VERSION "HNNBNNNYNNNNNNNNNNNNNNNNNNNNNNNNNNNNNNNNNN/4/%%%/4/'%**4NNN///"

NS_ :

BS_:

BU_: BAP_Tester BedienDisp_vo BedienSG_hi CGS DDA Gateway Gateway_PAG GurtMikrofon OTA_FC ZR_High ZR_LIMU ZR_MIB_TOP_ab_Gen3 ZR_Standard

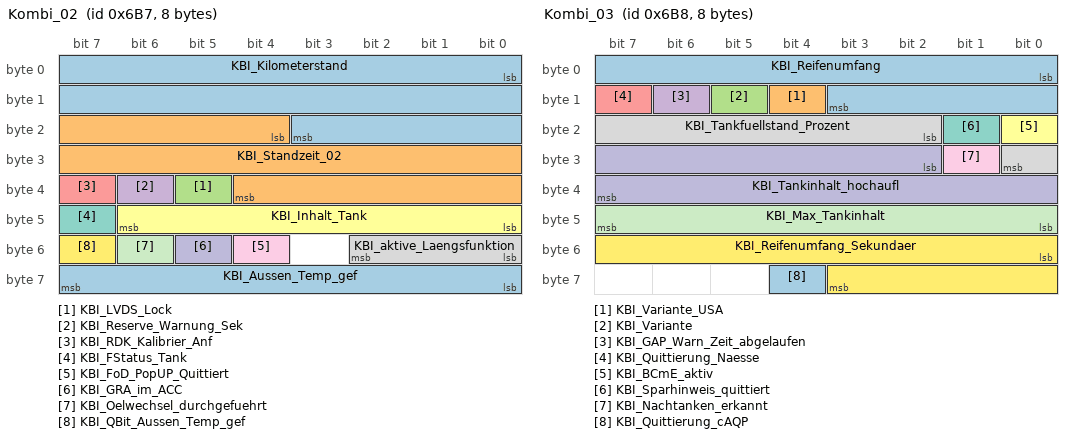
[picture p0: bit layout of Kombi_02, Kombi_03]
BO_ 1719 Kombi_02: 8 Gateway
 SG_ KBI_Kilometerstand : 0|20@1+ (1,0) [0|1048573] "Unit_KiloMeter"  Vector__XXX
 SG_ KBI_Standzeit_02 : 20|17@1+ (1,0) [0|131068] "Unit_Secon"  BedienDisp_vo,BedienSG_hi,ZR_High,ZR_Standard
 SG_ KBI_LVDS_Lock : 37|1@1+ (1.0,0.0) [0.0|1] ""  ZR_High
 SG_ KBI_Reserve_Warnung_Sek : 38|1@1+ (1.0,0.0) [0.0|1] ""  ZR_High,ZR_LIMU,ZR_MIB_TOP_ab_Gen3,ZR_Standard
 SG_ KBI_RDK_Kalibrier_Anf : 39|1@1+ (1.0,0.0) [0.0|1] ""  Vector__XXX
 SG_ KBI_Inhalt_Tank : 40|7@1+ (1,0) [0|125] "Unit_Liter"  Vector__XXX
 SG_ KBI_FStatus_Tank : 47|1@1+ (1.0,0.0) [0.0|1] ""  ZR_High,ZR_LIMU,ZR_MIB_TOP_ab_Gen3,ZR_Standard
 SG_ KBI_aktive_Laengsfunktion : 48|3@1+ (1.0,0.0) [0.0|7] ""  ZR_High
 SG_ KBI_FoD_PopUP_Quittiert : 52|1@1+ (1.0,0.0) [0.0|1] ""  Vector__XXX
 SG_ KBI_GRA_im_ACC : 53|1@1+ (1.0,0.0) [0.0|1] ""  Vector__XXX
 SG_ KBI_Oelwechsel_durchgefuehrt : 54|1@1+ (1.0,0.0) [0.0|1] ""  OTA_FC,ZR_High
 SG_ KBI_QBit_Aussen_Temp_gef : 55|1@1+ (1.0,0.0) [0.0|1] ""  BedienDisp_vo,BedienSG_hi,ZR_High
 SG_ KBI_Aussen_Temp_gef : 56|8@1+ (0.5,-50) [-50.0|75.0] "Unit_DegreCelsi"  BedienDisp_vo,BedienSG_hi,OTA_FC,ZR_Standard

BO_ 1720 Kombi_03: 8 Gateway
 SG_ KBI_Reifenumfang : 0|12@1+ (1,0) [0|4095] "Unit_MilliMeter"  ZR_High,ZR_Standard
 SG_ KBI_Variante_USA : 12|1@1+ (1.0,0.0) [0.0|1] ""  BedienSG_hi,ZR_High
 SG_ KBI_Variante : 13|1@1+ (1.0,0.0) [0.0|1] ""  BedienSG_hi
 SG_ KBI_GAP_Warn_Zeit_abgelaufen : 14|1@1+ (1.0,0.0) [0.0|1] ""  Vector__XXX
 SG_ KBI_Quittierung_Naesse : 15|1@1+ (1.0,0.0) [0.0|1] ""  Vector__XXX
 SG_ KBI_BCmE_aktiv : 16|1@1+ (1.0,0.0) [0.0|1] ""  Vector__XXX
 SG_ KBI_Sparhinweis_quittiert : 17|1@1+ (1.0,0.0) [0.0|1] ""  Vector__XXX
 SG_ KBI_Tankfuellstand_Prozent : 18|7@1+ (1,0) [0|100] "Unit_PerCent"  BedienSG_hi,ZR_High
 SG_ KBI_Nachtanken_erkannt : 25|1@1+ (1.0,0.0) [0.0|1] ""  ZR_High,ZR_MIB_TOP_ab_Gen3
 SG_ KBI_Tankinhalt_hochaufl : 26|14@1+ (0.01,0) [0.00|163.81] "Unit_Liter"  Vector__XXX
 SG_ KBI_Max_Tankinhalt : 40|8@1+ (0.5,0) [0.0|126.5] ""  ZR_High
 SG_ KBI_Reifenumfang_Sekundaer : 48|12@1+ (1,0) [0|4095] "Unit_MilliMeter"  Vector__XXX
 SG_ KBI_Quittierung_cAQP : 60|1@1+ (1.0,0.0) [0.0|1] ""  Vector__XXX

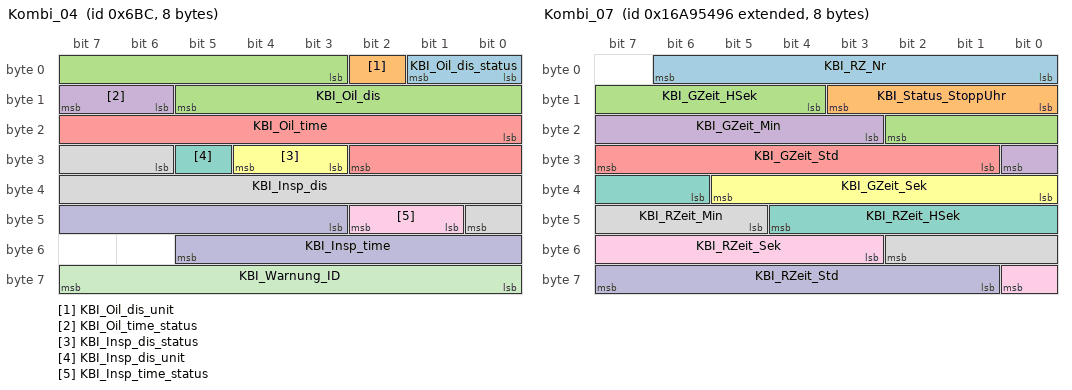
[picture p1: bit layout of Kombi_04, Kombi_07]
BO_ 1724 Kombi_04: 8 Gateway
 SG_ KBI_Oil_dis_status : 0|2@1+ (1.0,0.0) [0.0|3] ""  ZR_High
 SG_ KBI_Oil_dis_unit : 2|1@1+ (1.0,0.0) [0.0|1] ""  ZR_High
 SG_ KBI_Oil_dis : 3|11@1+ (100,0) [0|204700] ""  ZR_High
 SG_ KBI_Oil_time_status : 14|2@1+ (1.0,0.0) [0.0|3] ""  ZR_High
 SG_ KBI_Oil_time : 16|11@1+ (1,0) [0|2047] ""  ZR_High
 SG_ KBI_Insp_dis_status : 27|2@1+ (1.0,0.0) [0.0|3] ""  ZR_High
 SG_ KBI_Insp_dis_unit : 29|1@1+ (1.0,0.0) [0.0|1] ""  ZR_High
 SG_ KBI_Insp_dis : 30|11@1+ (100,0) [0|204700] ""  ZR_High
 SG_ KBI_Insp_time_status : 41|2@1+ (1.0,0.0) [0.0|3] ""  ZR_High
 SG_ KBI_Insp_time : 43|11@1+ (1,0) [0|2047] ""  ZR_High
 SG_ KBI_Warnung_ID : 56|8@1+ (1,0) [0|255] ""  ZR_High

BO_ 2527679638 Kombi_07: 8 Gateway
 SG_ KBI_RZ_Nr : 0|7@1+ (1,0) [0|99] ""  ZR_High,ZR_LIMU,ZR_MIB_TOP_ab_Gen3
 SG_ KBI_Status_StoppUhr : 8|4@1+ (1.0,0.0) [0.0|15] ""  BedienDisp_vo,ZR_High,ZR_LIMU,ZR_MIB_TOP_ab_Gen3
 SG_ KBI_GZeit_HSek : 12|7@1+ (1,0) [0|99] ""  BedienDisp_vo,ZR_High,ZR_LIMU,ZR_MIB_TOP_ab_Gen3
 SG_ KBI_GZeit_Min : 19|6@1+ (1,0) [0|59] "Unit_Minut"  BedienDisp_vo,ZR_High,ZR_LIMU,ZR_MIB_TOP_ab_Gen3
 SG_ KBI_GZeit_Std : 25|7@1+ (1,0) [0|99] "Unit_Hours"  BedienDisp_vo,ZR_High,ZR_LIMU,ZR_MIB_TOP_ab_Gen3
 SG_ KBI_GZeit_Sek : 32|6@1+ (1,0) [0|59] "Unit_Secon"  BedienDisp_vo,ZR_High,ZR_LIMU,ZR_MIB_TOP_ab_Gen3
 SG_ KBI_RZeit_HSek : 38|7@1+ (1,0) [0|99] ""  ZR_High,ZR_LIMU,ZR_MIB_TOP_ab_Gen3
 SG_ KBI_RZeit_Min : 45|6@1+ (1,0) [0|59] "Unit_Minut"  ZR_High,ZR_LIMU,ZR_MIB_TOP_ab_Gen3
 SG_ KBI_RZeit_Sek : 51|6@1+ (1,0) [0|59] "Unit_Secon"  ZR_High,ZR_LIMU,ZR_MIB_TOP_ab_Gen3
 SG_ KBI_RZeit_Std : 57|7@1+ (1,0) [0|99] "Unit_Hours"  ZR_High,ZR_LIMU,ZR_MIB_TOP_ab_Gen3

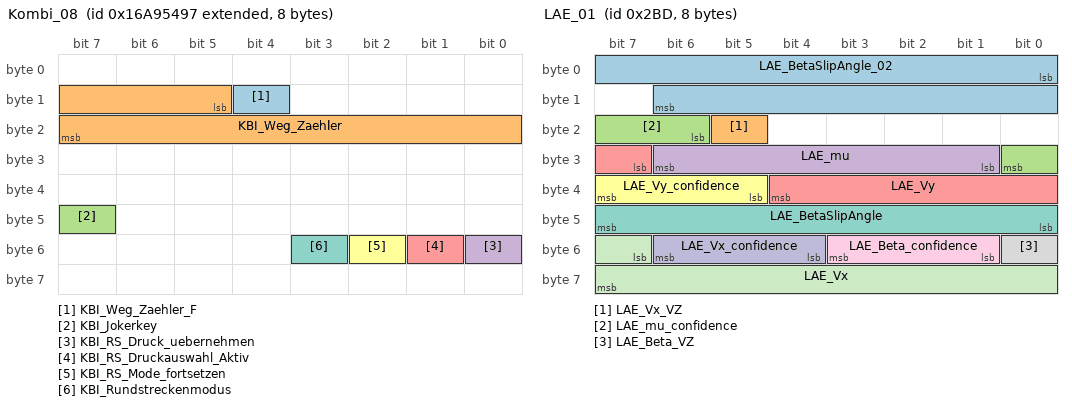
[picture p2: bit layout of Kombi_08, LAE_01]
BO_ 2527679639 Kombi_08: 8 Gateway
 SG_ KBI_Weg_Zaehler_F : 12|1@1+ (1.0,0.0) [0.0|1] ""  ZR_High,ZR_LIMU,ZR_MIB_TOP_ab_Gen3
 SG_ KBI_Weg_Zaehler : 13|11@1+ (1,0) [0|2047] "Unit_Meter"  ZR_High,ZR_LIMU,ZR_MIB_TOP_ab_Gen3
 SG_ KBI_Jokerkey : 47|1@1+ (1.0,0.0) [0.0|1] ""  ZR_LIMU,ZR_MIB_TOP_ab_Gen3
 SG_ KBI_RS_Druck_uebernehmen : 48|1@1+ (1.0,0.0) [0.0|1] ""  Vector__XXX
 SG_ KBI_RS_Druckauswahl_Aktiv : 49|1@1+ (1.0,0.0) [0.0|1] ""  Vector__XXX
 SG_ KBI_RS_Mode_fortsetzen : 50|1@1+ (1.0,0.0) [0.0|1] ""  Vector__XXX
 SG_ KBI_Rundstreckenmodus : 51|1@1+ (1.0,0.0) [0.0|1] ""  Vector__XXX

BO_ 2527679656 Kombi_23: 8 Gateway
 SG_ KBI_StartupAnimation : 61|3@1+ (1.0,0.0) [0.0|7] ""  ZR_High

BO_ 2549875055 KS_AMP_Req: 8 Gateway
 SG_ KS_AMP_Req_Data : 0|64@1+ (1.0,0.0) [0.0|18446744073709551615] ""  ZR_High,ZR_MIB_TOP_ab_Gen3,ZR_Standard

BO_ 2550006127 KS_AMP_Resp: 8 ZR_High
 SG_ KS_AMP_Resp_Data : 0|64@1+ (1.0,0.0) [0.0|18446744073709551615] ""  Gateway,Gateway_PAG

BO_ 2549875059 KS_Info_El_Req: 8 Gateway
 SG_ KS_Info_El_Req_Data : 0|64@1+ (1.0,0.0) [0.0|18446744073709551615] ""  ZR_High,ZR_MIB_TOP_ab_Gen3,ZR_Standard

BO_ 2550006131 KS_Info_El_Resp: 8 ZR_High
 SG_ KS_Info_El_Resp_Data : 0|64@1+ (1.0,0.0) [0.0|18446744073709551615] ""  Gateway,Gateway_PAG

BO_ 2549875056 KS_Laufwerke_Req: 8 Gateway
 SG_ KS_Laufwerke_Req_Data : 0|64@1+ (1.0,0.0) [0.0|18446744073709551615] ""  ZR_High,ZR_MIB_TOP_ab_Gen3,ZR_Standard

BO_ 2550006128 KS_Laufwerke_Resp: 8 ZR_High
 SG_ KS_Laufwerke_Resp_Data : 0|64@1+ (1.0,0.0) [0.0|18446744073709551615] ""  Gateway,Gateway_PAG

BO_ 2549875053 KS_TV_Tuner_Req: 8 Gateway
 SG_ KS_TV_Tuner_Req_Data : 0|64@1+ (1.0,0.0) [0.0|18446744073709551615] ""  ZR_High,ZR_MIB_TOP_ab_Gen3,ZR_Standard

BO_ 2550006125 KS_TV_Tuner_Resp: 8 ZR_High
 SG_ KS_TV_Tuner_Resp_Data : 0|64@1+ (1.0,0.0) [0.0|18446744073709551615] ""  Gateway,Gateway_PAG

BO_ 701 LAE_01: 8 Gateway
 SG_ LAE_BetaSlipAngle_02 : 0|15@1+ (0.01,0) [0.00|327.65] "Unit_DegreOfArc"  ZR_LIMU
 SG_ LAE_Vx_VZ : 21|1@1+ (1.0,0.0) [0.0|1] ""  ZR_LIMU
 SG_ LAE_mu_confidence : 22|3@1+ (1.0,0.0) [0.0|7] ""  ZR_LIMU
 SG_ LAE_mu : 25|6@1+ (0.05,0) [0.00|3.05] "Unit_None"  ZR_LIMU
 SG_ LAE_Vy : 31|6@1+ (0.491803,0) [0.000000|29.999983] "Unit_MeterPerSecon"  ZR_LIMU
 SG_ LAE_Vy_confidence : 37|3@1+ (1.0,0.0) [0.0|7] ""  ZR_LIMU
 SG_ LAE_BetaSlipAngle : 40|8@1+ (0.711462451,0) [0E-9|180.000000103] "Unit_DegreOfArc"  ZR_LIMU
 SG_ LAE_Beta_VZ : 48|1@1+ (1.0,0.0) [0.0|1] ""  ZR_LIMU
 SG_ LAE_Beta_confidence : 49|3@1+ (1.0,0.0) [0.0|7] ""  ZR_LIMU
 SG_ LAE_Vx_confidence : 52|3@1+ (1.0,0.0) [0.0|7] ""  ZR_LIMU
 SG_ LAE_Vx : 55|9@1+ (0.25540275,0) [0E-8|129.99999975] "Unit_MeterPerSecon"  ZR_LIMU

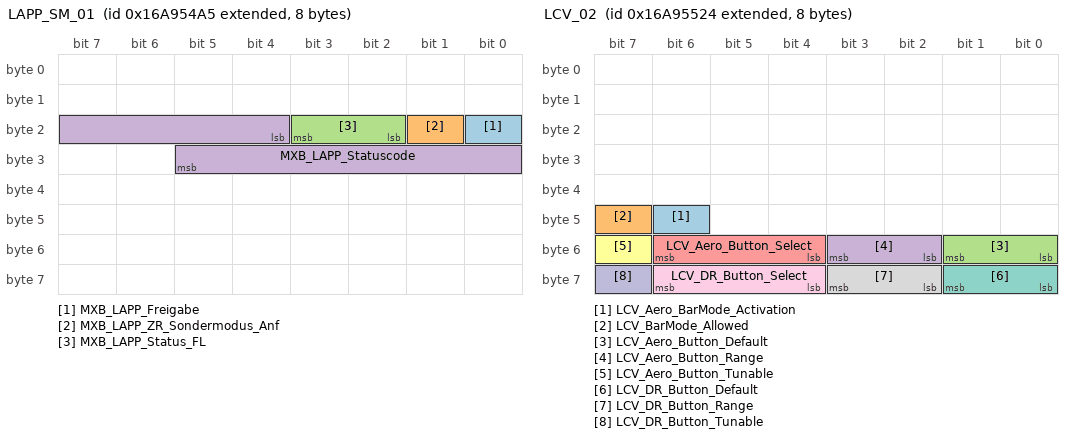
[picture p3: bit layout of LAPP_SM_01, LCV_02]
BO_ 2527679653 LAPP_SM_01: 8 Gateway
 SG_ MXB_LAPP_Freigabe : 16|1@1+ (1.0,0.0) [0.0|1] ""  DDA
 SG_ MXB_LAPP_ZR_Sondermodus_Anf : 17|1@1+ (1.0,0.0) [0.0|1] ""  DDA,ZR_High,ZR_Standard
 SG_ MXB_LAPP_Status_FL : 18|2@1+ (1.0,0.0) [0.0|3] ""  DDA
 SG_ MXB_LAPP_Statuscode : 20|10@1+ (1,0) [0|1023] "Unit_None"  DDA

BO_ 2463978818 LCV_01: 8 Gateway
 SG_ LCV_01_CRC : 0|8@1+ (1,0) [0|255] ""  Vector__XXX
 SG_ LCV_01_BZ : 8|4@1+ (1,0) [0|15] ""  Vector__XXX
 SG_ LCV_ESP_Zuschaltung : 12|1@1+ (1.0,0.0) [0.0|1] ""  Vector__XXX
 SG_ LCV_BrakeGongTemp : 13|1@1+ (1.0,0.0) [0.0|1] ""  Vector__XXX
 SG_ BTM_BrakeSystem_Status : 14|4@1+ (1.0,0.0) [0.0|15] ""  ZR_LIMU
 SG_ BTM_BrakeSystem_Text : 18|4@1+ (1.0,0.0) [0.0|15] ""  ZR_LIMU
 SG_ BTM_BrakeSystem_Warnlampe : 22|1@1+ (1.0,0.0) [0.0|1] ""  ZR_LIMU
 SG_ LCV_Aero_EngineBay_Cooling : 23|1@1+ (1.0,0.0) [0.0|1] ""  Vector__XXX
 SG_ LCV_Aero_Front_System_Status : 24|3@1+ (1.0,0.0) [0.0|7] ""  Vector__XXX
 SG_ LCV_Aero_Rear_System_Status : 27|3@1+ (1.0,0.0) [0.0|7] ""  Vector__XXX
 SG_ LCV_DR_Systemstatus : 30|3@1+ (1.0,0.0) [0.0|7] ""  Vector__XXX
 SG_ LCV_DR_Text : 33|3@1+ (1.0,0.0) [0.0|7] ""  Vector__XXX
 SG_ LCV_DR_Warnlampe : 36|2@1+ (1.0,0.0) [0.0|3] ""  Vector__XXX
 SG_ LCV_Lift_Status : 38|4@1+ (1.0,0.0) [0.0|15] ""  ZR_LIMU
 SG_ LCV_Lift_Text : 42|3@1+ (1.0,0.0) [0.0|7] ""  Vector__XXX
 SG_ LCV_Lift_Warnlampe_Status : 45|2@1+ (1.0,0.0) [0.0|3] ""  Vector__XXX
 SG_ LCV_Aero_Perf_Limit_Speed : 47|8@1+ (1,100) [100|353] "Unit_KiloMeterPerHour"  Vector__XXX
 SG_ LCV_Aero_Perf_Limit : 55|1@1+ (1.0,0.0) [0.0|1] ""  Vector__XXX
 SG_ LCV_HD_offen : 56|1@1+ (1.0,0.0) [0.0|1] ""  ZR_LIMU

BO_ 2527679780 LCV_02: 8 Gateway
 SG_ LCV_Aero_BarMode_Activation : 46|1@1+ (1.0,0.0) [0.0|1] ""  ZR_LIMU
 SG_ LCV_BarMode_Allowed : 47|1@1+ (1.0,0.0) [0.0|1] ""  Vector__XXX
 SG_ LCV_Aero_Button_Default : 48|2@1+ (1.0,0.0) [0.0|3] ""  ZR_LIMU
 SG_ LCV_Aero_Button_Range : 50|2@1+ (1.0,0.0) [0.0|3] ""  ZR_LIMU
 SG_ LCV_Aero_Button_Select : 52|3@1+ (1.0,0.0) [0.0|7] ""  ZR_LIMU
 SG_ LCV_Aero_Button_Tunable : 55|1@1+ (1.0,0.0) [0.0|1] ""  ZR_LIMU
 SG_ LCV_DR_Button_Default : 56|2@1+ (1.0,0.0) [0.0|3] ""  ZR_LIMU
 SG_ LCV_DR_Button_Range : 58|2@1+ (1.0,0.0) [0.0|3] ""  ZR_LIMU
 SG_ LCV_DR_Button_Select : 60|3@1+ (1.0,0.0) [0.0|7] ""  ZR_LIMU
 SG_ LCV_DR_Button_Tunable : 63|1@1+ (1.0,0.0) [0.0|1] ""  ZR_LIMU

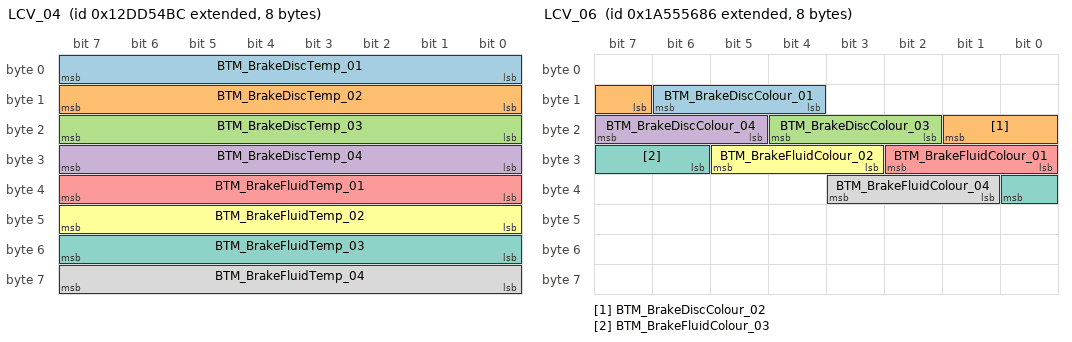
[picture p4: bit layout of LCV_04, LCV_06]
BO_ 2463978684 LCV_04: 8 Gateway
 SG_ BTM_BrakeDiscTemp_01 : 0|8@1+ (10,-30) [-30|2500] "Unit_DegreCelsi"  ZR_LIMU
 SG_ BTM_BrakeDiscTemp_02 : 8|8@1+ (10,-30) [-30|2500] "Unit_DegreCelsi"  ZR_LIMU
 SG_ BTM_BrakeDiscTemp_03 : 16|8@1+ (10,-30) [-30|2500] "Unit_DegreCelsi"  ZR_LIMU
 SG_ BTM_BrakeDiscTemp_04 : 24|8@1+ (10,-30) [-30|2500] "Unit_DegreCelsi"  ZR_LIMU
 SG_ BTM_BrakeFluidTemp_01 : 32|8@1+ (2,-30) [-30|476] "Unit_DegreCelsi"  ZR_LIMU
 SG_ BTM_BrakeFluidTemp_02 : 40|8@1+ (2,-30) [-30|476] "Unit_DegreCelsi"  ZR_LIMU
 SG_ BTM_BrakeFluidTemp_03 : 48|8@1+ (2,-30) [-30|476] "Unit_DegreCelsi"  ZR_LIMU
 SG_ BTM_BrakeFluidTemp_04 : 56|8@1+ (2,-30) [-30|476] "Unit_DegreCelsi"  ZR_LIMU

BO_ 548 LCV_05: 8 Gateway
 SG_ LCV_Aero_Front_Ratio : 12|7@1+ (1,0) [0|125] "Unit_None"  ZR_LIMU
 SG_ LCV_Aero_Long_Ratio : 19|7@1+ (1,0) [0|125] "Unit_None"  ZR_LIMU

BO_ 2589283974 LCV_06: 8 Gateway
 SG_ BTM_BrakeDiscColour_01 : 12|3@1+ (1.0,0.0) [0.0|7] ""  ZR_LIMU
 SG_ BTM_BrakeDiscColour_02 : 15|3@1+ (1.0,0.0) [0.0|7] ""  ZR_LIMU
 SG_ BTM_BrakeDiscColour_03 : 18|3@1+ (1.0,0.0) [0.0|7] ""  ZR_LIMU
 SG_ BTM_BrakeDiscColour_04 : 21|3@1+ (1.0,0.0) [0.0|7] ""  ZR_LIMU
 SG_ BTM_BrakeFluidColour_01 : 24|3@1+ (1.0,0.0) [0.0|7] ""  ZR_LIMU
 SG_ BTM_BrakeFluidColour_02 : 27|3@1+ (1.0,0.0) [0.0|7] ""  ZR_LIMU
 SG_ BTM_BrakeFluidColour_03 : 30|3@1+ (1.0,0.0) [0.0|7] ""  ZR_LIMU
 SG_ BTM_BrakeFluidColour_04 : 33|3@1+ (1.0,0.0) [0.0|7] ""  ZR_LIMU

BO_ 981 Licht_Anf_01: 8 Gateway
 SG_ Licht_Anf_01_CRC : 0|8@1+ (1,0) [0|255] ""  Vector__XXX
 SG_ Licht_Anf_01_BZ : 8|4@1+ (1,0) [0|15] ""  Vector__XXX
 SG_ BCM1_Kurvenlicht_links_Anf : 12|1@1+ (1.0,0.0) [0.0|1] ""  ZR_High
 SG_ BCM1_Kurvenlicht_rechts_Anf : 13|1@1+ (1.0,0.0) [0.0|1] ""  ZR_High
 SG_ BCM1_Standlicht_Anf : 14|1@1+ (1.0,0.0) [0.0|1] ""  ZR_High
 SG_ BCM1_Abblendlicht_Anf : 15|1@1+ (1.0,0.0) [0.0|1] ""  OTA_FC,ZR_High
 SG_ BCM1_Fernlicht_Anf : 16|1@1+ (1.0,0.0) [0.0|1] ""  ZR_High
 SG_ BCM1_Nebellicht_Anf : 17|1@1+ (1.0,0.0) [0.0|1] ""  ZR_High
 SG_ BCM1_Parklicht_li_Anf : 18|1@1+ (1.0,0.0) [0.0|1] ""  ZR_High
 SG_ BCM1_Parklicht_re_Anf : 19|1@1+ (1.0,0.0) [0.0|1] ""  ZR_High
 SG_ BCM1_Nebelschluss_Ahg_Anf : 20|1@1+ (1.0,0.0) [0.0|1] ""  ZR_High
 SG_ BCM1_Nebelschluss_Fzg_Anf : 21|1@1+ (1.0,0.0) [0.0|1] ""  ZR_High
 SG_ BCM1_Schlusslicht_Anf : 22|1@1+ (1.0,0.0) [0.0|1] ""  ZR_High
 SG_ BCM_Rueckfahrlicht_Anf : 23|1@1+ (1.0,0.0) [0.0|1] ""  ZR_High,ZR_MIB_TOP_ab_Gen3,ZR_Standard
 SG_ BCM1_Signaturlicht_Anf : 24|1@1+ (1.0,0.0) [0.0|1] ""  Vector__XXX
 SG_ BCM1_Umfeldleuchten_Anf : 25|1@1+ (1.0,0.0) [0.0|1] ""  ZR_High
 SG_ BCM1_Tagfahrlicht_Anf : 26|1@1+ (1.0,0.0) [0.0|1] ""  ZR_High
 SG_ BCM1_Regenlicht_Anf : 27|1@1+ (1.0,0.0) [0.0|1] ""  ZR_High
 SG_ BCM1_Autobahnlicht_Anf : 28|1@1+ (1.0,0.0) [0.0|1] ""  ZR_High
 SG_ BCM1_Touristen_Licht_Anf : 29|1@1+ (1.0,0.0) [0.0|1] ""  ZR_High
 SG_ BCM1_CH_aktiv : 30|1@1+ (1.0,0.0) [0.0|1] ""  ZR_High
 SG_ BCM1_LH_aktiv : 31|1@1+ (1.0,0.0) [0.0|1] ""  ZR_High
 SG_ BCM1_Gleitende_Leuchtw_Anf : 32|1@1+ (1.0,0.0) [0.0|1] ""  ZR_High
 SG_ BCM1_GLW_Fernlicht_Anf : 33|1@1+ (1.0,0.0) [0.0|1] ""  ZR_High
 SG_ BCM1_Adaptive_Lichtvert_Anf : 34|1@1+ (1.0,0.0) [0.0|1] ""  ZR_High
 SG_ BCM1_FoD_Sperrung_WiBli : 35|2@1+ (1.0,0.0) [0.0|3] ""  Vector__XXX
 SG_ BCM1_FOD_Sperrung_Animationen_HL : 37|2@1+ (1.0,0.0) [0.0|3] ""  Vector__XXX
 SG_ BCM1_Animationssperrung : 39|1@1+ (1.0,0.0) [0.0|1] ""  Vector__XXX
 SG_ BCM1_CH_LH_aktiv : 40|1@1+ (1.0,0.0) [0.0|1] ""  ZR_High
 SG_ BCM1_Allwetterlicht_Anf : 41|1@1+ (1.0,0.0) [0.0|1] ""  ZR_High
 SG_ BCM1_Schlusslicht_Signatur : 60|4@1+ (1.0,0.0) [0.0|15] ""  Vector__XXX

BO_ 982 Licht_hinten_01: 8 Gateway
 SG_ BCM2_Bremsl_durch_ECD : 5|1@1+ (1.0,0.0) [0.0|1] ""  OTA_FC,ZR_High
 SG_ LH_Aussenlicht_def : 7|1@1+ (1.0,0.0) [0.0|1] ""  ZR_High
 SG_ LH_Standlicht_H_aktiv : 8|1@1+ (1.0,0.0) [0.0|1] ""  OTA_FC,ZR_High
 SG_ LH_Parklicht_HL_aktiv : 9|1@1+ (1.0,0.0) [0.0|1] ""  OTA_FC,ZR_High
 SG_ LH_Parklicht_HR_aktiv : 10|1@1+ (1.0,0.0) [0.0|1] ""  OTA_FC,ZR_High
 SG_ LH_Bremslicht_H_aktiv : 11|1@1+ (1.0,0.0) [0.0|1] ""  OTA_FC,ZR_High
 SG_ LH_Nebelschluss_aktiv : 12|1@1+ (1.0,0.0) [0.0|1] ""  OTA_FC,ZR_High
 SG_ LH_Rueckfahrlicht_aktiv : 13|1@1+ (1.0,0.0) [0.0|1] ""  OTA_FC,ZR_High
 SG_ LH_Blinker_HL_akt : 14|1@1+ (1.0,0.0) [0.0|1] ""  OTA_FC,ZR_High
 SG_ LH_Blinker_HR_akt : 15|1@1+ (1.0,0.0) [0.0|1] ""  OTA_FC,ZR_High
 SG_ LH_Blinker_li_def : 16|1@1+ (1.0,0.0) [0.0|1] ""  ZR_High
 SG_ LH_Bremsl_li_def : 17|1@1+ (1.0,0.0) [0.0|1] ""  ZR_High
 SG_ LH_Schlusslicht_li_def : 18|1@1+ (1.0,0.0) [0.0|1] ""  ZR_High
 SG_ LH_Rueckf_li_def : 19|1@1+ (1.0,0.0) [0.0|1] ""  ZR_High
 SG_ LH_Nebel_li_def : 20|1@1+ (1.0,0.0) [0.0|1] ""  ZR_High
 SG_ LH_Schluss_Brems_Nebel_li_def : 21|1@1+ (1.0,0.0) [0.0|1] ""  ZR_High
 SG_ LH_Schluss_Brems_Nebel_re_def : 22|1@1+ (1.0,0.0) [0.0|1] ""  ZR_High
 SG_ LH_Zusatzschlussl_def : 23|1@1+ (1.0,0.0) [0.0|1] ""  Vector__XXX
 SG_ LH_Schluss_Brems_li_def : 24|1@1+ (1.0,0.0) [0.0|1] ""  ZR_High
 SG_ LH_Schluss_Nebel_li_def : 25|1@1+ (1.0,0.0) [0.0|1] ""  ZR_High
 SG_ LH_SL_BRL_BLK_li_def : 26|1@1+ (1.0,0.0) [0.0|1] ""  ZR_High
 SG_ LH_Brems_Blk_li_def : 27|1@1+ (1.0,0.0) [0.0|1] ""  Vector__XXX
 SG_ LH_Diag_Status_re_def : 28|1@1+ (1.0,0.0) [0.0|1] ""  ZR_High
 SG_ LH_Diag_Status_li_def : 29|1@1+ (1.0,0.0) [0.0|1] ""  ZR_High
 SG_ LH_Diag_LED_li_def : 30|1@1+ (1.0,0.0) [0.0|1] ""  ZR_High
 SG_ LH_Diag_LED_re_def : 31|1@1+ (1.0,0.0) [0.0|1] ""  ZR_High
 SG_ LH_Blinker_re_def : 32|1@1+ (1.0,0.0) [0.0|1] ""  ZR_High
 SG_ LH_Bremsl_re_def : 33|1@1+ (1.0,0.0) [0.0|1] ""  ZR_High
 SG_ LH_Schlusslicht_re_def : 34|1@1+ (1.0,0.0) [0.0|1] ""  ZR_High
 SG_ LH_Rueckf_re_def : 35|1@1+ (1.0,0.0) [0.0|1] ""  ZR_High
 SG_ LH_Nebel_re_def : 36|1@1+ (1.0,0.0) [0.0|1] ""  ZR_High
 SG_ LH_Schluss_Brems_mi_def : 37|1@1+ (1.0,0.0) [0.0|1] ""  Vector__XXX
 SG_ LH_Schluss_Brems_re_def : 40|1@1+ (1.0,0.0) [0.0|1] ""  ZR_High
 SG_ LH_Schluss_Nebel_re_def : 41|1@1+ (1.0,0.0) [0.0|1] ""  ZR_High
 SG_ LH_SL_BRL_BLK_re_def : 42|1@1+ (1.0,0.0) [0.0|1] ""  ZR_High
 SG_ LH_Brems_Blk_re_def : 43|1@1+ (1.0,0.0) [0.0|1] ""  ZR_High
 SG_ LH_Kennzl_def : 48|1@1+ (1.0,0.0) [0.0|1] ""  ZR_High
 SG_ LH_3_Bremsl_def : 49|1@1+ (1.0,0.0) [0.0|1] ""  ZR_High
 SG_ LH_Nebel_mi_def : 50|1@1+ (1.0,0.0) [0.0|1] ""  ZR_High
 SG_ LH_Rueckf_mi_def : 51|1@1+ (1.0,0.0) [0.0|1] ""  ZR_High
 SG_ LH_Schlusslicht_mi_def : 52|1@1+ (1.0,0.0) [0.0|1] ""  Vector__XXX
 SG_ LH_Bremsl_mi_def : 53|1@1+ (1.0,0.0) [0.0|1] ""  Vector__XXX
 SG_ LH_Bremsl_li_ges_def : 54|1@1+ (1.0,0.0) [0.0|1] ""  ZR_High
 SG_ LH_Bremsl_re_ges_def : 55|1@1+ (1.0,0.0) [0.0|1] ""  ZR_High

BO_ 1624 Licht_vorne_01: 8 Gateway
 SG_ Licht_Vorne_01_CRC : 0|8@1+ (1,0) [0|255] ""  Vector__XXX
 SG_ Licht_Vorne_01_BZ : 8|4@1+ (1,0) [0|15] ""  Vector__XXX
 SG_ LV_Standlicht_Anzeige : 12|1@1+ (1.0,0.0) [0.0|1] ""  OTA_FC,ZR_High
 SG_ LV_Abblendlicht_Anzeige : 13|1@1+ (1.0,0.0) [0.0|1] ""  OTA_FC,ZR_High
 SG_ LV_Fernlicht_Anzeige : 14|1@1+ (1.0,0.0) [0.0|1] ""  OTA_FC,ZR_High
 SG_ LV_Nebellicht_Anzeige : 15|1@1+ (1.0,0.0) [0.0|1] ""  OTA_FC,ZR_High
 SG_ LV_Nebelschlusslicht_Anzeige : 16|1@1+ (1.0,0.0) [0.0|1] ""  OTA_FC,ZR_High
 SG_ LV_Tagfahrlicht_Anzeige : 17|1@1+ (1.0,0.0) [0.0|1] ""  BedienSG_hi,OTA_FC,ZR_High
 SG_ LV_AFL_aktiv_Anzeige : 18|1@1+ (1.0,0.0) [0.0|1] ""  BedienSG_hi,OTA_FC,ZR_High
 SG_ LV_AFL_defekt : 19|1@1+ (1.0,0.0) [0.0|1] ""  ZR_High
 SG_ LV_Blinker_li_def : 20|1@1+ (1.0,0.0) [0.0|1] ""  ZR_High
 SG_ LV_Standlicht_li_def : 21|1@1+ (1.0,0.0) [0.0|1] ""  ZR_High
 SG_ LV_Abblendlicht_li_def : 22|1@1+ (1.0,0.0) [0.0|1] ""  ZR_High
 SG_ LV_Fernlicht_li_def : 23|1@1+ (1.0,0.0) [0.0|1] ""  ZR_High
 SG_ LV_Nebellicht_li_def : 24|1@1+ (1.0,0.0) [0.0|1] ""  ZR_High
 SG_ LV_Blk_li_Seite_def : 25|1@1+ (1.0,0.0) [0.0|1] ""  ZR_High
 SG_ LV_Tagfahrlicht_li_def : 26|1@1+ (1.0,0.0) [0.0|1] ""  ZR_High
 SG_ LV_FLA_aktiv_Anzeige : 27|1@1+ (1.0,0.0) [0.0|1] ""  OTA_FC,ZR_High
 SG_ LV_FLA_defekt : 28|1@1+ (1.0,0.0) [0.0|1] ""  ZR_High
 SG_ LV_FLA_Sensor_blockiert : 29|1@1+ (1.0,0.0) [0.0|1] ""  OTA_FC,ZR_High
 SG_ LV_Blinker_re_def : 30|1@1+ (1.0,0.0) [0.0|1] ""  ZR_High
 SG_ LV_Standlicht_re_def : 31|1@1+ (1.0,0.0) [0.0|1] ""  ZR_High
 SG_ LV_Abblendlicht_re_def : 32|1@1+ (1.0,0.0) [0.0|1] ""  ZR_High
 SG_ LV_Fernlicht_re_def : 33|1@1+ (1.0,0.0) [0.0|1] ""  ZR_High
 SG_ LV_Nebellicht_re_def : 34|1@1+ (1.0,0.0) [0.0|1] ""  ZR_High
 SG_ LV_Blk_re_Seite_def : 35|1@1+ (1.0,0.0) [0.0|1] ""  ZR_High
 SG_ LV_Tagfahrlicht_re_def : 36|1@1+ (1.0,0.0) [0.0|1] ""  ZR_High
 SG_ LV_Aussenlicht_def : 37|1@1+ (1.0,0.0) [0.0|1] ""  ZR_High
 SG_ LV_Abblendlicht_TFL_li_def : 38|1@1+ (1.0,0.0) [0.0|1] ""  ZR_High
 SG_ LV_Nebellicht_TFL_li_def : 39|1@1+ (1.0,0.0) [0.0|1] ""  ZR_High
 SG_ LV_Standlicht_TFL_li_def : 40|1@1+ (1.0,0.0) [0.0|1] ""  ZR_High
 SG_ LV_Abblend_Fernlicht_li_def : 41|1@1+ (1.0,0.0) [0.0|1] ""  ZR_High
 SG_ LV_Abblendlicht_TFL_re_def : 42|1@1+ (1.0,0.0) [0.0|1] ""  ZR_High
 SG_ LV_Nebellicht_TFL_re_def : 43|1@1+ (1.0,0.0) [0.0|1] ""  ZR_High
 SG_ LV_Standlicht_TFL_re_def : 44|1@1+ (1.0,0.0) [0.0|1] ""  ZR_High
 SG_ LV_Abblend_Fernlicht_re_def : 45|1@1+ (1.0,0.0) [0.0|1] ""  ZR_High
 SG_ LV_Abbiegelicht_li_def : 46|1@1+ (1.0,0.0) [0.0|1] ""  Vector__XXX
 SG_ LV_Abbiegelicht_re_def : 47|1@1+ (1.0,0.0) [0.0|1] ""  Vector__XXX
 SG_ BCM1_Linksverkehr : 48|1@1+ (1.0,0.0) [0.0|1] ""  OTA_FC,ZR_High
 SG_ BCM1_Licht_Dunkelheit_aktiv : 49|1@1+ (1.0,0.0) [0.0|1] ""  OTA_FC,ZR_High
 SG_ LV_LED_Scheinwerfer_li_def : 50|1@1+ (1.0,0.0) [0.0|1] ""  Vector__XXX
 SG_ LV_LED_Scheinwerfer_re_def : 51|1@1+ (1.0,0.0) [0.0|1] ""  Vector__XXX
 SG_ LV_Blinker_VL_aktiv : 52|1@1+ (1.0,0.0) [0.0|1] ""  OTA_FC,ZR_High
 SG_ LV_Blinker_VR_aktiv : 53|1@1+ (1.0,0.0) [0.0|1] ""  OTA_FC,ZR_High
 SG_ LV_MXB_Status_Anzeige : 54|2@1+ (1.0,0.0) [0.0|3] ""  Vector__XXX

BO_ 1321 Lift_01: 8 Gateway
 SG_ Lift_Charisma_FahrPr : 15|3@1+ (1.0,0.0) [0.0|7] ""  Vector__XXX
 SG_ Lift_Charisma_Status : 18|2@1+ (1.0,0.0) [0.0|3] ""  Vector__XXX
 SG_ Lift_Charisma_Umschaltung : 20|2@1+ (1.0,0.0) [0.0|3] ""  Vector__XXX
 SG_ Lift_Anforderung_EFP : 22|2@1+ (1.0,0.0) [0.0|3] ""  Vector__XXX
 SG_ Lift_ESP_Zuschaltung : 24|1@1+ (1.0,0.0) [0.0|1] ""  Vector__XXX
 SG_ Lift_Meldung_12 : 40|1@1+ (1.0,0.0) [0.0|1] ""  Vector__XXX
 SG_ Lift_Meldung_13 : 41|1@1+ (1.0,0.0) [0.0|1] ""  Vector__XXX
 SG_ Lift_Meldung_14 : 42|1@1+ (1.0,0.0) [0.0|1] ""  Vector__XXX
 SG_ Lift_LED : 43|2@1+ (1.0,0.0) [0.0|3] ""  BedienDisp_vo
 SG_ Lift_Position : 45|3@1+ (1.0,0.0) [0.0|7] ""  OTA_FC
 SG_ Lift_Meldung_01 : 48|1@1+ (1.0,0.0) [0.0|1] ""  Vector__XXX
 SG_ Lift_Meldung_02 : 49|1@1+ (1.0,0.0) [0.0|1] ""  Vector__XXX
 SG_ Lift_Meldung_03 : 50|1@1+ (1.0,0.0) [0.0|1] ""  Vector__XXX
 SG_ Lift_Meldung_04 : 51|1@1+ (1.0,0.0) [0.0|1] ""  Vector__XXX
 SG_ Lift_Meldung_05 : 52|1@1+ (1.0,0.0) [0.0|1] ""  Vector__XXX
 SG_ Lift_Meldung_06 : 53|1@1+ (1.0,0.0) [0.0|1] ""  Vector__XXX
 SG_ Lift_Meldung_07 : 54|1@1+ (1.0,0.0) [0.0|1] ""  Vector__XXX
 SG_ Lift_Meldung_08 : 55|1@1+ (1.0,0.0) [0.0|1] ""  Vector__XXX
 SG_ Lift_Meldung_09 : 56|1@1+ (1.0,0.0) [0.0|1] ""  Vector__XXX
 SG_ Lift_Meldung_10 : 57|1@1+ (1.0,0.0) [0.0|1] ""  Vector__XXX
 SG_ Lift_Meldung_11 : 58|1@1+ (1.0,0.0) [0.0|1] ""  Vector__XXX
 SG_ Lift_SpannungsAnf : 59|2@1+ (1.0,0.0) [0.0|3] ""  Vector__XXX
 SG_ Lift_StartStopp_Info : 61|2@1+ (1.0,0.0) [0.0|3] ""  Vector__XXX

BO_ 822 LR_HZG_01: 2 Gateway
 SG_ LR_HZG_Temp_Sensor : 0|8@1+ (1,-50) [-50|104] "Unit_DegreCelsi"  ZR_High
 SG_ LR_HZG_Taster_on_off : 8|1@1+ (1.0,0.0) [0.0|1] ""  ZR_High

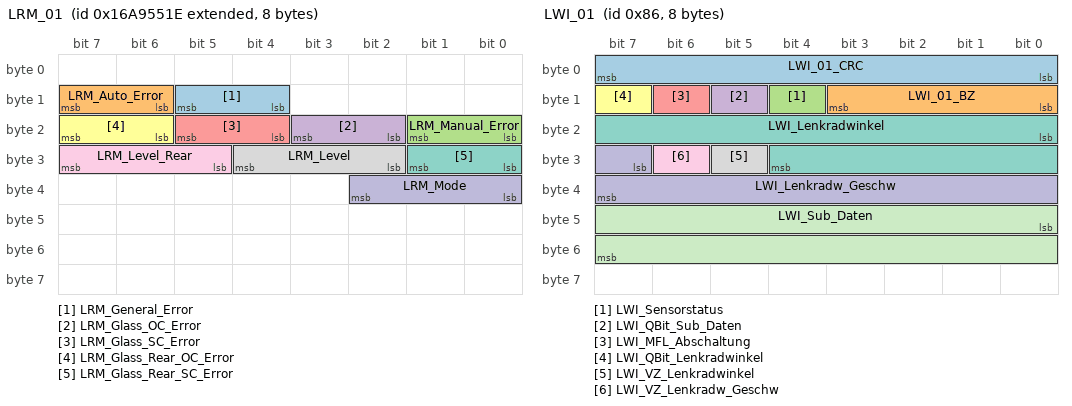
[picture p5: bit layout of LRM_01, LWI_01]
BO_ 2527679774 LRM_01: 8 Gateway
 SG_ LRM_General_Error : 12|2@1+ (1.0,0.0) [0.0|3] ""  ZR_LIMU
 SG_ LRM_Auto_Error : 14|2@1+ (1.0,0.0) [0.0|3] ""  ZR_LIMU
 SG_ LRM_Manual_Error : 16|2@1+ (1.0,0.0) [0.0|3] ""  ZR_LIMU
 SG_ LRM_Glass_OC_Error : 18|2@1+ (1.0,0.0) [0.0|3] ""  ZR_LIMU
 SG_ LRM_Glass_SC_Error : 20|2@1+ (1.0,0.0) [0.0|3] ""  ZR_LIMU
 SG_ LRM_Glass_Rear_OC_Error : 22|2@1+ (1.0,0.0) [0.0|3] ""  ZR_LIMU
 SG_ LRM_Glass_Rear_SC_Error : 24|2@1+ (1.0,0.0) [0.0|3] ""  ZR_LIMU
 SG_ LRM_Level : 26|3@1+ (1.0,0.0) [0.0|7] ""  ZR_LIMU
 SG_ LRM_Level_Rear : 29|3@1+ (1.0,0.0) [0.0|7] ""  ZR_LIMU
 SG_ LRM_Mode : 32|3@1+ (1.0,0.0) [0.0|7] ""  ZR_LIMU

BO_ 134 LWI_01: 8 Gateway
 SG_ LWI_01_CRC : 0|8@1+ (1,0) [0|255] ""  Vector__XXX
 SG_ LWI_01_BZ : 8|4@1+ (1,0) [0|15] ""  Vector__XXX
 SG_ LWI_Sensorstatus : 12|1@1+ (1.0,0.0) [0.0|1] ""  ZR_High,ZR_LIMU,ZR_MIB_TOP_ab_Gen3,ZR_Standard
 SG_ LWI_QBit_Sub_Daten : 13|1@1+ (1.0,0.0) [0.0|1] ""  ZR_High
 SG_ LWI_MFL_Abschaltung : 14|1@1+ (1.0,0.0) [0.0|1] ""  ZR_High
 SG_ LWI_QBit_Lenkradwinkel : 15|1@1+ (1.0,0.0) [0.0|1] ""  ZR_High,ZR_LIMU,ZR_MIB_TOP_ab_Gen3,ZR_Standard
 SG_ LWI_Lenkradwinkel : 16|13@1+ (0.1,0) [0.0|800.0] "Unit_DegreOfArc"  OTA_FC,ZR_High,ZR_LIMU,ZR_MIB_TOP_ab_Gen3,ZR_Standard
 SG_ LWI_VZ_Lenkradwinkel : 29|1@1+ (1.0,0.0) [0.0|1] ""  OTA_FC,ZR_High,ZR_LIMU,ZR_MIB_TOP_ab_Gen3,ZR_Standard
 SG_ LWI_VZ_Lenkradw_Geschw : 30|1@1+ (1.0,0.0) [0.0|1] ""  ZR_High
 SG_ LWI_Lenkradw_Geschw : 31|9@1+ (5,0) [0|2500] "Unit_DegreOfArcPerSecon"  OTA_FC,ZR_High
 SG_ LWI_Sub_Daten : 40|16@1+ (1,0) [0|65535] ""  Vector__XXX

BO_ 917 LWR_AFS_01: 8 Gateway
 SG_ AFS_Abbiegelicht_li_Anf : 0|1@1+ (1.0,0.0) [0.0|1] ""  ZR_High
 SG_ AFS_Abbiegelicht_re_Anf : 1|1@1+ (1.0,0.0) [0.0|1] ""  ZR_High
 SG_ AFS_Abbiegelicht_Dimm_Anf : 2|1@1+ (1.0,0.0) [0.0|1] ""  ZR_High
 SG_ AFS_Verfuegbarkeit_GLW : 3|1@1+ (1.0,0.0) [0.0|1] ""  ZR_High
 SG_ AFS_Status_adaptive_LV : 4|1@1+ (1.0,0.0) [0.0|1] ""  ZR_High
 SG_ AFS_Fernlicht_li_defekt : 5|1@1+ (1.0,0.0) [0.0|1] ""  ZR_High
 SG_ AFS_Fernlicht_re_defekt : 6|1@1+ (1.0,0.0) [0.0|1] ""  ZR_High
 SG_ AFS_Fernlicht_Status : 7|1@1+ (1.0,0.0) [0.0|1] ""  ZR_High
 SG_ LWR_AFS_01_BZ : 8|4@1+ (1,0) [0|15] ""  Vector__XXX
 SG_ AFS_Lampe : 12|1@1+ (1.0,0.0) [0.0|1] ""  ZR_High
 SG_ LWR_Lampe : 13|1@1+ (1.0,0.0) [0.0|1] ""  ZR_High
 SG_ AFS_Fehlertext : 14|1@1+ (1.0,0.0) [0.0|1] ""  ZR_High
 SG_ AFS_LED_Blinkmode : 15|1@1+ (1.0,0.0) [0.0|1] ""  Vector__XXX
 SG_ LWR_Touristenmodus_aktiv : 16|1@1+ (1.0,0.0) [0.0|1] ""  ZR_High
 SG_ AFS_Charisma_FahrPr : 17|4@1+ (1.0,0.0) [0.0|15] ""  Vector__XXX
 SG_ AFS_Charisma_Status : 21|2@1+ (1.0,0.0) [0.0|3] ""  Vector__XXX
 SG_ LWR_Sicherheitsposition_re : 23|1@1+ (1.0,0.0) [0.0|1] ""  ZR_High
 SG_ AFS_Allwetterlicht : 24|1@1+ (1.0,0.0) [0.0|1] ""  ZR_High
 SG_ LWR_Touristenmodus_verbaut : 25|1@1+ (1.0,0.0) [0.0|1] ""  ZR_High
 SG_ AFS_adaptive_LV_verbaut : 26|1@1+ (1.0,0.0) [0.0|1] ""  ZR_High
 SG_ LWR_Reisemodus_Texte : 27|2@1+ (1.0,0.0) [0.0|3] ""  ZR_High
 SG_ GLW_Sensor_blockiert : 29|1@1+ (1.0,0.0) [0.0|1] ""  ZR_High
 SG_ AFS_Charisma_Umschaltung : 30|2@1+ (1.0,0.0) [0.0|3] ""  Vector__XXX
 SG_ LWR_Pos_Schrittmotor : 32|8@1+ (0.4,0) [0.0|100.0] "Unit_PerCent"  Vector__XXX
 SG_ LWR_Hoehenwert_VL : 40|8@1+ (1,-127) [-127|126] ""  ZR_High
 SG_ LWR_Hoehenwert_HL : 48|8@1+ (1,-127) [-127|126] ""  ZR_High
 SG_ AFS_Ersatzlicht_Links : 56|1@1+ (1.0,0.0) [0.0|1] ""  ZR_High
 SG_ AFS_Ersatzlicht_Rechts : 57|1@1+ (1.0,0.0) [0.0|1] ""  ZR_High
 SG_ LWR_AFS_Grundeinstellung : 58|1@1+ (1.0,0.0) [0.0|1] ""  ZR_High
 SG_ LWR_AFS_Parametrisierung : 59|1@1+ (1.0,0.0) [0.0|1] ""  ZR_High
 SG_ LWR_Initialisierungslauf : 60|1@1+ (1.0,0.0) [0.0|1] ""  ZR_High
 SG_ LWR_Sicherheitsposition_li : 61|1@1+ (1.0,0.0) [0.0|1] ""  ZR_High
 SG_ LWR_Modus : 62|1@1+ (1.0,0.0) [0.0|1] ""  ZR_High

BO_ 1153 MainUnit_01: 8 ZR_High
 SG_ ZR_LoGeWa_Event_Kombiwarnung : 0|4@1+ (1.0,0.0) [0.0|15] ""  Gateway,Gateway_PAG
 SG_ Nav_FoD_Status : 4|3@1+ (1.0,0.0) [0.0|7] ""  Gateway,Gateway_PAG
 SG_ MIB_Tongenerator_PH_verfuegbar : 9|3@1+ (1.0,0.0) [0.0|7] ""  Gateway,Gateway_PAG
 SG_ MMI_Counter_Bedienevent : 12|4@1+ (1.0,0.0) [0.0|15] ""  Gateway,Gateway_PAG
 SG_ DSSS_Warning : 16|5@1+ (1.0,0.0) [0.0|31] ""  Gateway,Gateway_PAG
 SG_ ZR_Kindersicherung_RSE : 21|1@1+ (1.0,0.0) [0.0|1] ""  Gateway,Gateway_PAG
 SG_ ZR_RSE_aktivieren : 22|1@1+ (1.0,0.0) [0.0|1] ""  Gateway,Gateway_PAG
 SG_ MMI_SDS_aktiv : 23|1@1+ (1.0,0.0) [0.0|1] ""  Gateway,Gateway_PAG
 SG_ MU_SecondDisplay : 24|3@1+ (1.0,0.0) [0.0|7] ""  Gateway,Gateway_PAG
 SG_ MMI_Telefon_aktiv : 27|1@1+ (1.0,0.0) [0.0|1] ""  Gateway,Gateway_PAG
 SG_ MMI_Gurt_Mic_ref : 28|1@1+ (1.0,0.0) [0.0|1] ""  Gateway,Gateway_PAG,GurtMikrofon
 SG_ ZR_Sta_Inszenierung : 29|2@1+ (1.0,0.0) [0.0|3] ""  Gateway,Gateway_PAG
 SG_ MMI_Gauges_active : 31|1@1+ (1.0,0.0) [0.0|1] ""  BedienDisp_vo,Gateway,Gateway_PAG
 SG_ MU_Update_Time : 32|8@1+ (0.1,0) [0.0|25.5] "Unit_Hours"  Gateway,Gateway_PAG
 SG_ ZR_MXB_Manoever_Ansage : 42|2@1+ (1.0,0.0) [0.0|3] ""  Gateway,Gateway_PAG
 SG_ ZR_LAPP_Sondermodus_Status : 44|2@1+ (1.0,0.0) [0.0|3] ""  DDA,Gateway,Gateway_PAG
 SG_ MMI_StartStopp_Info : 46|2@1+ (1.0,0.0) [0.0|3] ""  Gateway,Gateway_PAG
 SG_ ZR_Parken_Sondermodus : 48|4@1+ (1.0,0.0) [0.0|15] ""  DDA,Gateway,Gateway_PAG
 SG_ ZR_Rundenbewertung : 52|4@1+ (1.0,0.0) [0.0|15] ""  Gateway,Gateway_PAG
 SG_ ZR_Rundenfortschritt : 56|8@1+ (0.5,0) [0.0|100.0] "Unit_PerCent"  Gateway,Gateway_PAG

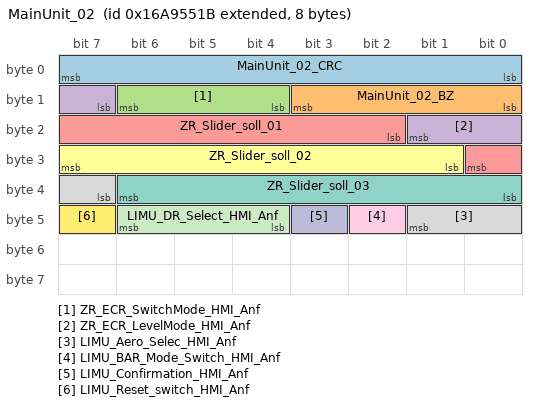
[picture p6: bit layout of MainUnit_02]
BO_ 2527679771 MainUnit_02: 8 ZR_LIMU
 SG_ MainUnit_02_CRC : 0|8@1+ (1,0) [0|255] ""  Gateway,Gateway_PAG
 SG_ MainUnit_02_BZ : 8|4@1+ (1,0) [0|15] ""  Gateway,Gateway_PAG
 SG_ ZR_ECR_SwitchMode_HMI_Anf : 12|3@1+ (1.0,0.0) [0.0|7] ""  Gateway,Gateway_PAG
 SG_ ZR_ECR_LevelMode_HMI_Anf : 15|3@1+ (1.0,0.0) [0.0|7] ""  Gateway,Gateway_PAG
 SG_ ZR_Slider_soll_01 : 18|7@1+ (0.01,0) [0.00|1.26] "Unit_None"  Gateway,Gateway_PAG
 SG_ ZR_Slider_soll_02 : 25|7@1+ (0.01,0) [0.00|1.26] "Unit_None"  Gateway,Gateway_PAG
 SG_ ZR_Slider_soll_03 : 32|7@1+ (0.01,0) [0.00|1.26] "Unit_None"  Gateway,Gateway_PAG
 SG_ LIMU_Aero_Selec_HMI_Anf : 39|3@1+ (1.0,0.0) [0.0|7] ""  Gateway,Gateway_PAG
 SG_ LIMU_BAR_Mode_Switch_HMI_Anf : 42|1@1+ (1.0,0.0) [0.0|1] ""  Gateway,Gateway_PAG
 SG_ LIMU_Confirmation_HMI_Anf : 43|1@1+ (1.0,0.0) [0.0|1] ""  Gateway,Gateway_PAG
 SG_ LIMU_DR_Select_HMI_Anf : 44|3@1+ (1.0,0.0) [0.0|7] ""  Gateway,Gateway_PAG
 SG_ LIMU_Reset_switch_HMI_Anf : 47|1@1+ (1.0,0.0) [0.0|1] ""  Gateway,Gateway_PAG

BO_ 1639 Mem_BFS_01: 8 Gateway
 SG_ BFS_Fond_Bed_Ack : 12|1@1+ (1.0,0.0) [0.0|1] ""  ZR_High
 SG_ BFS_Lehne_nicht_verriegelt : 13|1@1+ (1.0,0.0) [0.0|1] ""  Vector__XXX
 SG_ BFS_Klapptisch_offen : 14|1@1+ (1.0,0.0) [0.0|1] ""  ZR_High
 SG_ BFS_Gurtbringer_Sperre : 15|1@1+ (1.0,0.0) [0.0|1] ""  ZR_High
 SG_ BFS_Sitzsym_Fahrt_aktiv : 16|1@1+ (1.0,0.0) [0.0|1] ""  ZR_High
 SG_ BFS_Sitzfahrt_aktiv : 17|1@1+ (1.0,0.0) [0.0|1] ""  ZR_High
 SG_ BFS_SLV_aktiv : 18|1@1+ (1.0,0.0) [0.0|1] ""  ZR_High
 SG_ BFS_SHV_aktiv : 19|1@1+ (1.0,0.0) [0.0|1] ""  ZR_High
 SG_ BFS_LNV_aktiv : 20|1@1+ (1.0,0.0) [0.0|1] ""  ZR_High
 SG_ BFS_SNV_aktiv : 21|1@1+ (1.0,0.0) [0.0|1] ""  ZR_High
 SG_ BFS_KSV_aktiv : 22|1@1+ (1.0,0.0) [0.0|1] ""  ZR_High
 SG_ BFS_LKV_aktiv : 23|1@1+ (1.0,0.0) [0.0|1] ""  ZR_High
 SG_ BFS_STV_aktiv : 24|1@1+ (1.0,0.0) [0.0|1] ""  ZR_High
 SG_ BFS_LHV_aktiv : 25|1@1+ (1.0,0.0) [0.0|1] ""  ZR_High
 SG_ BFS_LWV_aktiv : 26|1@1+ (1.0,0.0) [0.0|1] ""  ZR_High
 SG_ BFS_GHV_aktiv : 27|1@1+ (1.0,0.0) [0.0|1] ""  ZR_High
 SG_ BFS_KSS_Fahrt_aktiv : 28|1@1+ (1.0,0.0) [0.0|1] ""  ZR_High
 SG_ BFS_MMB_lokal_Stop : 29|1@1+ (1.0,0.0) [0.0|1] ""  ZR_High
 SG_ BFS_Ruhestellung_Status : 30|1@1+ (1.0,0.0) [0.0|1] ""  ZR_High
 SG_ BFS_Seat_Locked : 31|1@1+ (1.0,0.0) [0.0|1] ""  ZR_High
 SG_ BFS_MMB_storage : 32|4@1+ (1.0,0.0) [0.0|15] ""  ZR_High
 SG_ BFS_MMB_tipp : 36|1@1+ (1.0,0.0) [0.0|1] ""  ZR_High
 SG_ BFS_MMB_tast : 37|1@1+ (1.0,0.0) [0.0|1] ""  ZR_High
 SG_ BFS_MMB_store_LED_on : 38|1@1+ (1.0,0.0) [0.0|1] ""  ZR_High
 SG_ BFS_MMB_storage_beep : 39|1@1+ (1.0,0.0) [0.0|1] ""  ZR_High
 SG_ BFS_MMB_store : 40|1@1+ (1.0,0.0) [0.0|1] ""  ZR_High
 SG_ BFS_MMB_glob_stop : 41|1@1+ (1.0,0.0) [0.0|1] ""  ZR_High
 SG_ BFS_FSV_ausgeklappt : 42|1@1+ (1.0,0.0) [0.0|1] ""  ZR_High
 SG_ BFS_NFA_einfahren : 43|1@1+ (1.0,0.0) [0.0|1] ""  Vector__XXX
 SG_ BFS_Kollisionsbereich_Windschott : 44|1@1+ (1.0,0.0) [0.0|1] ""  Vector__XXX
 SG_ BFS_Kollisionsgefahr_Windschott : 45|1@1+ (1.0,0.0) [0.0|1] ""  Vector__XXX

BO_TX_BU_ 1719 :Gateway,Gateway_PAG;
BO_TX_BU_ 1720 :Gateway,Gateway_PAG;
BO_TX_BU_ 1724 :Gateway,Gateway_PAG;
BO_TX_BU_ 2527679638 :Gateway,Gateway_PAG;
BO_TX_BU_ 2527679639 :Gateway,Gateway_PAG;
BO_TX_BU_ 2527679656 :Gateway,Gateway_PAG;
BO_TX_BU_ 2549875055 :Gateway,Gateway_PAG;
BO_TX_BU_ 2550006127 :ZR_High,ZR_MIB_TOP_ab_Gen3,ZR_Standard;
BO_TX_BU_ 2549875059 :Gateway,Gateway_PAG;
BO_TX_BU_ 2550006131 :ZR_High,ZR_MIB_TOP_ab_Gen3,ZR_Standard;
BO_TX_BU_ 2549875056 :Gateway,Gateway_PAG;
BO_TX_BU_ 2550006128 :ZR_High,ZR_MIB_TOP_ab_Gen3,ZR_Standard;
BO_TX_BU_ 2549875053 :Gateway,Gateway_PAG;
BO_TX_BU_ 2550006125 :ZR_High,ZR_MIB_TOP_ab_Gen3,ZR_Standard;
BO_TX_BU_ 2527679653 :Gateway,Gateway_PAG;
BO_TX_BU_ 2589283974 :Gateway,Gateway_PAG;
BO_TX_BU_ 981 :Gateway,Gateway_PAG;
BO_TX_BU_ 982 :Gateway,Gateway_PAG;
BO_TX_BU_ 1624 :Gateway,Gateway_PAG;
BO_TX_BU_ 1321 :Gateway,Gateway_PAG;
BO_TX_BU_ 822 :Gateway,Gateway_PAG;
BO_TX_BU_ 134 :Gateway,Gateway_PAG;
BO_TX_BU_ 917 :Gateway,Gateway_PAG;
BO_TX_BU_ 1153 :ZR_High,ZR_LIMU,ZR_MIB_TOP_ab_Gen3,ZR_Standard;
BO_TX_BU_ 1639 :Gateway,Gateway_PAG;
CM_ BO_ 982 "MQB";
CM_ BO_ 134 "ab MQB mit CRC in Byte 1";
CM_ BO_ 917 "MLB";
CM_ BO_ 1639 "MLBevo";

CM_ SG_ 1719 KBI_aktive_Laengsfunktion "Auswahl, der vom Fahrer gewünschten Laengsregelfunktion";
CM_ SG_ 1719 KBI_FoD_PopUP_Quittiert "Angezeigte FoD-Warnung im Kombi wurde vom Fahrer quittiert; 
Signal wird für die Dauer von 2 Sekunden gesendet";
CM_ SG_ 1719 KBI_FStatus_Tank "Signal wird gesetzt:

a) Während der Fehlerentprellzeit (20 s Entprellung)

b) Bei erkanntem Fehler wird der Tankinhalt während der laufenden KL15-Phase über den 
    Verbrauch zurückgerechnet. In dieser Zeit ist das Bit ebenfalls gesetzt. Nach einem";
CM_ SG_ 1719 KBI_GRA_im_ACC "Gibt den vom Fahrer ausgewählten Modus (ACC oder GRA_im_ACC) an.";
CM_ SG_ 1719 KBI_Inhalt_Tank "Restmenge 2 bzw. 2,5l nicht auflösbar

";
CM_ SG_ 1719 KBI_Kilometerstand "Fehler wird ausgegeben, falls Kilometerstand nicht restaurierbar
";
CM_ SG_ 1719 KBI_LVDS_Lock "Dient zur Synchronisation der Anzeige zwischen Kombi und ZR";
CM_ SG_ 1719 KBI_Oelwechsel_durchgefuehrt "Nach einen Ölwechsel (Service) ist die Ethanol Warmfahrwarnung zu unterdrücken.";
CM_ SG_ 1719 KBI_QBit_Aussen_Temp_gef "0x0 = gültiger Wert
0x1 = Ersatz-, Init- oder Fehlerwert";
CM_ SG_ 1719 KBI_RDK_Kalibrier_Anf "Bei gesetztem Bit soll die RDK die aktuellen Istdrücke zu Solldrücken übernehmen (nur bei Nichtverbau einer Headunit erforderlich).";
CM_ SG_ 1719 KBI_Reserve_Warnung_Sek "Signalisiert die Reservewarnung für die Energiespeicher CNG, LPG, HV-Batterie.
Fahrer wird gewarnt, dass er den Reservebereich erreicht hat. Fzg.spezifische Warnschwelle.";
CM_ SG_ 1719 KBI_Standzeit_02 "Zähler welcher die Standzeit des Motors wiedergibt.
Das Signal beschreibt den Anteil der Motor-Standzeit zwischen Zündung aus und nächstem Motorstart.";

CM_ SG_ 1720 KBI_BCmE_aktiv "Anzeige BCmE aktiv (BCmE-Screen oder Einsparhinweis in der Anzeige)";
CM_ SG_ 1720 KBI_GAP_Warn_Zeit_abgelaufen "Die Zeit, z.B. 1460 Tage, bis zur finalen Warnstufe der Gasanlagenprüfung wurde berechnet. Berechnung erfolgt auf Basis der aktuellen Uhrzeit mit einem Tageszähler. Keine Berechnung des Zählers bei Kl.30 AUS.";
CM_ SG_ 1720 KBI_Max_Tankinhalt "Mitteilung des maximalen Tankinhalts an das Reichweitenmodul";
CM_ SG_ 1720 KBI_Nachtanken_erkannt "Statusinformation Nachtankmodus";
CM_ SG_ 1720 KBI_Quittierung_cAQP "Quittierungsbestätigung vom Fahrer für Funktion cAQP";
CM_ SG_ 1720 KBI_Quittierung_Naesse "Quittierungsbestätigung vom Fahrer";
CM_ SG_ 1720 KBI_Reifenumfang "Mittlerer Radumfang aus der K-Zahl gerechnet in Millimeter.  Byte 2 Bit 5,4 reserviert, Byte 2 Bit 3..0 und Byte 1 Bit 7..0; Wertebereich 0..4096 mm
";
CM_ SG_ 1720 KBI_Reifenumfang_Sekundaer "Fahrzeuge mit unterschiedlichen Reifenumfängen Vorderachse / Hinterachse:

Primärachse: KBI_Reifenumfang
Sekundärachse: KBI_Reifenumfang_Sekundaer
";
CM_ SG_ 1720 KBI_Sparhinweis_quittiert "angezeigter Sparhinweis ist quittiert. Signal wird nach zwei Sendebotschaften wieder auf '0' gesetzt.";
CM_ SG_ 1720 KBI_Tankfuellstand_Prozent "Tankfüllstand in %";
CM_ SG_ 1720 KBI_Tankinhalt_hochaufl "angezeigter Tankinhalt hochauflösend zur Restreichweitenberechnung";
CM_ SG_ 1720 KBI_Variante "Zeigt an ob es sich um ein konventionelles Zeiger-Kombiinstrument handelt oder um eine Volldisplay-Kombiinstrument";
CM_ SG_ 1720 KBI_Variante_USA "In diesem Signal wird die HW-Variante des Kombis ausgegeben, ACC plausibilisiert auf dieses Signal hin seine US-Codierung";

CM_ SG_ 1724 KBI_Insp_dis "Distanz bis zur Inspektion:

Einheitenloser Wert. Einheit im Signal 'KBI_Inspection_distance_unit'";
CM_ SG_ 1724 KBI_Insp_dis_status "Einheit Distanz bis zur Inspektion:";
CM_ SG_ 1724 KBI_Insp_dis_unit "Einheit Distanz bis zur Inspektion:";
CM_ SG_ 1724 KBI_Insp_time "Zeit bis zur Inspektion:

Angabe in Tagen";
CM_ SG_ 1724 KBI_Insp_time_status "Inspektionsstatus Zeit:";
CM_ SG_ 1724 KBI_Oil_dis "Distanz bis zum Ölwechsel:

Einheitenloser Wert. Einheit im Signal 'KBI_Oil_distance_unit'";
CM_ SG_ 1724 KBI_Oil_dis_status "Ölwechselstatus Distanz:";
CM_ SG_ 1724 KBI_Oil_dis_unit "Einheit Distanz bis zum Ölwechsel:";
CM_ SG_ 1724 KBI_Oil_time "Zeit bis zum Ölwechsel:

Angabe in Tagen";
CM_ SG_ 1724 KBI_Oil_time_status "Ölwechselstatus Zeit:";
CM_ SG_ 1724 KBI_Warnung_ID "ID, die einer Warnung im Kombi entspricht und entsprechend der Anzeige im Kombi gesetzt wird.";

CM_ SG_ 2527679638 KBI_GZeit_HSek "Stoppuhr-Gesamtzeit laufend - 1/100 Sekunden


PAG-Plattform:
Sendeart: Cyclic
Zykluszeit: 20ms

MLBevo_Konzern:
Sendeart: OnChange
Zykluszeit: 1000ms
Inhibitzeit: 100ms";
CM_ SG_ 2527679638 KBI_GZeit_Min "Stoppuhr-Gesamtzeit laufend Minuten

PAG-Plattform:
Sendeart: Cyclic
Zykluszeit: 20ms

MLBevo_Konzern:
Sendeart: OnChange
Zykluszeit: 1000ms
Inhibitzeit: 100ms";
CM_ SG_ 2527679638 KBI_GZeit_Sek "Stoppuhr-Gesamtzeit laufend - Sekunden

PAG-Plattform:
Sendeart: Cyclic
Zykluszeit: 20ms

MLBevo_Konzern:
Sendeart: OnChange
Zykluszeit: 1000ms
Inhibitzeit: 100ms";
CM_ SG_ 2527679638 KBI_GZeit_Std "Stoppuhr-Gesamtzeit laufend - Stunden

PAG-Plattform:
Sendeart: Cyclic
Zykluszeit: 20ms

MLBevo_Konzern:
Sendeart: OnChange
Zykluszeit: 1000ms
Inhibitzeit: 100ms
";
CM_ SG_ 2527679638 KBI_RZ_Nr "Nr. der aktuellen Runde

PAG-Plattform:
Sendeart: Cyclic
Zykluszeit: 250ms

MLBevo_Konzern:
Sendeart: OnChange
Zykluszeit: 1000ms
Inhibitzeit: 100ms";
CM_ SG_ 2527679638 KBI_RZeit_HSek "Stoppuhr -Rundenzeit - 1/100 Sekunden

PAG-Plattform:
Sendeart: Cyclic
Zykluszeit: 250ms

MLBevo_Konzern:
Sendeart: OnChange
Zykluszeit: 1000ms
Inhibitzeit: 100ms
";
CM_ SG_ 2527679638 KBI_RZeit_Min "Stoppuhr - Rundenzeit - Minuten

PAG-Plattform:
Sendeart: Cyclic
Zykluszeit: 250ms

MLBevo_Konzern:
Sendeart: OnChange
Zykluszeit: 1000ms
Inhibitzeit: 100ms
";
CM_ SG_ 2527679638 KBI_RZeit_Sek "Stoppuhr - Rundenzeit - Sekunden

PAG-Plattform:
Sendeart: Cyclic
Zykluszeit: 250ms

MLBevo_Konzern:
Sendeart: OnChange
Zykluszeit: 1000ms
Inhibitzeit: 100ms";
CM_ SG_ 2527679638 KBI_RZeit_Std "Stoppuhr - Rundenzeit - Stunden

PAG-Plattform:
Sendeart: Cyclic
Zykluszeit: 250ms

MLBevo_Konzern:
Sendeart: OnChange
Zykluszeit: 1000ms
Inhibitzeit: 100ms
";
CM_ SG_ 2527679638 KBI_Status_StoppUhr "Status Stoppuhr";

CM_ SG_ 2527679639 KBI_Jokerkey "Betaetigung KBI Jokertaste";
CM_ SG_ 2527679639 KBI_RS_Druck_uebernehmen "Druck für Rundstreckenmodus übernehmen";
CM_ SG_ 2527679639 KBI_RS_Druckauswahl_Aktiv "Menue Druckauswahl aktiv";
CM_ SG_ 2527679639 KBI_RS_Mode_fortsetzen "Kombi fordert Fortsetzung des Rundstreckenmodus";
CM_ SG_ 2527679639 KBI_Rundstreckenmodus "Rundstreckenmodus Anforderung";
CM_ SG_ 2527679639 KBI_Weg_Zaehler "Inkrementaler Zähler des Kombis

PAG-Plattform:
Sendeart: Cyclic
Zykluszeit: 100ms

MLBevo_Konzern:
Sendeart: OnChange
Zykluszeit: 1000ms
Inhibitzeit: 100ms
";
CM_ SG_ 2527679639 KBI_Weg_Zaehler_F "Fehlerbit für den Inkrementalzähler Weg

PAG-Plattform:
Sendeart: Cyclic
Zykluszeit: 100ms

MLBevo_Konzern:
Sendeart: OnChange
Zykluszeit: 1000ms
Inhibitzeit: 100ms";

CM_ SG_ 2527679656 KBI_StartupAnimation "Synchronisierung der StartupAnimation zwischen Kombi und MMI.";

CM_ SG_ 2549875055 KS_AMP_Req_Data "Komponentenschutz (Funktion 01h). Request mit NA des Slaves.";

CM_ SG_ 2550006127 KS_AMP_Resp_Data "Komponentenschutz (Funktion 01h). Response mit eigener NA.";

CM_ SG_ 2549875059 KS_Info_El_Req_Data "Komponentenschutz (Funktion 01h). Request mit NA des Slaves.";

CM_ SG_ 2550006131 KS_Info_El_Resp_Data "Komponentenschutz (Funktion 01h). Response mit eigener NA.";

CM_ SG_ 2549875056 KS_Laufwerke_Req_Data "Komponentenschutz (Funktion 01h). Request mit NA des Slaves.";

CM_ SG_ 2550006128 KS_Laufwerke_Resp_Data "Komponentenschutz (Funktion 01h). Response mit eigener NA.";

CM_ SG_ 2549875053 KS_TV_Tuner_Req_Data "Komponentenschutz (Funktion 01h). Request mit NA des Slaves.";

CM_ SG_ 2550006125 KS_TV_Tuner_Resp_Data "Komponentenschutz (Funktion 01h). Response mit eigener NA.";

CM_ SG_ 701 LAE_Beta_confidence "Confidence factor for Beta";
CM_ SG_ 701 LAE_Beta_VZ "Sign of Beta angle";
CM_ SG_ 701 LAE_BetaSlipAngle "Estimated vehicle side slip angle
by LAE controller";
CM_ SG_ 701 LAE_BetaSlipAngle_02 "Estimated side slip angle by LAE controller";
CM_ SG_ 701 LAE_mu "Estimated grip coefficient
unsigned value";
CM_ SG_ 701 LAE_mu_confidence "Confidence factor for estimated grip
unsigned Value";
CM_ SG_ 701 LAE_Vx "Estimated longitudinal vehicle speed (m/s)";
CM_ SG_ 701 LAE_Vx_confidence "Confidence factor for longitudinal vehicle speed";
CM_ SG_ 701 LAE_Vx_VZ "Sign of longitudinal vehicle speed";
CM_ SG_ 701 LAE_Vy "Estimated lateral vehicle speed (m/s)";
CM_ SG_ 701 LAE_Vy_confidence "Confidence factor for lateral vehicle speed";

CM_ SG_ 2527679653 MXB_LAPP_Freigabe "Freigabe des Advertising durch die DDA";
CM_ SG_ 2527679653 MXB_LAPP_Status_FL "Gibt den Aktivierungsstatus des Fernlichts (FL) durch die Licht-App an.";
CM_ SG_ 2527679653 MXB_LAPP_Statuscode "Gibt den Bereitschaftsstatus der Licht-App an.

Der Wert des Signals ergibt sich aus den Stati der fahrzeugspezifischen Vorbedingungen und dient der Licht-App als Grundlage für Anweisungen an den Kunden.";
CM_ SG_ 2527679653 MXB_LAPP_ZR_Sondermodus_Anf "Anforderung des ZR Sondermodus (BT-Abschaltung)";

CM_ SG_ 2463978818 BTM_BrakeSystem_Status "Brake_system_status for Brake temperature estimation function:
includes status of brake disc and fluid overheating and aged fluid status";
CM_ SG_ 2463978818 BTM_BrakeSystem_Text "Brake temperature management text message to be visualized on kombi";
CM_ SG_ 2463978818 BTM_BrakeSystem_Warnlampe "Activation of warning lamp for brake temperature management";
CM_ SG_ 2463978818 LCV_01_BZ "4bit Botschaftszähler, wird mit jeder Sendebotschaft inkrementiert";
CM_ SG_ 2463978818 LCV_01_CRC "Für MLB:
Berechnung siehe Lastenheft 'Kommunikationsabsicherung für FlexRay und CAN'
Ab MQB und MLBevo:
Berechnung siehe Lastenheft 'End-to-End Kommunikationsabsicherung'

Endwerte siehe Begleitdokument 'S-PDU Kennungsfolgen'";
CM_ SG_ 2463978818 LCV_Aero_EngineBay_Cooling "Status of Engine Bay Cooling strategy";
CM_ SG_ 2463978818 LCV_Aero_Front_System_Status "Status of the front active aerodinamic system";
CM_ SG_ 2463978818 LCV_Aero_Perf_Limit "Status of Performance Limiter strategy";
CM_ SG_ 2463978818 LCV_Aero_Perf_Limit_Speed "Speed value for Performance Limiter strategy";
CM_ SG_ 2463978818 LCV_Aero_Rear_System_Status "Status of the rear active aerodinamic system";
CM_ SG_ 2463978818 LCV_BrakeGongTemp "Brake temperature management gong activation";
CM_ SG_ 2463978818 LCV_DR_Systemstatus "Status of Damper Control system";
CM_ SG_ 2463978818 LCV_DR_Text "Pop-Up Text on Kombi for Damper Control";
CM_ SG_ 2463978818 LCV_DR_Warnlampe "Operative and warning lamps on the Kombi for Damper Control";
CM_ SG_ 2463978818 LCV_ESP_Zuschaltung "Zwangsweise Aktivierung ESP-Funktionalität durch die Dämpferregelung, Anforderung erfolgt auch bei Passivtastung.";
CM_ SG_ 2463978818 LCV_HD_offen "Status Heckdeckel";
CM_ SG_ 2463978818 LCV_Lift_Status "Status of Lifting System";
CM_ SG_ 2463978818 LCV_Lift_Text "Pop-Up Text on Kombi for Lifting System";
CM_ SG_ 2463978818 LCV_Lift_Warnlampe_Status "Operative and warning lamps on the Kombi for Lifting System";

CM_ SG_ 2527679780 LCV_Aero_BarMode_Activation "Status of the Aero Bar Mode";
CM_ SG_ 2527679780 LCV_Aero_Button_Default "Default value for aero tuning switch";
CM_ SG_ 2527679780 LCV_Aero_Button_Range "Number of available choices of the Aero switch that shall be active";
CM_ SG_ 2527679780 LCV_Aero_Button_Select "Feedback from LCV to LIMU for button selection of Aero";
CM_ SG_ 2527679780 LCV_Aero_Button_Tunable "Aero Tuning switch active or not";
CM_ SG_ 2527679780 LCV_BarMode_Allowed "Bar Mode button availability";
CM_ SG_ 2527679780 LCV_DR_Button_Default "Default value for damper tuning switch";
CM_ SG_ 2527679780 LCV_DR_Button_Range "Number of available choices of the DC switch that shall be active";
CM_ SG_ 2527679780 LCV_DR_Button_Select "Feedback from LCV to LIMU for button selection of Damper Control";
CM_ SG_ 2527679780 LCV_DR_Button_Tunable "DC Tuning switch active or not";

CM_ SG_ 2463978684 BTM_BrakeDiscTemp_01 "Brake disc temperature 01 estimation.";
CM_ SG_ 2463978684 BTM_BrakeDiscTemp_02 "Brake disc temperature 02 estimation.";
CM_ SG_ 2463978684 BTM_BrakeDiscTemp_03 "Brake disc temperature 03 estimation.";
CM_ SG_ 2463978684 BTM_BrakeDiscTemp_04 "Brake disc temperature 04 estimation.";
CM_ SG_ 2463978684 BTM_BrakeFluidTemp_01 "Brake fluid temperature 01 estimation.";
CM_ SG_ 2463978684 BTM_BrakeFluidTemp_02 "Brake fluid temperature 02 estimation.";
CM_ SG_ 2463978684 BTM_BrakeFluidTemp_03 "Brake fluid temperature 03 estimation.";
CM_ SG_ 2463978684 BTM_BrakeFluidTemp_04 "Brake fluid temperature 04 estimation.";

CM_ SG_ 548 LCV_Aero_Front_Ratio "Front ratio of the aerodynamic load distribution ( value indicates the percentage of front left/right)";
CM_ SG_ 548 LCV_Aero_Long_Ratio "Longitudinal ratio of the aerodynamic load distribution ( value indicates the percentage of rear )";

CM_ SG_ 2589283974 BTM_BrakeDiscColour_01 "Brake disc visualization colour";
CM_ SG_ 2589283974 BTM_BrakeDiscColour_02 "Brake disc visualization colour";
CM_ SG_ 2589283974 BTM_BrakeDiscColour_03 "Brake disc visualization colour";
CM_ SG_ 2589283974 BTM_BrakeDiscColour_04 "Brake disc visualization colour";
CM_ SG_ 2589283974 BTM_BrakeFluidColour_01 "Brake fluid visualization colour";
CM_ SG_ 2589283974 BTM_BrakeFluidColour_02 "Brake fluid visualization colour";
CM_ SG_ 2589283974 BTM_BrakeFluidColour_03 "Brake fluid visualization colour";
CM_ SG_ 2589283974 BTM_BrakeFluidColour_04 "Brake fluid visualization colour";

CM_ SG_ 981 BCM1_Abblendlicht_Anf "Anforderung Abblendlicht
";
CM_ SG_ 981 BCM1_Adaptive_Lichtvert_Anf "Funktion 'Adaptive Lichtverteilung' im AFS-SG  Ein- und Ausschalten";
CM_ SG_ 981 BCM1_Allwetterlicht_Anf "Anforderung eines Allwetterlichts (über AFS-SG realisiert): Licht für schlechte Sichtverhältnisse";
CM_ SG_ 981 BCM1_Animationssperrung "Sperrung der Scheinwerfer- und Heckleuchten-Animationen. Grund für Sperrung sind allgemeine Rahmenbedingungen, wie beispielseweise eine LDS-Stellung ungleich 'Auto'";
CM_ SG_ 981 BCM1_Autobahnlicht_Anf "Anforderung Autobahnlicht
";
CM_ SG_ 981 BCM1_CH_aktiv "Coming Home (zusätzlich zum Signal 'BCM1_CH_LH_aktiv' in der Botschaft BCM1_01)";
CM_ SG_ 981 BCM1_CH_LH_aktiv "Status Comming / Leaving Home
";
CM_ SG_ 981 BCM1_Fernlicht_Anf "Anforderung Fernlicht
";
CM_ SG_ 981 BCM1_FOD_Sperrung_Animationen_HL "Sperrung Heckleuchten-Animationen durch FoD.";
CM_ SG_ 981 BCM1_FoD_Sperrung_WiBli "Sperrung Wischeffekt des dynamischen Blinkers (Front & Heck) durch FoD";
CM_ SG_ 981 BCM1_Gleitende_Leuchtw_Anf "Funktion 'Gleitende Leuchtweite' im AFS-SG  freischalten";
CM_ SG_ 981 BCM1_GLW_Fernlicht_Anf "Harte Fernlichtanforderung von BCM1 an die Funktion 'gleitende Leuchtweite' im AFS-SG";
CM_ SG_ 981 BCM1_Kurvenlicht_links_Anf "Ansteuerung linkes Kurvenlicht/Abbiegelicht duch BCM1";
CM_ SG_ 981 BCM1_Kurvenlicht_rechts_Anf "Ansteuerung rechtes Kurvenlicht/Abbiegelicht duch BCM1";
CM_ SG_ 981 BCM1_LH_aktiv "Leaving Home (zusätzlich zum Signal 'BCM1_CH_LH_aktiv' in der Botschaft BCM1_01)";
CM_ SG_ 981 BCM1_Nebellicht_Anf "Anforderung Nebellicht
";
CM_ SG_ 981 BCM1_Nebelschluss_Ahg_Anf "Anforderung: Nebelschlusslicht Anhänger (Sollzustand)
";
CM_ SG_ 981 BCM1_Nebelschluss_Fzg_Anf "Anforderung: Nebelschlusslicht Fahrzeug (Sollzustand)
";
CM_ SG_ 981 BCM1_Parklicht_li_Anf "Anforderung: Parklicht links (Sollzustand)
";
CM_ SG_ 981 BCM1_Parklicht_re_Anf "Anforderung: Parklicht rechts (Sollzustand)
";
CM_ SG_ 981 BCM1_Regenlicht_Anf "Anforderung: Regenlicht (Sollzustand)
";
CM_ SG_ 981 BCM1_Schlusslicht_Anf "Anforderung: Schlusslicht Fahrzeug (Sollzustand)
";
CM_ SG_ 981 BCM1_Schlusslicht_Signatur "Anforderung der Umschaltung der Schlusslicht-Signatur";
CM_ SG_ 981 BCM1_Signaturlicht_Anf "Signal zur Anforderung des Signaturlichts";
CM_ SG_ 981 BCM1_Standlicht_Anf "Anforderung: Schlusslicht (Sollzustand)";
CM_ SG_ 981 BCM1_Tagfahrlicht_Anf "Anforderung: Tagfahrlicht (Sollzustand)";
CM_ SG_ 981 BCM1_Touristen_Licht_Anf "Anforderung: Touristenlicht (Sollzustand)";
CM_ SG_ 981 BCM1_Umfeldleuchten_Anf "Anforderung für Umfeldleuchten";
CM_ SG_ 981 BCM_Rueckfahrlicht_Anf "Anforderung Rückfahrlicht (Sollzustand). 
Das Signal wird entprellt (typisch 400ms) und bei KL15EIN gesendet. Das Signal ist unabhängig von der Position des Heckdeckels (kein Überhitzungsschutz).";
CM_ SG_ 981 Licht_Anf_01_BZ "4bit Botschaftszaehler, wird mit jeder Sendebotschaft inkrementiert";
CM_ SG_ 981 Licht_Anf_01_CRC "Für MLB:
'Berechnung siehe Lastenheft 'Kommunikationsabsicherung für FlexRay und CAN''

Ab MQB und MLBevo:
'Berechnung siehe Lastenheft 'End-to-End Kommunikationsabsicherung''

Endwerte siehe Begleitdokument 'S-PDU Kennungsfolgen'";

CM_ SG_ 982 BCM2_Bremsl_durch_ECD "Bremslicht (ECD-Bremsung)
";
CM_ SG_ 982 LH_3_Bremsl_def "Fehlerstatus 3. Bremsleuchte
";
CM_ SG_ 982 LH_Aussenlicht_def "Aussenlicht kann nicht mehr korrekt angesteuert werden (EEPROM Codierung kann nicht mehr ausgelesen werden)
";
CM_ SG_ 982 LH_Blinker_HL_akt "Blinker hinten links
";
CM_ SG_ 982 LH_Blinker_HR_akt "Blinker hinten rechts
";
CM_ SG_ 982 LH_Blinker_li_def "Fehlerstatus Blinker hinten links
";
CM_ SG_ 982 LH_Blinker_re_def "Fehlerstatus Blinker hinten rechts
";
CM_ SG_ 982 LH_Brems_Blk_li_def "Konfiguration BRL + BLK links 
";
CM_ SG_ 982 LH_Brems_Blk_re_def "Konfiguration BRL + BLK rechts
";
CM_ SG_ 982 LH_Bremsl_li_def "Fehlerstatus Bremslicht hinten links (Detektion Einzelausfall)
";
CM_ SG_ 982 LH_Bremsl_li_ges_def "Fehlerstatus Bremslicht hinten links (Detektion Totalausfall)
";
CM_ SG_ 982 LH_Bremsl_mi_def "Fehlerstatus Bremslicht mitte oder Gepäckraumklappe  (Detektion Einzelausfall)";
CM_ SG_ 982 LH_Bremsl_re_def "Fehlerstatus Bremslicht hinten rechts  (Detektion Einzelausfall)
";
CM_ SG_ 982 LH_Bremsl_re_ges_def "Fehlerstatus Bremslicht hinten rechts (Detektion Totalausfall)";
CM_ SG_ 982 LH_Bremslicht_H_aktiv "Bremslicht hinten
";
CM_ SG_ 982 LH_Diag_LED_li_def "Heckleuchte links defekt";
CM_ SG_ 982 LH_Diag_LED_re_def "Heckleuchte rechts defekt";
CM_ SG_ 982 LH_Diag_Status_li_def "Außenlicht Diagnose 
Systemstörung links";
CM_ SG_ 982 LH_Diag_Status_re_def "Außenlicht Diagnose Systemstörung rechts ";
CM_ SG_ 982 LH_Kennzl_def "Fehlerstatus Kennzeichenbeleuchtung hinten
";
CM_ SG_ 982 LH_Nebel_li_def "Fehlererkennung Nebelschlusslicht hinten links
";
CM_ SG_ 982 LH_Nebel_mi_def "Fehlererkennung Nebelschlusslicht hinten Mitte


";
CM_ SG_ 982 LH_Nebel_re_def "Fehlererkennung Nebelschlusslicht hinten rechts
";
CM_ SG_ 982 LH_Nebelschluss_aktiv "Nebelschlusslicht
";
CM_ SG_ 982 LH_Parklicht_HL_aktiv "Parklicht hinten links 
";
CM_ SG_ 982 LH_Parklicht_HR_aktiv "Parklicht hinten rechts 
";
CM_ SG_ 982 LH_Rueckf_li_def "Fehlererkennung Rückfahrlicht hinten links
";
CM_ SG_ 982 LH_Rueckf_mi_def "Fehlererkennung Rückfahrlicht Mitte
";
CM_ SG_ 982 LH_Rueckf_re_def "Fehlererkennung Rückfahrlicht hinten rechts
";
CM_ SG_ 982 LH_Rueckfahrlicht_aktiv "Rueckfahrlicht
";
CM_ SG_ 982 LH_Schluss_Brems_li_def "Konfiguration SL+ BRL + PL links und SL+ BRL  links
";
CM_ SG_ 982 LH_Schluss_Brems_mi_def "Fehlerstatus Schluss + Bremslicht mitte defekt (Detektion Einzelausfall)";
CM_ SG_ 982 LH_Schluss_Brems_Nebel_li_def "Signal wird gesetzt, wenn eine Unterbrechung oder  ein Kurzschluss am Lampenausgang für Schluss_Brems_Nebelschlusslicht erkannt wird.";
CM_ SG_ 982 LH_Schluss_Brems_Nebel_re_def "Signal wird gesetzt, wenn eine Unterbrechung oder  ein Kurzschluss am Lampenausgang für Schluss_Brems_Nebelschlusslicht erkannt wird.";
CM_ SG_ 982 LH_Schluss_Brems_re_def "Konfiguration SL+ BRL + PL rechts und SL+ BRL  rechts
";
CM_ SG_ 982 LH_Schluss_Nebel_li_def "Konfiguration SL + NSL links oder SL + NSL + PL links
";
CM_ SG_ 982 LH_Schluss_Nebel_re_def "Konfiguration SL + NSL rechts oder SL + NSL + PL rechts
";
CM_ SG_ 982 LH_Schlusslicht_li_def "Fehlererkennung Schlusslicht hinten links
";
CM_ SG_ 982 LH_Schlusslicht_mi_def "Fehlererkennung Schlusslicht hinten Mitte";
CM_ SG_ 982 LH_Schlusslicht_re_def "Fehlererkennung Schlusslicht hinten rechts
";
CM_ SG_ 982 LH_SL_BRL_BLK_li_def "Konfiguration SL + BRL + BLK links oder SL + BRL + BLK + PL links
";
CM_ SG_ 982 LH_SL_BRL_BLK_re_def "Konfiguration SL + BRL + BLK rechts oder SL + BRL + BLK + PL rechts
";
CM_ SG_ 982 LH_Standlicht_H_aktiv "Standlicht hinten
";
CM_ SG_ 982 LH_Zusatzschlussl_def "mindestens ein Zusatzschlusslicht in der Heckbeleuchtung defekt.";

CM_ SG_ 1624 BCM1_Licht_Dunkelheit_aktiv "Licht aktiv aufgrund von Dunkelheit (nicht bei Autobahn-, Tagfahr- oder Regenlicht)";
CM_ SG_ 1624 BCM1_Linksverkehr "Information über Aufbauzustand des Fzg:
0 = Scheinwerfer für Rechtsverkehr
1 = Scheinwerfer für Linksverkehr";
CM_ SG_ 1624 Licht_Vorne_01_CRC "Für MLB:
'Berechnung siehe Lastenheft 'Kommunikationsabsicherung für FlexRay und CAN''

Ab MQB und MLBevo:
'Berechnung siehe Lastenheft 'End-to-End Kommunikationsabsicherung''

Endwerte siehe Begleitdokument 'S-PDU Kennungsfolgen'";
CM_ SG_ 1624 LV_Abbiegelicht_li_def "Fehlerstatus Abbiegelicht vorne links
";
CM_ SG_ 1624 LV_Abbiegelicht_re_def "Fehlerstatus Abbiegelicht vorne rechts
";
CM_ SG_ 1624 LV_Abblend_Fernlicht_li_def "Fehlerstatus Abblendlicht und Fernlicht links ";
CM_ SG_ 1624 LV_Abblend_Fernlicht_re_def "Fehlerstatus Abblendlicht und Fernlicht rechts";
CM_ SG_ 1624 LV_Abblendlicht_Anzeige "Abblendlicht aktiv";
CM_ SG_ 1624 LV_Abblendlicht_li_def "Fehlerstatus Abblendlicht vorne links 
";
CM_ SG_ 1624 LV_Abblendlicht_re_def "Fehlerstatus Abblendlicht vorne rechts
";
CM_ SG_ 1624 LV_Abblendlicht_TFL_li_def "Fehlerstatus Abblendlicht und Tagfahrlicht links
";
CM_ SG_ 1624 LV_Abblendlicht_TFL_re_def "Fehlerstatus Abblendlicht und Tagfahrlicht rechts ";
CM_ SG_ 1624 LV_AFL_aktiv_Anzeige "Anzeige AFL-Funktion";
CM_ SG_ 1624 LV_AFL_defekt "Fehlerstatus AFL
";
CM_ SG_ 1624 LV_Aussenlicht_def "Aussenlicht kann nicht mehr korrekt angesteuert werden (EEPROM Codierung kann nicht mehr ausgelesen werden)
";
CM_ SG_ 1624 LV_Blinker_li_def "Fehlerstatus Blinker vorne links
";
CM_ SG_ 1624 LV_Blinker_re_def "Fehlerstatus Blinker vorne rechts
";
CM_ SG_ 1624 LV_Blinker_VL_aktiv "Blinker vorne links
";
CM_ SG_ 1624 LV_Blinker_VR_aktiv "Blinker vorne links
";
CM_ SG_ 1624 LV_Blk_li_Seite_def "Fehlerstatus Seitenblinker links
";
CM_ SG_ 1624 LV_Blk_re_Seite_def "Fehlerstatus Blinker Seite rechts
";
CM_ SG_ 1624 LV_Fernlicht_Anzeige "Fernlicht_aktiv";
CM_ SG_ 1624 LV_Fernlicht_li_def "Fehlerstatus Fernlicht vorne links
";
CM_ SG_ 1624 LV_Fernlicht_re_def "Fehlerstatus Fernlicht vorne rechts
";
CM_ SG_ 1624 LV_FLA_aktiv_Anzeige "Ansteuerung FLA-Lampe im Kombi (BCM1 Bedienmaster)";
CM_ SG_ 1624 LV_FLA_defekt "Fehlerstatus FLA (Anzeige des entsprechenden Fehlertext im Kombi)";
CM_ SG_ 1624 LV_FLA_Sensor_blockiert "Status FLA-Sensor (Anzeige des entsprechenden Fehlertext im Kombi)";
CM_ SG_ 1624 LV_LED_Scheinwerfer_li_def "Fehlerstatus LED-Scheinwerfer links
";
CM_ SG_ 1624 LV_LED_Scheinwerfer_re_def "Fehlerstatus LED-Scheinwerfer rechts";
CM_ SG_ 1624 LV_MXB_Status_Anzeige "Aktueller Status des Fernlichts / MxB zur Signalisierung im Kombi.";
CM_ SG_ 1624 LV_Nebellicht_Anzeige "Nebellicht_aktiv
";
CM_ SG_ 1624 LV_Nebellicht_li_def "Fehlerstatus Nebelscheinwerfer vorne links
";
CM_ SG_ 1624 LV_Nebellicht_re_def "Fehlerstatus Nebelscheinwerfer vorne rechts
";
CM_ SG_ 1624 LV_Nebellicht_TFL_li_def "Fehlerstatus Nebellicht und Tagfahrlicht links ";
CM_ SG_ 1624 LV_Nebellicht_TFL_re_def "Fehlerstatus Nebellicht und Tagfahrlicht rechts";
CM_ SG_ 1624 LV_Nebelschlusslicht_Anzeige "Nebelschlusslicht_aktiv
";
CM_ SG_ 1624 LV_Standlicht_Anzeige "Anzeige Standlicht
";
CM_ SG_ 1624 LV_Standlicht_li_def "Fehlerstatus Standlicht vorne links
";
CM_ SG_ 1624 LV_Standlicht_re_def "Fehlerstatus Standlicht vorne rechts
";
CM_ SG_ 1624 LV_Standlicht_TFL_li_def "Fehlerstatus Standlicht und Tagfahrlicht links ";
CM_ SG_ 1624 LV_Standlicht_TFL_re_def "Fehlerstatus Standlicht und Tagfahrlicht rechts ";
CM_ SG_ 1624 LV_Tagfahrlicht_Anzeige "Anzeige Tagfahrlicht
";
CM_ SG_ 1624 LV_Tagfahrlicht_li_def "Fehlerstatus Tagfahrlicht links
";
CM_ SG_ 1624 LV_Tagfahrlicht_re_def "Fehlerstatus Tagfahrlicht rechts";

CM_ SG_ 1321 Lift_Anforderung_EFP "Lift Funktionsanforderungen";
CM_ SG_ 1321 Lift_Charisma_FahrPr "


";
CM_ SG_ 1321 Lift_Charisma_Status "Systemstatus des Charismateilnehmers

";
CM_ SG_ 1321 Lift_Charisma_Umschaltung "Erkennung Umschaltaufforderung des Charisma-Teilnehmers";
CM_ SG_ 1321 Lift_ESP_Zuschaltung "Zwangsweise Aktivierung der ESP-Funktionalität wird angefordert.";
CM_ SG_ 1321 Lift_LED "Status der Liftanzeige";
CM_ SG_ 1321 Lift_Meldung_01 "Meldung 1 für das Kombi ";
CM_ SG_ 1321 Lift_Meldung_02 "Meldung 2 für das Kombi ";
CM_ SG_ 1321 Lift_Meldung_03 "Meldung 3 für das Kombi ";
CM_ SG_ 1321 Lift_Meldung_04 "Meldung 4 für das Kombi ";
CM_ SG_ 1321 Lift_Meldung_05 "Meldung 5 für das Kombi ";
CM_ SG_ 1321 Lift_Meldung_06 "Meldung 6 für das Kombi ";
CM_ SG_ 1321 Lift_Meldung_07 "Meldung 7 für das Kombi ";
CM_ SG_ 1321 Lift_Meldung_08 "Meldung 8 für das Kombi ";
CM_ SG_ 1321 Lift_Meldung_09 "Meldung 9 für das Kombi ";
CM_ SG_ 1321 Lift_Meldung_10 "Meldung 10 für das Kombi";
CM_ SG_ 1321 Lift_Meldung_11 "Meldung 11 für das Kombi";
CM_ SG_ 1321 Lift_Meldung_12 "Meldung 12 für das Kombi";
CM_ SG_ 1321 Lift_Meldung_13 "Meldung 13 für das Kombi";
CM_ SG_ 1321 Lift_Meldung_14 "Meldung 14 für das Kombi";
CM_ SG_ 1321 Lift_Position "Aktuelle Position der Liftfunktion";
CM_ SG_ 1321 Lift_SpannungsAnf "Anforderung des Lift zur Spannungsanhebung des Bordnetzes.";
CM_ SG_ 1321 Lift_StartStopp_Info "Stopp-Freigabe und Start-Anforderung an den Start-Stopp-Koordinator";

CM_ SG_ 822 LR_HZG_Taster_on_off "Anforderung des Schalters am MFL: Lenkradheizung aus/ein
(Regelung der LR_HZG ist im SMLS)";
CM_ SG_ 822 LR_HZG_Temp_Sensor "Temperaturwert Lenkradheizung";

CM_ SG_ 2527679774 LRM_Auto_Error "Auto mode not available";
CM_ SG_ 2527679774 LRM_General_Error "ECU Internal fault";
CM_ SG_ 2527679774 LRM_Glass_OC_Error "Glass open circuit";
CM_ SG_ 2527679774 LRM_Glass_Rear_OC_Error "Rear glass open circuit";
CM_ SG_ 2527679774 LRM_Glass_Rear_SC_Error "Rear glass short circuit";
CM_ SG_ 2527679774 LRM_Glass_SC_Error "Glass short circuit";
CM_ SG_ 2527679774 LRM_Level "Electro-chromic glass level status";
CM_ SG_ 2527679774 LRM_Level_Rear "Rear electro-chromic glass level status";
CM_ SG_ 2527679774 LRM_Manual_Error "Manual mode not available";
CM_ SG_ 2527679774 LRM_Mode "Electro-chromic glass mode status";

CM_ SG_ 134 LWI_01_BZ "Botschaft asynchron geroutet. Zählerwert kann springen.";
CM_ SG_ 134 LWI_01_CRC "Für MLB:
'Berechnung siehe Lastenheft 'Kommunikationsabsicherung für FlexRay und CAN''

Ab MQB und MLBevo:
'Berechnung siehe Lastenheft 'End-to-End Kommunikationsabsicherung'

Endwerte siehe Begleitdokument 'S-PDU Kennungsfolgen'";
CM_ SG_ 134 LWI_Lenkradw_Geschw "Wertebereich = +/- 2500 Grad/s
Auflösung = 5 Grad/s

Hinweis: Zusätzlich gestellte Winkel bei Dynamiklenkung beachten !";
CM_ SG_ 134 LWI_Lenkradwinkel "Wertebereich = +/- 800 Grad
Auflösung = 0,1 Grad
ACHTUNG: spezifizierte Interne Auflösung des Sensors beträgt aber nur Schrittweite 0,5 Grad!

Hinweis:
MLB: Zusätzlich gestellte Winkel bei Dynamiklenkung beachten !
MQB: Nicht konstante Lenkübersetzu";
CM_ SG_ 134 LWI_MFL_Abschaltung "Signal zur Anforderung der MFL Abschaltung bei Erkennung einer dynamischen Lenkbewegung.";
CM_ SG_ 134 LWI_QBit_Lenkradwinkel "Das QBit wird auch bei nicht abgeglichenem Lenkradwinkelsensor gesetzt";
CM_ SG_ 134 LWI_QBit_Sub_Daten "Es gilt die Signalspezifikation laut LAH";
CM_ SG_ 134 LWI_Sub_Daten "Verschlüsseltes Datenpaket vom Sub-Rechner des LWS, Verwendung nur durch SCU und ESP_ADS
Verwendung gemäß 'Sicherheitsanforderungen an Empfängersteuergeräte'

Im MLB gilt die Signalspezifikation: LAH 8K0953B
Im MLBevo gilt die Signalspezifikation LAH.";
CM_ SG_ 134 LWI_VZ_Lenkradw_Geschw "Vorzeichen Lenkradwinkelgeschwindigkeit gemäss DIN70000; 
Nullstellung = +0";
CM_ SG_ 134 LWI_VZ_Lenkradwinkel "Vorzeichen Lenkradwinkel gemäss DIN70000; 
Nullstellung = +0";

CM_ SG_ 917 AFS_Abbiegelicht_Dimm_Anf "Beschreibt ob das Abbiegelicht gedimmt oder hart einschalten werden soll. Dimmkurve ist Empfänger hinterlegt.";
CM_ SG_ 917 AFS_Abbiegelicht_li_Anf "Anforderung das Abbiegelicht links einzuschalten";
CM_ SG_ 917 AFS_Abbiegelicht_re_Anf "Anforderung das Abbiegelicht rechts einzuschalten";
CM_ SG_ 917 AFS_adaptive_LV_verbaut "Verfügbarkeit der adaptiven Lichtverteilung im AFS-SG.
(Das BCM steuert mit diesem Signal die Einblendung des entsprechenden Menüs)";
CM_ SG_ 917 AFS_Allwetterlicht "Status ¿Allwetterlicht¿ - Licht für schlechte Sichtverhältnisse
(bei Defekt -> nicht aktiv)";
CM_ SG_ 917 AFS_Charisma_FahrPr "MLBevo: Aktuelles Fahrprogramm des Charisma-Teilnehmers (siehe Systemlastenheft Drive Select)
MQB: Istwert der Kennlinie (siehe Systemlastenheft MQB FPA)";
CM_ SG_ 917 AFS_Charisma_Status "Charisma Systemstatus des Charisma-Teilnehmers

Wert 0x3 ist nur für Fahrzeuge ab MQB relevant";
CM_ SG_ 917 AFS_Charisma_Umschaltung "Erkennung  Umschaltaufforderung des Charisma-Teilnehmers";
CM_ SG_ 917 AFS_Ersatzlicht_Links "Bei aktivierter Ersatzlichtfunktion wird das Abblendlicht ausgeschaltet und eine Ersatzlichtquelle eingeschaltet (z.Zt. B7)";
CM_ SG_ 917 AFS_Ersatzlicht_Rechts "Bei aktivierter Ersatzlichtfunktion wird das Abblendlicht ausgeschaltet und eine Ersatzlichtquelle eingeschaltet (z.Zt. B7)";
CM_ SG_ 917 AFS_Fehlertext "Fehlertext wird im Kombi angezeigt (z.Zt nur bei VW)";
CM_ SG_ 917 AFS_Fernlicht_li_defekt "Beschreibt ob das Fernlicht des linken Scheinwerfers defekt ist";
CM_ SG_ 917 AFS_Fernlicht_re_defekt "Beschreibt ob das Fernlicht des rechten Scheinwerfers defekt ist";
CM_ SG_ 917 AFS_Fernlicht_Status "Beschreibt ob das Fernlicht aktiv oder inaktiv ist";
CM_ SG_ 917 AFS_Lampe "Status der Fehlerlampe: aktuell anliegender Fehlerzustand des dynamischen oder statischen Kurvenlichtes";
CM_ SG_ 917 AFS_LED_Blinkmode "Lampe soll im Warnfall mit 1Hz blinken, wenn das Bit gesetzt ist (z.Zt nur bei VW)";
CM_ SG_ 917 AFS_Status_adaptive_LV "Gibt den Status der adaptiven Lichtverteilung an";
CM_ SG_ 917 AFS_Verfuegbarkeit_GLW "Beschreibt die Verfügbarkeit der Gleitenden Leuchtweite / Fernlichtassistenz - Verfügbarkeit bedeutet, dass die Funktion Gleitende Leuchtweite möglich ist";
CM_ SG_ 917 GLW_Sensor_blockiert "Das Signal zeigt an, dass die Kamera zur Zeit keine Sicht hat. 
Verhalten wie Fernlichassisten. 
Weiterleitung des Signals vom BCM an das KOMBI";
CM_ SG_ 917 LWR_AFS_Grundeinstellung "Grundeinstellung des Abblendlichtes am Lichteinstellkasten im Service oder Bandende mit Tester erfolgt! (auch für das dynamische Kurvernlicht)";
CM_ SG_ 917 LWR_AFS_Parametrisierung "Parametrisierung wählt die Fahrzeugvariante und die AFS-Variante aus";
CM_ SG_ 917 LWR_Hoehenwert_HL "Aktueller Höhensensorwert Hinten Links
MSS LB überträgt den Aktueller Höhensensorwert Vorne Rechts.

0x7F = 0 mm";
CM_ SG_ 917 LWR_Hoehenwert_VL "Aktueller Höhensensorwert Vorne Links

0x7F = 0 mm";
CM_ SG_ 917 LWR_Initialisierungslauf "Initialisierungslauf der Schrittmotoren, erfolgt defaultmäßig beim Motorstart";
CM_ SG_ 917 LWR_Lampe "Status der Fehlerlampe: aktuell anliegender Fehlerzustand";
CM_ SG_ 917 LWR_Modus "Schnelle oder langsame Regelart der LWR";
CM_ SG_ 917 LWR_Pos_Schrittmotor "Position des Aktuators in Prozent des maximalen Stellweges; vor dem Initialisierungslauf (Motorstart) wird der Initwert ausgegeben: 
0% : tiefste Stellung (auf Block) des Schrittmotors;
100% : maximaler Verstellweg des Schrittmotors (nicht die Grenze de";
CM_ SG_ 917 LWR_Reisemodus_Texte "Anzeige der eingestellten Verkehrsart bei aktivem Touristenlicht";
CM_ SG_ 917 LWR_Sicherheitsposition_li "Rechter Scheinwerfer in Sicherheitsposition.";
CM_ SG_ 917 LWR_Sicherheitsposition_re "Rechter Scheinwerfer in Sicherheitsposition.";
CM_ SG_ 917 LWR_Touristenmodus_aktiv "Über MMI sendet BCM1 eine Anforderung Touristenmodus an die LWR. Diese sendet als Rückmeldung an BCM1, dass der Touristenmodus aktiv geschaltet wurde";
CM_ SG_ 917 LWR_Touristenmodus_verbaut "Verfügbarkeit der Touristenfunktion im AFS/LWR-SG.
(Das BCM steuert mit diesem Signal die Einblendung des entsprechenden Menüs)";

CM_ SG_ 1153 DSSS_Warning "DSSS - Driving Safety Support System Meldungen";
CM_ SG_ 1153 MIB_Tongenerator_PH_verfuegbar "Verfügbarkeit des Tongenerators im MIB für die Nutzung durch die Parkhilfe";
CM_ SG_ 1153 MMI_Counter_Bedienevent "Signal wird inkrementiert, wenn Bedienevent stattgefunden hat.";
CM_ SG_ 1153 MMI_Gauges_active "Signal sent from Main Unit to Kombi instrument to give the display status of the additional gauges in the rotating display";
CM_ SG_ 1153 MMI_Gurt_Mic_ref "Referenzsignal für das Gurtmikrofon Steuergerät zur Signalisierung ob der Downlink aktiv oder inaktiv ist";
CM_ SG_ 1153 MMI_SDS_aktiv "Signal wird gesetzt, solange die Sprachbedienung aktiv ist.";
CM_ SG_ 1153 MMI_StartStopp_Info "Stopp-Freigabe und Start-Anforderung an den Start-Stopp-Koordinator
Signal gilt nur für MHEV12V im MLBevo, Stoppverbot darf nur bei Ausstattungsvariante mit 3D-Sound verwendet werden.";
CM_ SG_ 1153 MU_SecondDisplay "Dient zur Überwachung der zweiten LVDS Leitung.";
CM_ SG_ 1153 MU_Update_Time "Ermöglicht auslesen der Historiendaten, wann ein Update lief";
CM_ SG_ 1153 Nav_FoD_Status "FoD Status der Navigation";
CM_ SG_ 1153 ZR_Kindersicherung_RSE "Sperren der Rearseat Unit (Komplette Weckfähigkeit)";
CM_ SG_ 1153 ZR_LAPP_Sondermodus_Status "Statusrückmeldung zum ZR Sondermodus (BT Abschaltung)";
CM_ SG_ 1153 ZR_LoGeWa_Event_Kombiwarnung "Event für Kombiwarnung";
CM_ SG_ 1153 ZR_MXB_Manoever_Ansage "Übertragung der aktuellen Manöver-Ansage für MatrixBeam. Dient zur Veränderung des Lichtbilds abhängig von Navigationsmanövern.";
CM_ SG_ 1153 ZR_Parken_Sondermodus "Rückkanal zum pilotierten Parken zur Signalisierung Status Sondermodus";
CM_ SG_ 1153 ZR_RSE_aktivieren "Weckfähigkeit der RSE";
CM_ SG_ 1153 ZR_Rundenbewertung "Bewertung einer aktuellen Runde (langsamer, gleich schnell, schneller)";
CM_ SG_ 1153 ZR_Rundenfortschritt "Verhältnis von gefahrener Strecke in einer aktuellen Runde zur Länge einer Referenzrunde in Prozent";
CM_ SG_ 1153 ZR_Sta_Inszenierung "MIB sendet Status über Inszenierungssound (welcome sound) an BCM1
Zweck: Synchronisierung mit weiteren Teilnehmern der Startupinszenierung";

CM_ SG_ 2527679771 LIMU_Aero_Selec_HMI_Anf "Virtual buttons for different tuning of the Aerodynamics modes.";
CM_ SG_ 2527679771 LIMU_BAR_Mode_Switch_HMI_Anf "Manual opening of rear spoiler";
CM_ SG_ 2527679771 LIMU_Confirmation_HMI_Anf "Confirmation virtual button for Slider setting confirm";
CM_ SG_ 2527679771 LIMU_DR_Select_HMI_Anf "Virtual button for Dynamic regulation of Dampfer system";
CM_ SG_ 2527679771 LIMU_Reset_switch_HMI_Anf "Reset virtual button for Slider setting reset";
CM_ SG_ 2527679771 MainUnit_02_BZ "4bit Botschaftszähler, wird mit jeder Sendebotschaft inkrementiert";
CM_ SG_ 2527679771 MainUnit_02_CRC "Für MLB:
Berechnung siehe Lastenheft 'Kommunikationsabsicherung für FlexRay und CAN'
Ab MQB und MLBevo:
Berechnung siehe Lastenheft 'End-to-End Kommunikationsabsicherung'

Endwerte siehe Begleitdokument 'S-PDU Kennungsfolgen'";
CM_ SG_ 2527679771 ZR_ECR_LevelMode_HMI_Anf "Electro-chromic glass level request";
CM_ SG_ 2527679771 ZR_ECR_SwitchMode_HMI_Anf "Electro-chromic glass mode request";
CM_ SG_ 2527679771 ZR_Slider_soll_01 "Information about the slider request";
CM_ SG_ 2527679771 ZR_Slider_soll_02 "Information about the slider request";
CM_ SG_ 2527679771 ZR_Slider_soll_03 "Information about the slider request";

CM_ SG_ 1639 BFS_Fond_Bed_Ack "Bestätigung Beifahrersitzverstellung vom Fond";
CM_ SG_ 1639 BFS_FSV_ausgeklappt "Zustandssignalisierung der el. mech. Fußstütze (eingeklappt oder ausgeklappt)";
CM_ SG_ 1639 BFS_GHV_aktiv "Verstellung Gurthoehe
";
CM_ SG_ 1639 BFS_Gurtbringer_Sperre "Freigabesignal für den Gurtzubringer";
CM_ SG_ 1639 BFS_Klapptisch_offen "Signalisiert eine Verstelleinschränkung des Beifahrersitz  (für BAP Visualisierung)";
CM_ SG_ 1639 BFS_Kollisionsbereich_Windschott "Beifahrersitz steht innerhalb oder außerhalb Windschottbereich. Sitzposition in Kennfeld bedeutet: Windschott kann ohne Kollision ausfahren.";
CM_ SG_ 1639 BFS_Kollisionsgefahr_Windschott "Warnmeldung in Kombi anzeigen, dass manuelle oder automatische Sitzfahrt nicht (mehr) möglich ist, da Kollisionsgefahr zwischen Sitz und Windschott besteht.";
CM_ SG_ 1639 BFS_KSS_Fahrt_aktiv "Komfortseitensichtfahrt (BFS)";
CM_ SG_ 1639 BFS_KSV_aktiv "Kopfstuetzenverstellung BFS
";
CM_ SG_ 1639 BFS_Lehne_nicht_verriegelt "Fahrer Sitz Lehne Verstellung Verriegelt Status

Verwendung nur im  Bentley";
CM_ SG_ 1639 BFS_LHV_aktiv "Verstellung Lordose Höhe
";
CM_ SG_ 1639 BFS_LKV_aktiv "Verstellung Lehnenkopf
";
CM_ SG_ 1639 BFS_LNV_aktiv "Verstellung Lehnenneigung
";
CM_ SG_ 1639 BFS_LWV_aktiv "Lordose W Verstellung
";
CM_ SG_ 1639 BFS_MMB_glob_stop "Abbruch Memoryverstellung";
CM_ SG_ 1639 BFS_MMB_lokal_Stop "mit dem lokal Stop moechte man, dass ein Sitz mit Pneumatik - Lordose sich im Memoryfall wie ein Sitz mit elektromechanischer Lordose verhaelt. Nur lokler Abbruch im TIP-Betrieb.";
CM_ SG_ 1639 BFS_MMB_storage "Speichern auf Memoryposition";
CM_ SG_ 1639 BFS_MMB_storage_beep "Quittierungston Sitzmemory BFS (Anforderung Kombi)

";
CM_ SG_ 1639 BFS_MMB_store "Speichern der Sitzposition
";
CM_ SG_ 1639 BFS_MMB_store_LED_on "LED für Speichern
";
CM_ SG_ 1639 BFS_MMB_tast "Memoryverstellung im Tastbetrieb";
CM_ SG_ 1639 BFS_MMB_tipp "Memoryverstellung im Tippbetrieb";
CM_ SG_ 1639 BFS_NFA_einfahren "Neigungsverstellbare Fussauflage im Fond muss eingefahren werden";
CM_ SG_ 1639 BFS_Ruhestellung_Status "dient der Signalisierung für eine Verstelleinschränkung, da der Sitz sich in Ruhestellung befindet.";
CM_ SG_ 1639 BFS_Seat_Locked "Anzeige des gesperrten Beifahrersitzes aufgrund ungültiger Sitzposition.";
CM_ SG_ 1639 BFS_SHV_aktiv "Sitzhöhenverstellung
";
CM_ SG_ 1639 BFS_Sitzfahrt_aktiv "Aktive Sitzfahrt";
CM_ SG_ 1639 BFS_Sitzsym_Fahrt_aktiv "Sitzsymetriefahrt
";
CM_ SG_ 1639 BFS_SLV_aktiv "Sitzlängsverstellung
";
CM_ SG_ 1639 BFS_SNV_aktiv "Verstellung Sitzneigung
";
CM_ SG_ 1639 BFS_STV_aktiv "Sitztiefeverstellung
";
BA_DEF_REL_ BU_SG_REL_  "GenSigTimeoutTime" INT 0 65535;
BA_DEF_ BO_  "DiagRequest" ENUM "No", "Yes";
BA_DEF_ BO_  "DiagResponse" ENUM "No", "Yes";
BA_DEF_ BO_  "DiagState" ENUM "No", "Yes";
BA_DEF_ BO_  "GenMsgChkConstant" HEX 0 4095;
BA_DEF_ BO_  "GenMsgCycleTime" INT 0 65535;
BA_DEF_ BO_  "GenMsgCycleTimeFast" INT 0 65535;
BA_DEF_ BO_  "GenMsgDelayTime" INT 0 100000;
BA_DEF_ BO_  "GenMsgILSupport" ENUM "No", "Yes";
BA_DEF_ BO_  "GenMsgNrOfRepetition" INT 0 100;
BA_DEF_ BO_  "GenMsgPDUConstants" STRING;
BA_DEF_ BO_  "GenMsgSendType" ENUM "Cyclic", "not_used", "not_used", "not_used", "not_used", "not_used", "not_used", "IfActive", "NoMsgSendType";
BA_DEF_ BO_  "GenMsgStartDelayTime" INT 0 100000;
BA_DEF_ BO_  "NmMessage" ENUM "No", "Yes";
BA_DEF_ BO_  "NmhMessage" ENUM "No", "Yes";
BA_DEF_ BO_  "MsgType" ENUM "Application", "NM ", "NMH", "TP2.0", "ISO-TP ", "BAP", "EID", "KS", "XCP_PRE_CONFIGURED", "XCP_RUNTIME_CONFIGURED";
BA_DEF_ BO_  "VAGTP20_API" HEX 0 255;
BA_DEF_ BO_  "VAGTP20_DynConnection" ENUM "No", "Yes";
BA_DEF_ BO_  "VAGTP20_DynSetup" ENUM "No", "Yes";
BA_DEF_ BO_  "VAGTP20_StatConnection" ENUM "No", "Yes";
BA_DEF_ SG_  "GenSigActiveRepetitions" INT -2147483648 2147483647;
BA_DEF_ SG_  "GenSigInactiveValue" INT -2147483648 2147483647;
BA_DEF_ SG_  "GenSigSendType" ENUM "Cyclic", "OnWrite", "OnWriteWithRepetition", "OnChange", "OnChangeWithRepetition", "IfActive", "IfActiveWithRepetition", "NoSigSendType", "OnChangeAndIfActive", "OnChangeAndIfActiveWithRepetition";
BA_DEF_ SG_  "GenSigStartValue" INT -2147483648 2147483647;
BA_DEF_ SG_  "NWM-WakeupAllowed" ENUM "No", "Yes";
BA_DEF_ SG_  "GenSigFuncType" ENUM "NoFunction", "MsgCounter", "CRC-8", "XOR", "XOR-2", "DatedBit", "SW-Kl15", "CHK", "Constant", "Protocol", "CRC-8-SAE_J1850", "CRC-32", "DataLength", "DataID", "MsgCounter16", "SOK-Signatur", "Cluster";
BA_DEF_ SG_  "GenSigSwitchedByIgnition" ENUM "No", "Yes";
BA_DEF_ SG_  "Fehlerwert" HEX 0 2147483647;
BA_DEF_ SG_  "GenSigMissingSourceValue" HEX 0 2147483647;
BA_DEF_DEF_REL_  "GenSigTimeoutTime" 0;
BA_DEF_DEF_  "DiagRequest" "No";
BA_DEF_DEF_  "DiagResponse" "No";
BA_DEF_DEF_  "DiagState" "No";
BA_DEF_DEF_  "GenMsgChkConstant" 0;
BA_DEF_DEF_  "GenMsgCycleTime" 0;
BA_DEF_DEF_  "GenMsgCycleTimeFast" 0;
BA_DEF_DEF_  "GenMsgDelayTime" 0;
BA_DEF_DEF_  "GenMsgILSupport" "No";
BA_DEF_DEF_  "GenMsgNrOfRepetition" 0;
BA_DEF_DEF_  "GenMsgPDUConstants" "";
BA_DEF_DEF_  "GenMsgSendType" "NoMsgSendType";
BA_DEF_DEF_  "GenMsgStartDelayTime" 0;
BA_DEF_DEF_  "NmMessage" "No";
BA_DEF_DEF_  "NmhMessage" "No";
BA_DEF_DEF_  "MsgType" "Application";
BA_DEF_DEF_  "VAGTP20_API" 0;
BA_DEF_DEF_  "VAGTP20_DynConnection" "No";
BA_DEF_DEF_  "VAGTP20_DynSetup" "No";
BA_DEF_DEF_  "VAGTP20_StatConnection" "No";
BA_DEF_DEF_  "GenSigActiveRepetitions" 0;
BA_DEF_DEF_  "GenSigInactiveValue" 0;
BA_DEF_DEF_  "GenSigSendType" "NoSigSendType";
BA_DEF_DEF_  "GenSigStartValue" 0;
BA_DEF_DEF_  "NWM-WakeupAllowed" "No";
BA_DEF_DEF_  "GenSigFuncType" "NoFunction";
BA_DEF_DEF_  "GenSigSwitchedByIgnition" "Yes";
BA_DEF_DEF_  "Fehlerwert" 0;
BA_DEF_DEF_  "GenSigMissingSourceValue" 0;
BA_ "GenMsgCycleTime" BO_ 1719 1000;
BA_ "GenMsgDelayTime" BO_ 1719 100;
BA_ "GenMsgILSupport" BO_ 1719 1;
BA_ "GenMsgSendType" BO_ 1719 0;
BA_ "GenMsgCycleTime" BO_ 1720 500;
BA_ "GenMsgILSupport" BO_ 1720 1;
BA_ "GenMsgSendType" BO_ 1720 0;
BA_ "GenMsgCycleTime" BO_ 1724 1000;
BA_ "GenMsgILSupport" BO_ 1724 1;
BA_ "GenMsgSendType" BO_ 1724 0;
BA_ "GenMsgCycleTime" BO_ 2527679638 1000;
BA_ "GenMsgDelayTime" BO_ 2527679638 100;
BA_ "GenMsgILSupport" BO_ 2527679638 1;
BA_ "GenMsgSendType" BO_ 2527679638 0;
BA_ "GenMsgCycleTime" BO_ 2527679639 1000;
BA_ "GenMsgCycleTimeFast" BO_ 2527679639 100;
BA_ "GenMsgDelayTime" BO_ 2527679639 100;
BA_ "GenMsgILSupport" BO_ 2527679639 1;
BA_ "GenMsgSendType" BO_ 2527679639 0;
BA_ "GenMsgCycleTime" BO_ 2527679656 1000;
BA_ "GenMsgDelayTime" BO_ 2527679656 50;
BA_ "GenMsgILSupport" BO_ 2527679656 1;
BA_ "GenMsgSendType" BO_ 2527679656 0;
BA_ "GenMsgStartDelayTime" BO_ 2527679656 450;
BA_ "MsgType" BO_ 2549875055 4;
BA_ "MsgType" BO_ 2550006127 4;
BA_ "MsgType" BO_ 2549875059 4;
BA_ "MsgType" BO_ 2550006131 4;
BA_ "MsgType" BO_ 2549875056 4;
BA_ "MsgType" BO_ 2550006128 4;
BA_ "MsgType" BO_ 2549875053 4;
BA_ "MsgType" BO_ 2550006125 4;
BA_ "GenMsgCycleTime" BO_ 701 40;
BA_ "GenMsgILSupport" BO_ 701 1;
BA_ "GenMsgSendType" BO_ 701 0;
BA_ "GenMsgCycleTime" BO_ 2527679653 960;
BA_ "GenMsgDelayTime" BO_ 2527679653 80;
BA_ "GenMsgILSupport" BO_ 2527679653 1;
BA_ "GenMsgSendType" BO_ 2527679653 0;
BA_ "GenMsgCycleTime" BO_ 2463978818 320;
BA_ "GenMsgDelayTime" BO_ 2463978818 20;
BA_ "GenMsgILSupport" BO_ 2463978818 1;
BA_ "GenMsgPDUConstants" BO_ 2463978818 "0x96,0xb2,0xc5,0x01,0x2d,0x0c,0xe0,0xf8,0x50,0x8a,0x08,0xd7,0x62,0xf2,0xf5,0x33";
BA_ "GenMsgSendType" BO_ 2463978818 0;
BA_ "GenMsgCycleTime" BO_ 2527679780 1000;
BA_ "GenMsgDelayTime" BO_ 2527679780 50;
BA_ "GenMsgILSupport" BO_ 2527679780 1;
BA_ "GenMsgSendType" BO_ 2527679780 0;
BA_ "GenMsgCycleTime" BO_ 2463978684 100;
BA_ "GenMsgILSupport" BO_ 2463978684 1;
BA_ "GenMsgSendType" BO_ 2463978684 0;
BA_ "GenMsgCycleTime" BO_ 548 20;
BA_ "GenMsgILSupport" BO_ 548 1;
BA_ "GenMsgSendType" BO_ 548 0;
BA_ "GenMsgCycleTime" BO_ 2589283974 1000;
BA_ "GenMsgILSupport" BO_ 2589283974 1;
BA_ "GenMsgSendType" BO_ 2589283974 0;
BA_ "GenMsgCycleTime" BO_ 981 100;
BA_ "GenMsgDelayTime" BO_ 981 50;
BA_ "GenMsgILSupport" BO_ 981 1;
BA_ "GenMsgPDUConstants" BO_ 981 "0xc5,0x39,0xc7,0xf9,0x92,0xd8,0x24,0xce,0xf1,0xb5,0x7a,0xc4,0xbc,0x60,0xe3,0xd1";
BA_ "GenMsgSendType" BO_ 981 0;
BA_ "GenMsgCycleTime" BO_ 982 100;
BA_ "GenMsgILSupport" BO_ 982 1;
BA_ "GenMsgPDUConstants" BO_ 982 "0xc5,0x8e,0x64,0x95,0x9e,0xed,0x60,0x45,0x5d,0x8d,0xb2,0x80,0xa1,0x23,0x7d,0x35";
BA_ "GenMsgSendType" BO_ 982 0;
BA_ "GenMsgCycleTime" BO_ 1624 1000;
BA_ "GenMsgDelayTime" BO_ 1624 50;
BA_ "GenMsgILSupport" BO_ 1624 1;
BA_ "GenMsgPDUConstants" BO_ 1624 "0x46,0x0f,0xe0,0xcc,0xbe,0xb1,0xd7,0xf1,0x1f,0x31,0xc1,0x25,0xb4,0x3e,0xc8,0xa3";
BA_ "GenMsgSendType" BO_ 1624 0;
BA_ "GenMsgCycleTime" BO_ 1321 200;
BA_ "GenMsgDelayTime" BO_ 1321 20;
BA_ "GenMsgILSupport" BO_ 1321 1;
BA_ "GenMsgSendType" BO_ 1321 0;
BA_ "GenMsgCycleTime" BO_ 822 120;
BA_ "GenMsgILSupport" BO_ 822 1;
BA_ "GenMsgSendType" BO_ 822 0;
BA_ "GenMsgCycleTime" BO_ 2527679774 500;
BA_ "GenMsgDelayTime" BO_ 2527679774 50;
BA_ "GenMsgILSupport" BO_ 2527679774 1;
BA_ "GenMsgSendType" BO_ 2527679774 0;
BA_ "GenMsgChkConstant" BO_ 134 134;
BA_ "GenMsgCycleTime" BO_ 134 100;
BA_ "GenMsgILSupport" BO_ 134 1;
BA_ "GenMsgPDUConstants" BO_ 134 "0x86,0x86,0x86,0x86,0x86,0x86,0x86,0x86,0x86,0x86,0x86,0x86,0x86,0x86,0x86,0x86";
BA_ "GenMsgSendType" BO_ 134 0;
BA_ "GenMsgCycleTime" BO_ 917 100;
BA_ "GenMsgDelayTime" BO_ 917 10;
BA_ "GenMsgILSupport" BO_ 917 1;
BA_ "GenMsgSendType" BO_ 917 0;
BA_ "GenMsgCycleTime" BO_ 1153 500;
BA_ "GenMsgCycleTimeFast" BO_ 1153 50;
BA_ "GenMsgDelayTime" BO_ 1153 50;
BA_ "GenMsgILSupport" BO_ 1153 1;
BA_ "GenMsgNrOfRepetition" BO_ 1153 5;
BA_ "GenMsgSendType" BO_ 1153 0;
BA_ "GenMsgStartDelayTime" BO_ 1153 10;
BA_ "GenMsgCycleTime" BO_ 2527679771 500;
BA_ "GenMsgDelayTime" BO_ 2527679771 50;
BA_ "GenMsgILSupport" BO_ 2527679771 1;
BA_ "GenMsgPDUConstants" BO_ 2527679771 "0x1a,0xab,0x8f,0xd8,0x5f,0x05,0x58,0x17,0xb0,0x16,0x98,0x76,0x0d,0xc7,0xa4,0xbe";
BA_ "GenMsgSendType" BO_ 2527679771 0;
BA_ "GenMsgCycleTime" BO_ 1639 100;
BA_ "GenMsgDelayTime" BO_ 1639 50;
BA_ "GenMsgILSupport" BO_ 1639 1;
BA_ "GenMsgSendType" BO_ 1639 0;
BA_ "GenSigSendType" SG_ 1719 KBI_aktive_Laengsfunktion 3;
BA_ "GenSigSendType" SG_ 1719 KBI_Aussen_Temp_gef 0;
BA_ "GenSigStartValue" SG_ 1719 KBI_Aussen_Temp_gef 254;
BA_ "GenSigSwitchedByIgnition" SG_ 1719 KBI_Aussen_Temp_gef 0;
BA_ "Fehlerwert" SG_ 1719 KBI_Aussen_Temp_gef 255;
BA_ "GenSigSendType" SG_ 1719 KBI_FoD_PopUP_Quittiert 3;
BA_ "GenSigSendType" SG_ 1719 KBI_FStatus_Tank 0;
BA_ "GenSigSwitchedByIgnition" SG_ 1719 KBI_FStatus_Tank 0;
BA_ "GenSigSendType" SG_ 1719 KBI_GRA_im_ACC 3;
BA_ "GenSigSwitchedByIgnition" SG_ 1719 KBI_GRA_im_ACC 0;
BA_ "GenSigSendType" SG_ 1719 KBI_Inhalt_Tank 0;
BA_ "GenSigStartValue" SG_ 1719 KBI_Inhalt_Tank 126;
BA_ "GenSigSwitchedByIgnition" SG_ 1719 KBI_Inhalt_Tank 0;
BA_ "Fehlerwert" SG_ 1719 KBI_Inhalt_Tank 127;
BA_ "GenSigSendType" SG_ 1719 KBI_Kilometerstand 0;
BA_ "GenSigStartValue" SG_ 1719 KBI_Kilometerstand 1048574;
BA_ "GenSigSwitchedByIgnition" SG_ 1719 KBI_Kilometerstand 0;
BA_ "Fehlerwert" SG_ 1719 KBI_Kilometerstand 1048575;
BA_ "GenSigSendType" SG_ 1719 KBI_LVDS_Lock 3;
BA_ "GenSigSwitchedByIgnition" SG_ 1719 KBI_LVDS_Lock 0;
BA_ "GenSigSendType" SG_ 1719 KBI_Oelwechsel_durchgefuehrt 0;
BA_ "GenSigSwitchedByIgnition" SG_ 1719 KBI_Oelwechsel_durchgefuehrt 0;
BA_ "GenSigSendType" SG_ 1719 KBI_QBit_Aussen_Temp_gef 0;
BA_ "GenSigStartValue" SG_ 1719 KBI_QBit_Aussen_Temp_gef 1;
BA_ "GenSigSwitchedByIgnition" SG_ 1719 KBI_QBit_Aussen_Temp_gef 0;
BA_ "GenSigSendType" SG_ 1719 KBI_RDK_Kalibrier_Anf 3;
BA_ "GenSigSwitchedByIgnition" SG_ 1719 KBI_RDK_Kalibrier_Anf 0;
BA_ "GenSigSendType" SG_ 1719 KBI_Reserve_Warnung_Sek 3;
BA_ "GenSigSwitchedByIgnition" SG_ 1719 KBI_Reserve_Warnung_Sek 0;
BA_ "GenSigSendType" SG_ 1719 KBI_Standzeit_02 0;
BA_ "GenSigStartValue" SG_ 1719 KBI_Standzeit_02 131070;
BA_ "GenSigSwitchedByIgnition" SG_ 1719 KBI_Standzeit_02 0;
BA_ "Fehlerwert" SG_ 1719 KBI_Standzeit_02 131071;
BA_ "GenSigSendType" SG_ 1720 KBI_BCmE_aktiv 0;
BA_ "GenSigSwitchedByIgnition" SG_ 1720 KBI_BCmE_aktiv 0;
BA_ "GenSigSendType" SG_ 1720 KBI_GAP_Warn_Zeit_abgelaufen 0;
BA_ "GenSigSwitchedByIgnition" SG_ 1720 KBI_GAP_Warn_Zeit_abgelaufen 0;
BA_ "GenSigSendType" SG_ 1720 KBI_Max_Tankinhalt 0;
BA_ "GenSigStartValue" SG_ 1720 KBI_Max_Tankinhalt 254;
BA_ "GenSigSwitchedByIgnition" SG_ 1720 KBI_Max_Tankinhalt 0;
BA_ "Fehlerwert" SG_ 1720 KBI_Max_Tankinhalt 255;
BA_ "GenSigSendType" SG_ 1720 KBI_Nachtanken_erkannt 0;
BA_ "GenSigSwitchedByIgnition" SG_ 1720 KBI_Nachtanken_erkannt 0;
BA_ "GenSigSendType" SG_ 1720 KBI_Quittierung_cAQP 0;
BA_ "GenSigSwitchedByIgnition" SG_ 1720 KBI_Quittierung_cAQP 0;
BA_ "GenSigSendType" SG_ 1720 KBI_Quittierung_Naesse 0;
BA_ "GenSigSwitchedByIgnition" SG_ 1720 KBI_Quittierung_Naesse 0;
BA_ "GenSigSendType" SG_ 1720 KBI_Reifenumfang 0;
BA_ "GenSigFuncType" SG_ 1720 KBI_Reifenumfang 8;
BA_ "GenSigSwitchedByIgnition" SG_ 1720 KBI_Reifenumfang 0;
BA_ "GenSigSendType" SG_ 1720 KBI_Reifenumfang_Sekundaer 0;
BA_ "GenSigSwitchedByIgnition" SG_ 1720 KBI_Reifenumfang_Sekundaer 0;
BA_ "GenSigSendType" SG_ 1720 KBI_Sparhinweis_quittiert 0;
BA_ "GenSigSwitchedByIgnition" SG_ 1720 KBI_Sparhinweis_quittiert 0;
BA_ "GenSigSendType" SG_ 1720 KBI_Tankfuellstand_Prozent 0;
BA_ "GenSigStartValue" SG_ 1720 KBI_Tankfuellstand_Prozent 126;
BA_ "GenSigSwitchedByIgnition" SG_ 1720 KBI_Tankfuellstand_Prozent 0;
BA_ "Fehlerwert" SG_ 1720 KBI_Tankfuellstand_Prozent 127;
BA_ "GenSigSendType" SG_ 1720 KBI_Tankinhalt_hochaufl 0;
BA_ "GenSigStartValue" SG_ 1720 KBI_Tankinhalt_hochaufl 16382;
BA_ "GenSigSwitchedByIgnition" SG_ 1720 KBI_Tankinhalt_hochaufl 0;
BA_ "Fehlerwert" SG_ 1720 KBI_Tankinhalt_hochaufl 16383;
BA_ "GenSigSendType" SG_ 1720 KBI_Variante 0;
BA_ "GenSigSwitchedByIgnition" SG_ 1720 KBI_Variante 0;
BA_ "GenSigSendType" SG_ 1720 KBI_Variante_USA 0;
BA_ "GenSigSwitchedByIgnition" SG_ 1720 KBI_Variante_USA 0;
BA_ "GenSigSendType" SG_ 1724 KBI_Insp_dis 0;
BA_ "GenSigSwitchedByIgnition" SG_ 1724 KBI_Insp_dis 0;
BA_ "GenSigSendType" SG_ 1724 KBI_Insp_dis_status 0;
BA_ "GenSigSwitchedByIgnition" SG_ 1724 KBI_Insp_dis_status 0;
BA_ "GenSigSendType" SG_ 1724 KBI_Insp_dis_unit 0;
BA_ "GenSigSwitchedByIgnition" SG_ 1724 KBI_Insp_dis_unit 0;
BA_ "GenSigSendType" SG_ 1724 KBI_Insp_time 0;
BA_ "GenSigSwitchedByIgnition" SG_ 1724 KBI_Insp_time 0;
BA_ "GenSigSendType" SG_ 1724 KBI_Insp_time_status 0;
BA_ "GenSigSwitchedByIgnition" SG_ 1724 KBI_Insp_time_status 0;
BA_ "GenSigSendType" SG_ 1724 KBI_Oil_dis 0;
BA_ "GenSigSwitchedByIgnition" SG_ 1724 KBI_Oil_dis 0;
BA_ "GenSigSendType" SG_ 1724 KBI_Oil_dis_status 0;
BA_ "GenSigSwitchedByIgnition" SG_ 1724 KBI_Oil_dis_status 0;
BA_ "GenSigSendType" SG_ 1724 KBI_Oil_dis_unit 0;
BA_ "GenSigSwitchedByIgnition" SG_ 1724 KBI_Oil_dis_unit 0;
BA_ "GenSigSendType" SG_ 1724 KBI_Oil_time 0;
BA_ "GenSigSwitchedByIgnition" SG_ 1724 KBI_Oil_time 0;
BA_ "GenSigSendType" SG_ 1724 KBI_Oil_time_status 0;
BA_ "GenSigSwitchedByIgnition" SG_ 1724 KBI_Oil_time_status 0;
BA_ "GenSigSendType" SG_ 1724 KBI_Warnung_ID 0;
BA_ "GenSigSwitchedByIgnition" SG_ 1724 KBI_Warnung_ID 0;
BA_ "GenSigSendType" SG_ 2527679638 KBI_GZeit_HSek 3;
BA_ "GenSigSwitchedByIgnition" SG_ 2527679638 KBI_GZeit_HSek 0;
BA_ "GenSigSendType" SG_ 2527679638 KBI_GZeit_Min 3;
BA_ "GenSigSwitchedByIgnition" SG_ 2527679638 KBI_GZeit_Min 0;
BA_ "GenSigSendType" SG_ 2527679638 KBI_GZeit_Sek 3;
BA_ "GenSigSwitchedByIgnition" SG_ 2527679638 KBI_GZeit_Sek 0;
BA_ "GenSigSendType" SG_ 2527679638 KBI_GZeit_Std 3;
BA_ "GenSigSwitchedByIgnition" SG_ 2527679638 KBI_GZeit_Std 0;
BA_ "GenSigSendType" SG_ 2527679638 KBI_RZ_Nr 3;
BA_ "GenSigSwitchedByIgnition" SG_ 2527679638 KBI_RZ_Nr 0;
BA_ "GenSigSendType" SG_ 2527679638 KBI_RZeit_HSek 3;
BA_ "GenSigSwitchedByIgnition" SG_ 2527679638 KBI_RZeit_HSek 0;
BA_ "GenSigSendType" SG_ 2527679638 KBI_RZeit_Min 3;
BA_ "GenSigSwitchedByIgnition" SG_ 2527679638 KBI_RZeit_Min 0;
BA_ "GenSigSendType" SG_ 2527679638 KBI_RZeit_Sek 3;
BA_ "GenSigSwitchedByIgnition" SG_ 2527679638 KBI_RZeit_Sek 0;
BA_ "GenSigSendType" SG_ 2527679638 KBI_RZeit_Std 3;
BA_ "GenSigSwitchedByIgnition" SG_ 2527679638 KBI_RZeit_Std 0;
BA_ "GenSigSendType" SG_ 2527679638 KBI_Status_StoppUhr 3;
BA_ "GenSigSwitchedByIgnition" SG_ 2527679638 KBI_Status_StoppUhr 0;
BA_ "GenSigSendType" SG_ 2527679639 KBI_Jokerkey 3;
BA_ "GenSigSwitchedByIgnition" SG_ 2527679639 KBI_Jokerkey 0;
BA_ "GenSigSendType" SG_ 2527679639 KBI_RS_Druck_uebernehmen 3;
BA_ "GenSigSwitchedByIgnition" SG_ 2527679639 KBI_RS_Druck_uebernehmen 0;
BA_ "GenSigSendType" SG_ 2527679639 KBI_RS_Druckauswahl_Aktiv 3;
BA_ "GenSigSwitchedByIgnition" SG_ 2527679639 KBI_RS_Druckauswahl_Aktiv 0;
BA_ "GenSigSendType" SG_ 2527679639 KBI_RS_Mode_fortsetzen 3;
BA_ "GenSigSwitchedByIgnition" SG_ 2527679639 KBI_RS_Mode_fortsetzen 0;
BA_ "GenSigSendType" SG_ 2527679639 KBI_Rundstreckenmodus 3;
BA_ "GenSigSwitchedByIgnition" SG_ 2527679639 KBI_Rundstreckenmodus 0;
BA_ "GenSigSendType" SG_ 2527679639 KBI_Weg_Zaehler 3;
BA_ "GenSigSwitchedByIgnition" SG_ 2527679639 KBI_Weg_Zaehler 0;
BA_ "GenSigSendType" SG_ 2527679639 KBI_Weg_Zaehler_F 3;
BA_ "GenSigSwitchedByIgnition" SG_ 2527679639 KBI_Weg_Zaehler_F 0;
BA_ "Fehlerwert" SG_ 2527679639 KBI_Weg_Zaehler_F 1;
BA_ "GenSigSendType" SG_ 2527679656 KBI_StartupAnimation 3;
BA_ "GenSigSwitchedByIgnition" SG_ 2527679656 KBI_StartupAnimation 0;
BA_ "GenSigSendType" SG_ 2549875055 KS_AMP_Req_Data 3;
BA_ "GenSigFuncType" SG_ 2549875055 KS_AMP_Req_Data 9;
BA_ "GenSigSwitchedByIgnition" SG_ 2549875055 KS_AMP_Req_Data 0;
BA_ "GenSigSendType" SG_ 2550006127 KS_AMP_Resp_Data 3;
BA_ "GenSigFuncType" SG_ 2550006127 KS_AMP_Resp_Data 9;
BA_ "GenSigSwitchedByIgnition" SG_ 2550006127 KS_AMP_Resp_Data 0;
BA_ "GenSigSendType" SG_ 2549875059 KS_Info_El_Req_Data 3;
BA_ "GenSigFuncType" SG_ 2549875059 KS_Info_El_Req_Data 9;
BA_ "GenSigSwitchedByIgnition" SG_ 2549875059 KS_Info_El_Req_Data 0;
BA_ "GenSigSendType" SG_ 2550006131 KS_Info_El_Resp_Data 3;
BA_ "GenSigFuncType" SG_ 2550006131 KS_Info_El_Resp_Data 9;
BA_ "GenSigSwitchedByIgnition" SG_ 2550006131 KS_Info_El_Resp_Data 0;
BA_ "GenSigSendType" SG_ 2549875056 KS_Laufwerke_Req_Data 3;
BA_ "GenSigFuncType" SG_ 2549875056 KS_Laufwerke_Req_Data 9;
BA_ "GenSigSwitchedByIgnition" SG_ 2549875056 KS_Laufwerke_Req_Data 0;
BA_ "GenSigSendType" SG_ 2550006128 KS_Laufwerke_Resp_Data 3;
BA_ "GenSigFuncType" SG_ 2550006128 KS_Laufwerke_Resp_Data 9;
BA_ "GenSigSwitchedByIgnition" SG_ 2550006128 KS_Laufwerke_Resp_Data 0;
BA_ "GenSigSendType" SG_ 2549875053 KS_TV_Tuner_Req_Data 3;
BA_ "GenSigFuncType" SG_ 2549875053 KS_TV_Tuner_Req_Data 9;
BA_ "GenSigSwitchedByIgnition" SG_ 2549875053 KS_TV_Tuner_Req_Data 0;
BA_ "GenSigSendType" SG_ 2550006125 KS_TV_Tuner_Resp_Data 3;
BA_ "GenSigFuncType" SG_ 2550006125 KS_TV_Tuner_Resp_Data 9;
BA_ "GenSigSwitchedByIgnition" SG_ 2550006125 KS_TV_Tuner_Resp_Data 0;
BA_ "GenSigSendType" SG_ 701 LAE_Beta_confidence 0;
BA_ "GenSigSendType" SG_ 701 LAE_Beta_VZ 0;
BA_ "GenSigSendType" SG_ 701 LAE_BetaSlipAngle 0;
BA_ "GenSigStartValue" SG_ 701 LAE_BetaSlipAngle 254;
BA_ "GenSigSwitchedByIgnition" SG_ 701 LAE_BetaSlipAngle 0;
BA_ "Fehlerwert" SG_ 701 LAE_BetaSlipAngle 255;
BA_ "GenSigSendType" SG_ 701 LAE_BetaSlipAngle_02 0;
BA_ "GenSigStartValue" SG_ 701 LAE_BetaSlipAngle_02 32766;
BA_ "GenSigSwitchedByIgnition" SG_ 701 LAE_BetaSlipAngle_02 0;
BA_ "Fehlerwert" SG_ 701 LAE_BetaSlipAngle_02 32767;
BA_ "GenSigSendType" SG_ 701 LAE_mu 0;
BA_ "GenSigStartValue" SG_ 701 LAE_mu 62;
BA_ "Fehlerwert" SG_ 701 LAE_mu 63;
BA_ "GenSigSendType" SG_ 701 LAE_mu_confidence 0;
BA_ "GenSigSendType" SG_ 701 LAE_Vx 0;
BA_ "GenSigStartValue" SG_ 701 LAE_Vx 510;
BA_ "Fehlerwert" SG_ 701 LAE_Vx 511;
BA_ "GenSigSendType" SG_ 701 LAE_Vx_confidence 0;
BA_ "GenSigSendType" SG_ 701 LAE_Vx_VZ 0;
BA_ "GenSigSendType" SG_ 701 LAE_Vy 0;
BA_ "GenSigStartValue" SG_ 701 LAE_Vy 62;
BA_ "Fehlerwert" SG_ 701 LAE_Vy 63;
BA_ "GenSigSendType" SG_ 701 LAE_Vy_confidence 0;
BA_ "GenSigSendType" SG_ 2527679653 MXB_LAPP_Freigabe 3;
BA_ "GenSigSendType" SG_ 2527679653 MXB_LAPP_Status_FL 3;
BA_ "GenSigSendType" SG_ 2527679653 MXB_LAPP_Statuscode 3;
BA_ "GenSigStartValue" SG_ 2527679653 MXB_LAPP_Statuscode 1023;
BA_ "GenSigSendType" SG_ 2527679653 MXB_LAPP_ZR_Sondermodus_Anf 3;
BA_ "GenSigSendType" SG_ 2463978818 BTM_BrakeSystem_Status 3;
BA_ "Fehlerwert" SG_ 2463978818 BTM_BrakeSystem_Status 7;
BA_ "GenSigSendType" SG_ 2463978818 BTM_BrakeSystem_Text 3;
BA_ "GenSigSendType" SG_ 2463978818 BTM_BrakeSystem_Warnlampe 3;
BA_ "GenSigSendType" SG_ 2463978818 LCV_01_BZ 0;
BA_ "GenSigFuncType" SG_ 2463978818 LCV_01_BZ 1;
BA_ "GenSigSwitchedByIgnition" SG_ 2463978818 LCV_01_BZ 0;
BA_ "GenSigSendType" SG_ 2463978818 LCV_01_CRC 0;
BA_ "GenSigFuncType" SG_ 2463978818 LCV_01_CRC 2;
BA_ "GenSigSwitchedByIgnition" SG_ 2463978818 LCV_01_CRC 0;
BA_ "GenSigSendType" SG_ 2463978818 LCV_Aero_EngineBay_Cooling 3;
BA_ "GenSigSendType" SG_ 2463978818 LCV_Aero_Front_System_Status 3;
BA_ "GenSigSendType" SG_ 2463978818 LCV_Aero_Perf_Limit 3;
BA_ "GenSigSendType" SG_ 2463978818 LCV_Aero_Perf_Limit_Speed 3;
BA_ "GenSigStartValue" SG_ 2463978818 LCV_Aero_Perf_Limit_Speed 254;
BA_ "Fehlerwert" SG_ 2463978818 LCV_Aero_Perf_Limit_Speed 255;
BA_ "GenSigSendType" SG_ 2463978818 LCV_Aero_Rear_System_Status 3;
BA_ "GenSigSendType" SG_ 2463978818 LCV_BrakeGongTemp 3;
BA_ "GenSigSendType" SG_ 2463978818 LCV_DR_Systemstatus 3;
BA_ "GenSigSwitchedByIgnition" SG_ 2463978818 LCV_DR_Systemstatus 0;
BA_ "GenSigSendType" SG_ 2463978818 LCV_DR_Text 3;
BA_ "GenSigSwitchedByIgnition" SG_ 2463978818 LCV_DR_Text 0;
BA_ "GenSigSendType" SG_ 2463978818 LCV_DR_Warnlampe 3;
BA_ "GenSigSwitchedByIgnition" SG_ 2463978818 LCV_DR_Warnlampe 0;
BA_ "GenSigSendType" SG_ 2463978818 LCV_ESP_Zuschaltung 3;
BA_ "GenSigSendType" SG_ 2463978818 LCV_HD_offen 3;
BA_ "GenSigSwitchedByIgnition" SG_ 2463978818 LCV_HD_offen 0;
BA_ "GenSigSendType" SG_ 2463978818 LCV_Lift_Status 3;
BA_ "GenSigSwitchedByIgnition" SG_ 2463978818 LCV_Lift_Status 0;
BA_ "Fehlerwert" SG_ 2463978818 LCV_Lift_Status 7;
BA_ "GenSigSendType" SG_ 2463978818 LCV_Lift_Text 3;
BA_ "GenSigSendType" SG_ 2463978818 LCV_Lift_Warnlampe_Status 3;
BA_ "GenSigSendType" SG_ 2527679780 LCV_Aero_BarMode_Activation 3;
BA_ "GenSigSendType" SG_ 2527679780 LCV_Aero_Button_Default 3;
BA_ "GenSigSendType" SG_ 2527679780 LCV_Aero_Button_Range 3;
BA_ "GenSigSendType" SG_ 2527679780 LCV_Aero_Button_Select 3;
BA_ "GenSigSendType" SG_ 2527679780 LCV_Aero_Button_Tunable 3;
BA_ "GenSigSendType" SG_ 2527679780 LCV_BarMode_Allowed 3;
BA_ "GenSigSendType" SG_ 2527679780 LCV_DR_Button_Default 3;
BA_ "GenSigSendType" SG_ 2527679780 LCV_DR_Button_Range 3;
BA_ "GenSigSendType" SG_ 2527679780 LCV_DR_Button_Select 3;
BA_ "GenSigSendType" SG_ 2527679780 LCV_DR_Button_Tunable 3;
BA_ "GenSigSendType" SG_ 2463978684 BTM_BrakeDiscTemp_01 0;
BA_ "GenSigStartValue" SG_ 2463978684 BTM_BrakeDiscTemp_01 254;
BA_ "Fehlerwert" SG_ 2463978684 BTM_BrakeDiscTemp_01 255;
BA_ "GenSigSendType" SG_ 2463978684 BTM_BrakeDiscTemp_02 0;
BA_ "GenSigStartValue" SG_ 2463978684 BTM_BrakeDiscTemp_02 254;
BA_ "Fehlerwert" SG_ 2463978684 BTM_BrakeDiscTemp_02 255;
BA_ "GenSigSendType" SG_ 2463978684 BTM_BrakeDiscTemp_03 0;
BA_ "GenSigStartValue" SG_ 2463978684 BTM_BrakeDiscTemp_03 254;
BA_ "Fehlerwert" SG_ 2463978684 BTM_BrakeDiscTemp_03 255;
BA_ "GenSigSendType" SG_ 2463978684 BTM_BrakeDiscTemp_04 0;
BA_ "GenSigStartValue" SG_ 2463978684 BTM_BrakeDiscTemp_04 254;
BA_ "Fehlerwert" SG_ 2463978684 BTM_BrakeDiscTemp_04 255;
BA_ "GenSigSendType" SG_ 2463978684 BTM_BrakeFluidTemp_01 0;
BA_ "GenSigStartValue" SG_ 2463978684 BTM_BrakeFluidTemp_01 254;
BA_ "Fehlerwert" SG_ 2463978684 BTM_BrakeFluidTemp_01 255;
BA_ "GenSigSendType" SG_ 2463978684 BTM_BrakeFluidTemp_02 0;
BA_ "GenSigStartValue" SG_ 2463978684 BTM_BrakeFluidTemp_02 254;
BA_ "Fehlerwert" SG_ 2463978684 BTM_BrakeFluidTemp_02 255;
BA_ "GenSigSendType" SG_ 2463978684 BTM_BrakeFluidTemp_03 0;
BA_ "GenSigStartValue" SG_ 2463978684 BTM_BrakeFluidTemp_03 254;
BA_ "Fehlerwert" SG_ 2463978684 BTM_BrakeFluidTemp_03 255;
BA_ "GenSigSendType" SG_ 2463978684 BTM_BrakeFluidTemp_04 0;
BA_ "GenSigStartValue" SG_ 2463978684 BTM_BrakeFluidTemp_04 254;
BA_ "Fehlerwert" SG_ 2463978684 BTM_BrakeFluidTemp_04 255;
BA_ "GenSigSendType" SG_ 548 LCV_Aero_Front_Ratio 0;
BA_ "GenSigStartValue" SG_ 548 LCV_Aero_Front_Ratio 126;
BA_ "Fehlerwert" SG_ 548 LCV_Aero_Front_Ratio 127;
BA_ "GenSigSendType" SG_ 548 LCV_Aero_Long_Ratio 0;
BA_ "GenSigStartValue" SG_ 548 LCV_Aero_Long_Ratio 126;
BA_ "Fehlerwert" SG_ 548 LCV_Aero_Long_Ratio 127;
BA_ "GenSigSendType" SG_ 2589283974 BTM_BrakeDiscColour_01 0;
BA_ "GenSigSwitchedByIgnition" SG_ 2589283974 BTM_BrakeDiscColour_01 0;
BA_ "Fehlerwert" SG_ 2589283974 BTM_BrakeDiscColour_01 7;
BA_ "GenSigSendType" SG_ 2589283974 BTM_BrakeDiscColour_02 0;
BA_ "GenSigSwitchedByIgnition" SG_ 2589283974 BTM_BrakeDiscColour_02 0;
BA_ "Fehlerwert" SG_ 2589283974 BTM_BrakeDiscColour_02 7;
BA_ "GenSigSendType" SG_ 2589283974 BTM_BrakeDiscColour_03 0;
BA_ "GenSigSwitchedByIgnition" SG_ 2589283974 BTM_BrakeDiscColour_03 0;
BA_ "Fehlerwert" SG_ 2589283974 BTM_BrakeDiscColour_03 7;
BA_ "GenSigSendType" SG_ 2589283974 BTM_BrakeDiscColour_04 0;
BA_ "GenSigSwitchedByIgnition" SG_ 2589283974 BTM_BrakeDiscColour_04 0;
BA_ "Fehlerwert" SG_ 2589283974 BTM_BrakeDiscColour_04 7;
BA_ "GenSigSendType" SG_ 2589283974 BTM_BrakeFluidColour_01 0;
BA_ "GenSigSwitchedByIgnition" SG_ 2589283974 BTM_BrakeFluidColour_01 0;
BA_ "Fehlerwert" SG_ 2589283974 BTM_BrakeFluidColour_01 7;
BA_ "GenSigSendType" SG_ 2589283974 BTM_BrakeFluidColour_02 0;
BA_ "GenSigSwitchedByIgnition" SG_ 2589283974 BTM_BrakeFluidColour_02 0;
BA_ "Fehlerwert" SG_ 2589283974 BTM_BrakeFluidColour_02 7;
BA_ "GenSigSendType" SG_ 2589283974 BTM_BrakeFluidColour_03 0;
BA_ "GenSigSwitchedByIgnition" SG_ 2589283974 BTM_BrakeFluidColour_03 0;
BA_ "Fehlerwert" SG_ 2589283974 BTM_BrakeFluidColour_03 7;
BA_ "GenSigSendType" SG_ 2589283974 BTM_BrakeFluidColour_04 0;
BA_ "GenSigSwitchedByIgnition" SG_ 2589283974 BTM_BrakeFluidColour_04 0;
BA_ "Fehlerwert" SG_ 2589283974 BTM_BrakeFluidColour_04 7;
BA_ "GenSigSendType" SG_ 981 BCM1_Abblendlicht_Anf 0;
BA_ "GenSigSwitchedByIgnition" SG_ 981 BCM1_Abblendlicht_Anf 0;
BA_ "GenSigSendType" SG_ 981 BCM1_Adaptive_Lichtvert_Anf 0;
BA_ "GenSigSwitchedByIgnition" SG_ 981 BCM1_Adaptive_Lichtvert_Anf 0;
BA_ "GenSigSendType" SG_ 981 BCM1_Allwetterlicht_Anf 0;
BA_ "GenSigSwitchedByIgnition" SG_ 981 BCM1_Allwetterlicht_Anf 0;
BA_ "GenSigSendType" SG_ 981 BCM1_Animationssperrung 3;
BA_ "GenSigStartValue" SG_ 981 BCM1_Animationssperrung 1;
BA_ "GenSigSwitchedByIgnition" SG_ 981 BCM1_Animationssperrung 0;
BA_ "GenSigSendType" SG_ 981 BCM1_Autobahnlicht_Anf 0;
BA_ "GenSigSwitchedByIgnition" SG_ 981 BCM1_Autobahnlicht_Anf 0;
BA_ "GenSigSendType" SG_ 981 BCM1_CH_aktiv 0;
BA_ "NWM-WakeupAllowed" SG_ 981 BCM1_CH_aktiv 1;
BA_ "GenSigSwitchedByIgnition" SG_ 981 BCM1_CH_aktiv 0;
BA_ "GenSigSendType" SG_ 981 BCM1_CH_LH_aktiv 0;
BA_ "GenSigSwitchedByIgnition" SG_ 981 BCM1_CH_LH_aktiv 0;
BA_ "GenSigSendType" SG_ 981 BCM1_Fernlicht_Anf 0;
BA_ "GenSigSwitchedByIgnition" SG_ 981 BCM1_Fernlicht_Anf 0;
BA_ "GenSigSendType" SG_ 981 BCM1_FOD_Sperrung_Animationen_HL 3;
BA_ "GenSigStartValue" SG_ 981 BCM1_FOD_Sperrung_Animationen_HL 2;
BA_ "GenSigSendType" SG_ 981 BCM1_FoD_Sperrung_WiBli 3;
BA_ "GenSigStartValue" SG_ 981 BCM1_FoD_Sperrung_WiBli 2;
BA_ "GenSigSendType" SG_ 981 BCM1_Gleitende_Leuchtw_Anf 3;
BA_ "GenSigSwitchedByIgnition" SG_ 981 BCM1_Gleitende_Leuchtw_Anf 0;
BA_ "GenSigSendType" SG_ 981 BCM1_GLW_Fernlicht_Anf 3;
BA_ "GenSigSwitchedByIgnition" SG_ 981 BCM1_GLW_Fernlicht_Anf 0;
BA_ "GenSigSendType" SG_ 981 BCM1_Kurvenlicht_links_Anf 0;
BA_ "GenSigSwitchedByIgnition" SG_ 981 BCM1_Kurvenlicht_links_Anf 0;
BA_ "GenSigSendType" SG_ 981 BCM1_Kurvenlicht_rechts_Anf 0;
BA_ "GenSigSwitchedByIgnition" SG_ 981 BCM1_Kurvenlicht_rechts_Anf 0;
BA_ "GenSigSendType" SG_ 981 BCM1_LH_aktiv 0;
BA_ "NWM-WakeupAllowed" SG_ 981 BCM1_LH_aktiv 1;
BA_ "GenSigSwitchedByIgnition" SG_ 981 BCM1_LH_aktiv 0;
BA_ "GenSigSendType" SG_ 981 BCM1_Nebellicht_Anf 0;
BA_ "GenSigSwitchedByIgnition" SG_ 981 BCM1_Nebellicht_Anf 0;
BA_ "GenSigSendType" SG_ 981 BCM1_Nebelschluss_Ahg_Anf 0;
BA_ "GenSigSwitchedByIgnition" SG_ 981 BCM1_Nebelschluss_Ahg_Anf 0;
BA_ "GenSigSendType" SG_ 981 BCM1_Nebelschluss_Fzg_Anf 0;
BA_ "GenSigSwitchedByIgnition" SG_ 981 BCM1_Nebelschluss_Fzg_Anf 0;
BA_ "GenSigSendType" SG_ 981 BCM1_Parklicht_li_Anf 0;
BA_ "GenSigSwitchedByIgnition" SG_ 981 BCM1_Parklicht_li_Anf 0;
BA_ "GenSigSendType" SG_ 981 BCM1_Parklicht_re_Anf 0;
BA_ "GenSigSwitchedByIgnition" SG_ 981 BCM1_Parklicht_re_Anf 0;
BA_ "GenSigSendType" SG_ 981 BCM1_Regenlicht_Anf 0;
BA_ "GenSigSwitchedByIgnition" SG_ 981 BCM1_Regenlicht_Anf 0;
BA_ "GenSigSendType" SG_ 981 BCM1_Schlusslicht_Anf 0;
BA_ "GenSigSwitchedByIgnition" SG_ 981 BCM1_Schlusslicht_Anf 0;
BA_ "GenSigSendType" SG_ 981 BCM1_Schlusslicht_Signatur 0;
BA_ "GenSigSwitchedByIgnition" SG_ 981 BCM1_Schlusslicht_Signatur 0;
BA_ "GenSigSendType" SG_ 981 BCM1_Signaturlicht_Anf 0;
BA_ "GenSigSwitchedByIgnition" SG_ 981 BCM1_Signaturlicht_Anf 0;
BA_ "GenSigSendType" SG_ 981 BCM1_Standlicht_Anf 0;
BA_ "GenSigSwitchedByIgnition" SG_ 981 BCM1_Standlicht_Anf 0;
BA_ "GenSigSendType" SG_ 981 BCM1_Tagfahrlicht_Anf 0;
BA_ "GenSigSwitchedByIgnition" SG_ 981 BCM1_Tagfahrlicht_Anf 0;
BA_ "GenSigSendType" SG_ 981 BCM1_Touristen_Licht_Anf 0;
BA_ "GenSigSwitchedByIgnition" SG_ 981 BCM1_Touristen_Licht_Anf 0;
BA_ "GenSigSendType" SG_ 981 BCM1_Umfeldleuchten_Anf 0;
BA_ "GenSigSwitchedByIgnition" SG_ 981 BCM1_Umfeldleuchten_Anf 0;
BA_ "GenSigSendType" SG_ 981 BCM_Rueckfahrlicht_Anf 0;
BA_ "GenSigSwitchedByIgnition" SG_ 981 BCM_Rueckfahrlicht_Anf 0;
BA_ "GenSigSendType" SG_ 981 Licht_Anf_01_BZ 0;
BA_ "GenSigFuncType" SG_ 981 Licht_Anf_01_BZ 1;
BA_ "GenSigSwitchedByIgnition" SG_ 981 Licht_Anf_01_BZ 0;
BA_ "GenSigSendType" SG_ 981 Licht_Anf_01_CRC 0;
BA_ "GenSigFuncType" SG_ 981 Licht_Anf_01_CRC 2;
BA_ "GenSigSwitchedByIgnition" SG_ 981 Licht_Anf_01_CRC 0;
BA_ "GenSigSendType" SG_ 982 BCM2_Bremsl_durch_ECD 0;
BA_ "GenSigSwitchedByIgnition" SG_ 982 BCM2_Bremsl_durch_ECD 0;
BA_ "GenSigSendType" SG_ 982 LH_3_Bremsl_def 0;
BA_ "GenSigSwitchedByIgnition" SG_ 982 LH_3_Bremsl_def 0;
BA_ "GenSigSendType" SG_ 982 LH_Aussenlicht_def 0;
BA_ "GenSigSwitchedByIgnition" SG_ 982 LH_Aussenlicht_def 0;
BA_ "GenSigSendType" SG_ 982 LH_Blinker_HL_akt 0;
BA_ "GenSigSwitchedByIgnition" SG_ 982 LH_Blinker_HL_akt 0;
BA_ "GenSigSendType" SG_ 982 LH_Blinker_HR_akt 0;
BA_ "GenSigSwitchedByIgnition" SG_ 982 LH_Blinker_HR_akt 0;
BA_ "GenSigSendType" SG_ 982 LH_Blinker_li_def 0;
BA_ "GenSigSwitchedByIgnition" SG_ 982 LH_Blinker_li_def 0;
BA_ "GenSigSendType" SG_ 982 LH_Blinker_re_def 0;
BA_ "GenSigSwitchedByIgnition" SG_ 982 LH_Blinker_re_def 0;
BA_ "GenSigSendType" SG_ 982 LH_Brems_Blk_li_def 0;
BA_ "GenSigSwitchedByIgnition" SG_ 982 LH_Brems_Blk_li_def 0;
BA_ "GenSigSendType" SG_ 982 LH_Brems_Blk_re_def 0;
BA_ "GenSigSwitchedByIgnition" SG_ 982 LH_Brems_Blk_re_def 0;
BA_ "GenSigSendType" SG_ 982 LH_Bremsl_li_def 0;
BA_ "GenSigSwitchedByIgnition" SG_ 982 LH_Bremsl_li_def 0;
BA_ "GenSigSendType" SG_ 982 LH_Bremsl_li_ges_def 0;
BA_ "GenSigSwitchedByIgnition" SG_ 982 LH_Bremsl_li_ges_def 0;
BA_ "GenSigSendType" SG_ 982 LH_Bremsl_mi_def 0;
BA_ "GenSigSwitchedByIgnition" SG_ 982 LH_Bremsl_mi_def 0;
BA_ "GenSigSendType" SG_ 982 LH_Bremsl_re_def 0;
BA_ "GenSigSwitchedByIgnition" SG_ 982 LH_Bremsl_re_def 0;
BA_ "GenSigSendType" SG_ 982 LH_Bremsl_re_ges_def 0;
BA_ "GenSigSwitchedByIgnition" SG_ 982 LH_Bremsl_re_ges_def 0;
BA_ "GenSigSendType" SG_ 982 LH_Bremslicht_H_aktiv 0;
BA_ "GenSigSwitchedByIgnition" SG_ 982 LH_Bremslicht_H_aktiv 0;
BA_ "GenSigSendType" SG_ 982 LH_Diag_LED_li_def 0;
BA_ "GenSigSwitchedByIgnition" SG_ 982 LH_Diag_LED_li_def 0;
BA_ "GenSigSendType" SG_ 982 LH_Diag_LED_re_def 0;
BA_ "GenSigSwitchedByIgnition" SG_ 982 LH_Diag_LED_re_def 0;
BA_ "GenSigSendType" SG_ 982 LH_Diag_Status_li_def 0;
BA_ "GenSigSwitchedByIgnition" SG_ 982 LH_Diag_Status_li_def 0;
BA_ "GenSigSendType" SG_ 982 LH_Diag_Status_re_def 0;
BA_ "GenSigSwitchedByIgnition" SG_ 982 LH_Diag_Status_re_def 0;
BA_ "GenSigSendType" SG_ 982 LH_Kennzl_def 0;
BA_ "GenSigSwitchedByIgnition" SG_ 982 LH_Kennzl_def 0;
BA_ "GenSigSendType" SG_ 982 LH_Nebel_li_def 0;
BA_ "GenSigSwitchedByIgnition" SG_ 982 LH_Nebel_li_def 0;
BA_ "GenSigSendType" SG_ 982 LH_Nebel_mi_def 0;
BA_ "GenSigSwitchedByIgnition" SG_ 982 LH_Nebel_mi_def 0;
BA_ "GenSigSendType" SG_ 982 LH_Nebel_re_def 0;
BA_ "GenSigSwitchedByIgnition" SG_ 982 LH_Nebel_re_def 0;
BA_ "GenSigSendType" SG_ 982 LH_Nebelschluss_aktiv 0;
BA_ "GenSigSwitchedByIgnition" SG_ 982 LH_Nebelschluss_aktiv 0;
BA_ "GenSigSendType" SG_ 982 LH_Parklicht_HL_aktiv 0;
BA_ "GenSigSwitchedByIgnition" SG_ 982 LH_Parklicht_HL_aktiv 0;
BA_ "GenSigSendType" SG_ 982 LH_Parklicht_HR_aktiv 0;
BA_ "GenSigSwitchedByIgnition" SG_ 982 LH_Parklicht_HR_aktiv 0;
BA_ "GenSigSendType" SG_ 982 LH_Rueckf_li_def 0;
BA_ "GenSigSwitchedByIgnition" SG_ 982 LH_Rueckf_li_def 0;
BA_ "GenSigSendType" SG_ 982 LH_Rueckf_mi_def 0;
BA_ "GenSigSwitchedByIgnition" SG_ 982 LH_Rueckf_mi_def 0;
BA_ "GenSigSendType" SG_ 982 LH_Rueckf_re_def 0;
BA_ "GenSigSwitchedByIgnition" SG_ 982 LH_Rueckf_re_def 0;
BA_ "GenSigSendType" SG_ 982 LH_Rueckfahrlicht_aktiv 0;
BA_ "GenSigSwitchedByIgnition" SG_ 982 LH_Rueckfahrlicht_aktiv 0;
BA_ "GenSigSendType" SG_ 982 LH_Schluss_Brems_li_def 0;
BA_ "GenSigSwitchedByIgnition" SG_ 982 LH_Schluss_Brems_li_def 0;
BA_ "GenSigSendType" SG_ 982 LH_Schluss_Brems_mi_def 0;
BA_ "GenSigSwitchedByIgnition" SG_ 982 LH_Schluss_Brems_mi_def 0;
BA_ "GenSigSendType" SG_ 982 LH_Schluss_Brems_Nebel_li_def 0;
BA_ "GenSigSwitchedByIgnition" SG_ 982 LH_Schluss_Brems_Nebel_li_def 0;
BA_ "GenSigSendType" SG_ 982 LH_Schluss_Brems_Nebel_re_def 0;
BA_ "GenSigSwitchedByIgnition" SG_ 982 LH_Schluss_Brems_Nebel_re_def 0;
BA_ "GenSigSendType" SG_ 982 LH_Schluss_Brems_re_def 0;
BA_ "GenSigSwitchedByIgnition" SG_ 982 LH_Schluss_Brems_re_def 0;
BA_ "GenSigSendType" SG_ 982 LH_Schluss_Nebel_li_def 0;
BA_ "GenSigSwitchedByIgnition" SG_ 982 LH_Schluss_Nebel_li_def 0;
BA_ "GenSigSendType" SG_ 982 LH_Schluss_Nebel_re_def 0;
BA_ "GenSigSwitchedByIgnition" SG_ 982 LH_Schluss_Nebel_re_def 0;
BA_ "GenSigSendType" SG_ 982 LH_Schlusslicht_li_def 0;
BA_ "GenSigSwitchedByIgnition" SG_ 982 LH_Schlusslicht_li_def 0;
BA_ "GenSigSendType" SG_ 982 LH_Schlusslicht_mi_def 0;
BA_ "GenSigSwitchedByIgnition" SG_ 982 LH_Schlusslicht_mi_def 0;
BA_ "GenSigSendType" SG_ 982 LH_Schlusslicht_re_def 0;
BA_ "GenSigSwitchedByIgnition" SG_ 982 LH_Schlusslicht_re_def 0;
BA_ "GenSigSendType" SG_ 982 LH_SL_BRL_BLK_li_def 0;
BA_ "GenSigSwitchedByIgnition" SG_ 982 LH_SL_BRL_BLK_li_def 0;
BA_ "GenSigSendType" SG_ 982 LH_SL_BRL_BLK_re_def 0;
BA_ "GenSigSwitchedByIgnition" SG_ 982 LH_SL_BRL_BLK_re_def 0;
BA_ "GenSigSendType" SG_ 982 LH_Standlicht_H_aktiv 0;
BA_ "GenSigSwitchedByIgnition" SG_ 982 LH_Standlicht_H_aktiv 0;
BA_ "GenSigSendType" SG_ 982 LH_Zusatzschlussl_def 0;
BA_ "GenSigSwitchedByIgnition" SG_ 982 LH_Zusatzschlussl_def 0;
BA_ "GenSigSendType" SG_ 1624 BCM1_Licht_Dunkelheit_aktiv 3;
BA_ "GenSigSwitchedByIgnition" SG_ 1624 BCM1_Licht_Dunkelheit_aktiv 0;
BA_ "GenSigSendType" SG_ 1624 BCM1_Linksverkehr 0;
BA_ "GenSigSwitchedByIgnition" SG_ 1624 BCM1_Linksverkehr 0;
BA_ "GenSigSendType" SG_ 1624 Licht_Vorne_01_BZ 0;
BA_ "GenSigFuncType" SG_ 1624 Licht_Vorne_01_BZ 1;
BA_ "GenSigSendType" SG_ 1624 Licht_Vorne_01_CRC 0;
BA_ "GenSigFuncType" SG_ 1624 Licht_Vorne_01_CRC 2;
BA_ "GenSigSendType" SG_ 1624 LV_Abbiegelicht_li_def 0;
BA_ "GenSigSwitchedByIgnition" SG_ 1624 LV_Abbiegelicht_li_def 0;
BA_ "GenSigSendType" SG_ 1624 LV_Abbiegelicht_re_def 0;
BA_ "GenSigSwitchedByIgnition" SG_ 1624 LV_Abbiegelicht_re_def 0;
BA_ "GenSigSendType" SG_ 1624 LV_Abblend_Fernlicht_li_def 0;
BA_ "GenSigSwitchedByIgnition" SG_ 1624 LV_Abblend_Fernlicht_li_def 0;
BA_ "GenSigSendType" SG_ 1624 LV_Abblend_Fernlicht_re_def 0;
BA_ "GenSigSwitchedByIgnition" SG_ 1624 LV_Abblend_Fernlicht_re_def 0;
BA_ "GenSigSendType" SG_ 1624 LV_Abblendlicht_Anzeige 3;
BA_ "GenSigSwitchedByIgnition" SG_ 1624 LV_Abblendlicht_Anzeige 0;
BA_ "GenSigSendType" SG_ 1624 LV_Abblendlicht_li_def 0;
BA_ "GenSigSwitchedByIgnition" SG_ 1624 LV_Abblendlicht_li_def 0;
BA_ "GenSigSendType" SG_ 1624 LV_Abblendlicht_re_def 0;
BA_ "GenSigSwitchedByIgnition" SG_ 1624 LV_Abblendlicht_re_def 0;
BA_ "GenSigSendType" SG_ 1624 LV_Abblendlicht_TFL_li_def 0;
BA_ "GenSigSwitchedByIgnition" SG_ 1624 LV_Abblendlicht_TFL_li_def 0;
BA_ "GenSigSendType" SG_ 1624 LV_Abblendlicht_TFL_re_def 0;
BA_ "GenSigSwitchedByIgnition" SG_ 1624 LV_Abblendlicht_TFL_re_def 0;
BA_ "GenSigSendType" SG_ 1624 LV_AFL_aktiv_Anzeige 3;
BA_ "GenSigSwitchedByIgnition" SG_ 1624 LV_AFL_aktiv_Anzeige 0;
BA_ "GenSigSendType" SG_ 1624 LV_AFL_defekt 3;
BA_ "GenSigSwitchedByIgnition" SG_ 1624 LV_AFL_defekt 0;
BA_ "GenSigSendType" SG_ 1624 LV_Aussenlicht_def 3;
BA_ "GenSigSwitchedByIgnition" SG_ 1624 LV_Aussenlicht_def 0;
BA_ "GenSigSendType" SG_ 1624 LV_Blinker_li_def 3;
BA_ "GenSigSwitchedByIgnition" SG_ 1624 LV_Blinker_li_def 0;
BA_ "GenSigSendType" SG_ 1624 LV_Blinker_re_def 3;
BA_ "GenSigSwitchedByIgnition" SG_ 1624 LV_Blinker_re_def 0;
BA_ "GenSigSendType" SG_ 1624 LV_Blinker_VL_aktiv 3;
BA_ "GenSigSwitchedByIgnition" SG_ 1624 LV_Blinker_VL_aktiv 0;
BA_ "GenSigSendType" SG_ 1624 LV_Blinker_VR_aktiv 3;
BA_ "GenSigSwitchedByIgnition" SG_ 1624 LV_Blinker_VR_aktiv 0;
BA_ "GenSigSendType" SG_ 1624 LV_Blk_li_Seite_def 0;
BA_ "GenSigSwitchedByIgnition" SG_ 1624 LV_Blk_li_Seite_def 0;
BA_ "GenSigSendType" SG_ 1624 LV_Blk_re_Seite_def 0;
BA_ "GenSigSwitchedByIgnition" SG_ 1624 LV_Blk_re_Seite_def 0;
BA_ "GenSigSendType" SG_ 1624 LV_Fernlicht_Anzeige 3;
BA_ "GenSigSwitchedByIgnition" SG_ 1624 LV_Fernlicht_Anzeige 0;
BA_ "GenSigSendType" SG_ 1624 LV_Fernlicht_li_def 0;
BA_ "GenSigSwitchedByIgnition" SG_ 1624 LV_Fernlicht_li_def 0;
BA_ "GenSigSendType" SG_ 1624 LV_Fernlicht_re_def 0;
BA_ "GenSigSwitchedByIgnition" SG_ 1624 LV_Fernlicht_re_def 0;
BA_ "GenSigSendType" SG_ 1624 LV_FLA_aktiv_Anzeige 3;
BA_ "GenSigSwitchedByIgnition" SG_ 1624 LV_FLA_aktiv_Anzeige 0;
BA_ "GenSigSendType" SG_ 1624 LV_FLA_defekt 0;
BA_ "GenSigSwitchedByIgnition" SG_ 1624 LV_FLA_defekt 0;
BA_ "GenSigSendType" SG_ 1624 LV_FLA_Sensor_blockiert 0;
BA_ "GenSigSwitchedByIgnition" SG_ 1624 LV_FLA_Sensor_blockiert 0;
BA_ "GenSigSendType" SG_ 1624 LV_LED_Scheinwerfer_li_def 0;
BA_ "GenSigSwitchedByIgnition" SG_ 1624 LV_LED_Scheinwerfer_li_def 0;
BA_ "GenSigSendType" SG_ 1624 LV_LED_Scheinwerfer_re_def 0;
BA_ "GenSigSwitchedByIgnition" SG_ 1624 LV_LED_Scheinwerfer_re_def 0;
BA_ "GenSigSendType" SG_ 1624 LV_MXB_Status_Anzeige 3;
BA_ "GenSigSwitchedByIgnition" SG_ 1624 LV_MXB_Status_Anzeige 0;
BA_ "GenSigSendType" SG_ 1624 LV_Nebellicht_Anzeige 3;
BA_ "GenSigSwitchedByIgnition" SG_ 1624 LV_Nebellicht_Anzeige 0;
BA_ "GenSigSendType" SG_ 1624 LV_Nebellicht_li_def 0;
BA_ "GenSigSwitchedByIgnition" SG_ 1624 LV_Nebellicht_li_def 0;
BA_ "GenSigSendType" SG_ 1624 LV_Nebellicht_re_def 0;
BA_ "GenSigSwitchedByIgnition" SG_ 1624 LV_Nebellicht_re_def 0;
BA_ "GenSigSendType" SG_ 1624 LV_Nebellicht_TFL_li_def 0;
BA_ "GenSigSwitchedByIgnition" SG_ 1624 LV_Nebellicht_TFL_li_def 0;
BA_ "GenSigSendType" SG_ 1624 LV_Nebellicht_TFL_re_def 0;
BA_ "GenSigSwitchedByIgnition" SG_ 1624 LV_Nebellicht_TFL_re_def 0;
BA_ "GenSigSendType" SG_ 1624 LV_Nebelschlusslicht_Anzeige 3;
BA_ "GenSigSwitchedByIgnition" SG_ 1624 LV_Nebelschlusslicht_Anzeige 0;
BA_ "GenSigSendType" SG_ 1624 LV_Standlicht_Anzeige 3;
BA_ "GenSigSwitchedByIgnition" SG_ 1624 LV_Standlicht_Anzeige 0;
BA_ "GenSigSendType" SG_ 1624 LV_Standlicht_li_def 0;
BA_ "GenSigSwitchedByIgnition" SG_ 1624 LV_Standlicht_li_def 0;
BA_ "GenSigSendType" SG_ 1624 LV_Standlicht_re_def 0;
BA_ "GenSigSwitchedByIgnition" SG_ 1624 LV_Standlicht_re_def 0;
BA_ "GenSigSendType" SG_ 1624 LV_Standlicht_TFL_li_def 0;
BA_ "GenSigSwitchedByIgnition" SG_ 1624 LV_Standlicht_TFL_li_def 0;
BA_ "GenSigSendType" SG_ 1624 LV_Standlicht_TFL_re_def 0;
BA_ "GenSigSwitchedByIgnition" SG_ 1624 LV_Standlicht_TFL_re_def 0;
BA_ "GenSigSendType" SG_ 1624 LV_Tagfahrlicht_Anzeige 3;
BA_ "GenSigSwitchedByIgnition" SG_ 1624 LV_Tagfahrlicht_Anzeige 0;
BA_ "GenSigSendType" SG_ 1624 LV_Tagfahrlicht_li_def 0;
BA_ "GenSigSwitchedByIgnition" SG_ 1624 LV_Tagfahrlicht_li_def 0;
BA_ "GenSigSendType" SG_ 1624 LV_Tagfahrlicht_re_def 0;
BA_ "GenSigSwitchedByIgnition" SG_ 1624 LV_Tagfahrlicht_re_def 0;
BA_ "GenSigSendType" SG_ 1321 Lift_Anforderung_EFP 3;
BA_ "GenSigSwitchedByIgnition" SG_ 1321 Lift_Anforderung_EFP 0;
BA_ "GenSigSendType" SG_ 1321 Lift_Charisma_FahrPr 3;
BA_ "GenSigSwitchedByIgnition" SG_ 1321 Lift_Charisma_FahrPr 0;
BA_ "GenSigSendType" SG_ 1321 Lift_Charisma_Status 3;
BA_ "GenSigSwitchedByIgnition" SG_ 1321 Lift_Charisma_Status 0;
BA_ "GenSigSendType" SG_ 1321 Lift_Charisma_Umschaltung 3;
BA_ "GenSigSwitchedByIgnition" SG_ 1321 Lift_Charisma_Umschaltung 0;
BA_ "GenSigSendType" SG_ 1321 Lift_ESP_Zuschaltung 3;
BA_ "GenSigSwitchedByIgnition" SG_ 1321 Lift_ESP_Zuschaltung 0;
BA_ "GenSigSendType" SG_ 1321 Lift_LED 3;
BA_ "GenSigSwitchedByIgnition" SG_ 1321 Lift_LED 0;
BA_ "Fehlerwert" SG_ 1321 Lift_LED 3;
BA_ "GenSigSendType" SG_ 1321 Lift_Meldung_01 3;
BA_ "GenSigSwitchedByIgnition" SG_ 1321 Lift_Meldung_01 0;
BA_ "GenSigSendType" SG_ 1321 Lift_Meldung_02 3;
BA_ "GenSigSwitchedByIgnition" SG_ 1321 Lift_Meldung_02 0;
BA_ "GenSigSendType" SG_ 1321 Lift_Meldung_03 3;
BA_ "GenSigSwitchedByIgnition" SG_ 1321 Lift_Meldung_03 0;
BA_ "GenSigSendType" SG_ 1321 Lift_Meldung_04 3;
BA_ "GenSigSwitchedByIgnition" SG_ 1321 Lift_Meldung_04 0;
BA_ "GenSigSendType" SG_ 1321 Lift_Meldung_05 3;
BA_ "GenSigSwitchedByIgnition" SG_ 1321 Lift_Meldung_05 0;
BA_ "GenSigSendType" SG_ 1321 Lift_Meldung_06 3;
BA_ "GenSigSwitchedByIgnition" SG_ 1321 Lift_Meldung_06 0;
BA_ "GenSigSendType" SG_ 1321 Lift_Meldung_07 3;
BA_ "GenSigSwitchedByIgnition" SG_ 1321 Lift_Meldung_07 0;
BA_ "GenSigSendType" SG_ 1321 Lift_Meldung_08 3;
BA_ "GenSigSwitchedByIgnition" SG_ 1321 Lift_Meldung_08 0;
BA_ "GenSigSendType" SG_ 1321 Lift_Meldung_09 3;
BA_ "GenSigSwitchedByIgnition" SG_ 1321 Lift_Meldung_09 0;
BA_ "GenSigSendType" SG_ 1321 Lift_Meldung_10 3;
BA_ "GenSigSwitchedByIgnition" SG_ 1321 Lift_Meldung_10 0;
BA_ "GenSigSendType" SG_ 1321 Lift_Meldung_11 3;
BA_ "GenSigSwitchedByIgnition" SG_ 1321 Lift_Meldung_11 0;
BA_ "GenSigSendType" SG_ 1321 Lift_Meldung_12 3;
BA_ "GenSigSwitchedByIgnition" SG_ 1321 Lift_Meldung_12 0;
BA_ "GenSigSendType" SG_ 1321 Lift_Meldung_13 3;
BA_ "GenSigSwitchedByIgnition" SG_ 1321 Lift_Meldung_13 0;
BA_ "GenSigSendType" SG_ 1321 Lift_Meldung_14 3;
BA_ "GenSigSwitchedByIgnition" SG_ 1321 Lift_Meldung_14 0;
BA_ "GenSigSendType" SG_ 1321 Lift_Position 3;
BA_ "GenSigSwitchedByIgnition" SG_ 1321 Lift_Position 0;
BA_ "GenSigSendType" SG_ 1321 Lift_SpannungsAnf 3;
BA_ "GenSigSwitchedByIgnition" SG_ 1321 Lift_SpannungsAnf 0;
BA_ "GenSigSendType" SG_ 1321 Lift_StartStopp_Info 3;
BA_ "GenSigSendType" SG_ 822 LR_HZG_Taster_on_off 0;
BA_ "GenSigSwitchedByIgnition" SG_ 822 LR_HZG_Taster_on_off 0;
BA_ "GenSigSendType" SG_ 822 LR_HZG_Temp_Sensor 0;
BA_ "GenSigStartValue" SG_ 822 LR_HZG_Temp_Sensor 254;
BA_ "GenSigSwitchedByIgnition" SG_ 822 LR_HZG_Temp_Sensor 0;
BA_ "GenSigSendType" SG_ 2527679774 LRM_Auto_Error 3;
BA_ "GenSigSwitchedByIgnition" SG_ 2527679774 LRM_Auto_Error 0;
BA_ "GenSigSendType" SG_ 2527679774 LRM_General_Error 3;
BA_ "GenSigSwitchedByIgnition" SG_ 2527679774 LRM_General_Error 0;
BA_ "GenSigSendType" SG_ 2527679774 LRM_Glass_OC_Error 3;
BA_ "GenSigSwitchedByIgnition" SG_ 2527679774 LRM_Glass_OC_Error 0;
BA_ "GenSigSendType" SG_ 2527679774 LRM_Glass_Rear_OC_Error 3;
BA_ "GenSigSwitchedByIgnition" SG_ 2527679774 LRM_Glass_Rear_OC_Error 0;
BA_ "GenSigSendType" SG_ 2527679774 LRM_Glass_Rear_SC_Error 3;
BA_ "GenSigSwitchedByIgnition" SG_ 2527679774 LRM_Glass_Rear_SC_Error 0;
BA_ "GenSigSendType" SG_ 2527679774 LRM_Glass_SC_Error 3;
BA_ "GenSigSwitchedByIgnition" SG_ 2527679774 LRM_Glass_SC_Error 0;
BA_ "GenSigSendType" SG_ 2527679774 LRM_Level 3;
BA_ "GenSigStartValue" SG_ 2527679774 LRM_Level 6;
BA_ "GenSigSwitchedByIgnition" SG_ 2527679774 LRM_Level 0;
BA_ "Fehlerwert" SG_ 2527679774 LRM_Level 7;
BA_ "GenSigSendType" SG_ 2527679774 LRM_Level_Rear 3;
BA_ "GenSigStartValue" SG_ 2527679774 LRM_Level_Rear 6;
BA_ "GenSigSwitchedByIgnition" SG_ 2527679774 LRM_Level_Rear 0;
BA_ "Fehlerwert" SG_ 2527679774 LRM_Level_Rear 7;
BA_ "GenSigSendType" SG_ 2527679774 LRM_Manual_Error 3;
BA_ "GenSigSwitchedByIgnition" SG_ 2527679774 LRM_Manual_Error 0;
BA_ "GenSigSendType" SG_ 2527679774 LRM_Mode 3;
BA_ "GenSigStartValue" SG_ 2527679774 LRM_Mode 6;
BA_ "GenSigSwitchedByIgnition" SG_ 2527679774 LRM_Mode 0;
BA_ "Fehlerwert" SG_ 2527679774 LRM_Mode 7;
BA_ "GenSigSendType" SG_ 134 LWI_01_BZ 0;
BA_ "GenSigFuncType" SG_ 134 LWI_01_BZ 1;
BA_ "GenSigSendType" SG_ 134 LWI_01_CRC 0;
BA_ "GenSigFuncType" SG_ 134 LWI_01_CRC 2;
BA_ "GenSigSwitchedByIgnition" SG_ 134 LWI_01_CRC 0;
BA_ "GenSigSendType" SG_ 134 LWI_Lenkradw_Geschw 0;
BA_ "GenSigStartValue" SG_ 134 LWI_Lenkradw_Geschw 510;
BA_ "Fehlerwert" SG_ 134 LWI_Lenkradw_Geschw 511;
BA_ "GenSigSendType" SG_ 134 LWI_Lenkradwinkel 0;
BA_ "GenSigStartValue" SG_ 134 LWI_Lenkradwinkel 8190;
BA_ "Fehlerwert" SG_ 134 LWI_Lenkradwinkel 8191;
BA_ "GenSigSendType" SG_ 134 LWI_MFL_Abschaltung 0;
BA_ "GenSigSwitchedByIgnition" SG_ 134 LWI_MFL_Abschaltung 0;
BA_ "GenSigSendType" SG_ 134 LWI_QBit_Lenkradwinkel 0;
BA_ "GenSigStartValue" SG_ 134 LWI_QBit_Lenkradwinkel 1;
BA_ "GenSigSendType" SG_ 134 LWI_QBit_Sub_Daten 0;
BA_ "GenSigSendType" SG_ 134 LWI_Sensorstatus 0;
BA_ "GenSigSendType" SG_ 134 LWI_Sub_Daten 0;
BA_ "GenSigSendType" SG_ 134 LWI_VZ_Lenkradw_Geschw 0;
BA_ "GenSigSendType" SG_ 134 LWI_VZ_Lenkradwinkel 0;
BA_ "GenSigSendType" SG_ 917 AFS_Abbiegelicht_Dimm_Anf 0;
BA_ "GenSigSendType" SG_ 917 AFS_Abbiegelicht_li_Anf 0;
BA_ "GenSigSendType" SG_ 917 AFS_Abbiegelicht_re_Anf 0;
BA_ "GenSigSendType" SG_ 917 AFS_adaptive_LV_verbaut 0;
BA_ "GenSigSendType" SG_ 917 AFS_Allwetterlicht 0;
BA_ "GenSigSendType" SG_ 917 AFS_Charisma_FahrPr 0;
BA_ "GenSigSendType" SG_ 917 AFS_Charisma_Status 0;
BA_ "GenSigSendType" SG_ 917 AFS_Charisma_Umschaltung 3;
BA_ "GenSigSendType" SG_ 917 AFS_Ersatzlicht_Links 0;
BA_ "GenSigSendType" SG_ 917 AFS_Ersatzlicht_Rechts 0;
BA_ "GenSigSendType" SG_ 917 AFS_Fehlertext 0;
BA_ "GenSigSendType" SG_ 917 AFS_Fernlicht_li_defekt 0;
BA_ "GenSigSendType" SG_ 917 AFS_Fernlicht_re_defekt 0;
BA_ "GenSigSendType" SG_ 917 AFS_Fernlicht_Status 3;
BA_ "GenSigSendType" SG_ 917 AFS_Lampe 0;
BA_ "GenSigSendType" SG_ 917 AFS_LED_Blinkmode 0;
BA_ "GenSigSendType" SG_ 917 AFS_Status_adaptive_LV 0;
BA_ "GenSigStartValue" SG_ 917 AFS_Status_adaptive_LV 1;
BA_ "GenSigSendType" SG_ 917 AFS_Verfuegbarkeit_GLW 0;
BA_ "GenSigStartValue" SG_ 917 AFS_Verfuegbarkeit_GLW 1;
BA_ "GenSigSendType" SG_ 917 GLW_Sensor_blockiert 0;
BA_ "GenSigSendType" SG_ 917 LWR_AFS_01_BZ 0;
BA_ "GenSigFuncType" SG_ 917 LWR_AFS_01_BZ 1;
BA_ "GenSigSendType" SG_ 917 LWR_AFS_Grundeinstellung 0;
BA_ "GenSigSendType" SG_ 917 LWR_AFS_Parametrisierung 0;
BA_ "GenSigSendType" SG_ 917 LWR_Hoehenwert_HL 0;
BA_ "GenSigStartValue" SG_ 917 LWR_Hoehenwert_HL 254;
BA_ "Fehlerwert" SG_ 917 LWR_Hoehenwert_HL 255;
BA_ "GenSigSendType" SG_ 917 LWR_Hoehenwert_VL 0;
BA_ "GenSigStartValue" SG_ 917 LWR_Hoehenwert_VL 254;
BA_ "Fehlerwert" SG_ 917 LWR_Hoehenwert_VL 255;
BA_ "GenSigSendType" SG_ 917 LWR_Initialisierungslauf 0;
BA_ "GenSigSendType" SG_ 917 LWR_Lampe 0;
BA_ "GenSigSendType" SG_ 917 LWR_Modus 0;
BA_ "GenSigSendType" SG_ 917 LWR_Pos_Schrittmotor 0;
BA_ "GenSigStartValue" SG_ 917 LWR_Pos_Schrittmotor 254;
BA_ "Fehlerwert" SG_ 917 LWR_Pos_Schrittmotor 255;
BA_ "GenSigSendType" SG_ 917 LWR_Reisemodus_Texte 0;
BA_ "GenSigSendType" SG_ 917 LWR_Sicherheitsposition_li 0;
BA_ "GenSigSendType" SG_ 917 LWR_Sicherheitsposition_re 0;
BA_ "GenSigSendType" SG_ 917 LWR_Touristenmodus_aktiv 0;
BA_ "GenSigSendType" SG_ 917 LWR_Touristenmodus_verbaut 0;
BA_ "GenSigSendType" SG_ 1153 DSSS_Warning 3;
BA_ "GenSigSwitchedByIgnition" SG_ 1153 DSSS_Warning 0;
BA_ "GenSigSendType" SG_ 1153 MIB_Tongenerator_PH_verfuegbar 3;
BA_ "GenSigSwitchedByIgnition" SG_ 1153 MIB_Tongenerator_PH_verfuegbar 0;
BA_ "GenSigSendType" SG_ 1153 MMI_Counter_Bedienevent 0;
BA_ "GenSigSwitchedByIgnition" SG_ 1153 MMI_Counter_Bedienevent 0;
BA_ "GenSigSendType" SG_ 1153 MMI_Gauges_active 3;
BA_ "GenSigSwitchedByIgnition" SG_ 1153 MMI_Gauges_active 0;
BA_ "GenSigSendType" SG_ 1153 MMI_Gurt_Mic_ref 0;
BA_ "GenSigSwitchedByIgnition" SG_ 1153 MMI_Gurt_Mic_ref 0;
BA_ "GenSigSendType" SG_ 1153 MMI_SDS_aktiv 3;
BA_ "GenSigSwitchedByIgnition" SG_ 1153 MMI_SDS_aktiv 0;
BA_ "GenSigSendType" SG_ 1153 MMI_StartStopp_Info 3;
BA_ "GenSigSwitchedByIgnition" SG_ 1153 MMI_StartStopp_Info 0;
BA_ "Fehlerwert" SG_ 1153 MMI_StartStopp_Info 3;
BA_ "GenSigSendType" SG_ 1153 MMI_Telefon_aktiv 3;
BA_ "GenSigSwitchedByIgnition" SG_ 1153 MMI_Telefon_aktiv 0;
BA_ "GenSigSendType" SG_ 1153 MU_SecondDisplay 3;
BA_ "GenSigSwitchedByIgnition" SG_ 1153 MU_SecondDisplay 0;
BA_ "GenSigSendType" SG_ 1153 MU_Update_Time 0;
BA_ "GenSigSwitchedByIgnition" SG_ 1153 MU_Update_Time 0;
BA_ "GenSigSendType" SG_ 1153 Nav_FoD_Status 3;
BA_ "GenSigSwitchedByIgnition" SG_ 1153 Nav_FoD_Status 0;
BA_ "GenSigSendType" SG_ 1153 ZR_Kindersicherung_RSE 3;
BA_ "GenSigSwitchedByIgnition" SG_ 1153 ZR_Kindersicherung_RSE 0;
BA_ "GenSigSendType" SG_ 1153 ZR_LAPP_Sondermodus_Status 3;
BA_ "GenSigSendType" SG_ 1153 ZR_LoGeWa_Event_Kombiwarnung 3;
BA_ "GenSigSwitchedByIgnition" SG_ 1153 ZR_LoGeWa_Event_Kombiwarnung 0;
BA_ "GenSigSendType" SG_ 1153 ZR_MXB_Manoever_Ansage 3;
BA_ "GenSigSwitchedByIgnition" SG_ 1153 ZR_MXB_Manoever_Ansage 0;
BA_ "GenSigSendType" SG_ 1153 ZR_Parken_Sondermodus 3;
BA_ "GenSigSwitchedByIgnition" SG_ 1153 ZR_Parken_Sondermodus 0;
BA_ "GenSigSendType" SG_ 1153 ZR_RSE_aktivieren 3;
BA_ "GenSigSwitchedByIgnition" SG_ 1153 ZR_RSE_aktivieren 0;
BA_ "GenSigSendType" SG_ 1153 ZR_Rundenbewertung 3;
BA_ "GenSigStartValue" SG_ 1153 ZR_Rundenbewertung 14;
BA_ "GenSigSwitchedByIgnition" SG_ 1153 ZR_Rundenbewertung 0;
BA_ "GenSigSendType" SG_ 1153 ZR_Rundenfortschritt 3;
BA_ "GenSigStartValue" SG_ 1153 ZR_Rundenfortschritt 254;
BA_ "GenSigSwitchedByIgnition" SG_ 1153 ZR_Rundenfortschritt 0;
BA_ "GenSigActiveRepetitions" SG_ 1153 ZR_Sta_Inszenierung 5;
BA_ "GenSigSendType" SG_ 1153 ZR_Sta_Inszenierung 4;
BA_ "GenSigSwitchedByIgnition" SG_ 1153 ZR_Sta_Inszenierung 0;
BA_ "GenSigSendType" SG_ 2527679771 LIMU_Aero_Selec_HMI_Anf 3;
BA_ "GenSigSwitchedByIgnition" SG_ 2527679771 LIMU_Aero_Selec_HMI_Anf 0;
BA_ "GenSigSendType" SG_ 2527679771 LIMU_BAR_Mode_Switch_HMI_Anf 3;
BA_ "GenSigSwitchedByIgnition" SG_ 2527679771 LIMU_BAR_Mode_Switch_HMI_Anf 0;
BA_ "GenSigSendType" SG_ 2527679771 LIMU_Confirmation_HMI_Anf 3;
BA_ "GenSigSwitchedByIgnition" SG_ 2527679771 LIMU_Confirmation_HMI_Anf 0;
BA_ "GenSigSendType" SG_ 2527679771 LIMU_DR_Select_HMI_Anf 3;
BA_ "GenSigSwitchedByIgnition" SG_ 2527679771 LIMU_DR_Select_HMI_Anf 0;
BA_ "GenSigSendType" SG_ 2527679771 LIMU_Reset_switch_HMI_Anf 3;
BA_ "GenSigSwitchedByIgnition" SG_ 2527679771 LIMU_Reset_switch_HMI_Anf 0;
BA_ "GenSigSendType" SG_ 2527679771 MainUnit_02_BZ 0;
BA_ "GenSigFuncType" SG_ 2527679771 MainUnit_02_BZ 1;
BA_ "GenSigSwitchedByIgnition" SG_ 2527679771 MainUnit_02_BZ 0;
BA_ "GenSigSendType" SG_ 2527679771 MainUnit_02_CRC 0;
BA_ "GenSigFuncType" SG_ 2527679771 MainUnit_02_CRC 2;
BA_ "GenSigSwitchedByIgnition" SG_ 2527679771 MainUnit_02_CRC 0;
BA_ "GenSigSendType" SG_ 2527679771 ZR_ECR_LevelMode_HMI_Anf 3;
BA_ "GenSigSwitchedByIgnition" SG_ 2527679771 ZR_ECR_LevelMode_HMI_Anf 0;
BA_ "Fehlerwert" SG_ 2527679771 ZR_ECR_LevelMode_HMI_Anf 7;
BA_ "GenSigSendType" SG_ 2527679771 ZR_ECR_SwitchMode_HMI_Anf 3;
BA_ "GenSigStartValue" SG_ 2527679771 ZR_ECR_SwitchMode_HMI_Anf 3;
BA_ "GenSigSwitchedByIgnition" SG_ 2527679771 ZR_ECR_SwitchMode_HMI_Anf 0;
BA_ "Fehlerwert" SG_ 2527679771 ZR_ECR_SwitchMode_HMI_Anf 7;
BA_ "GenSigSendType" SG_ 2527679771 ZR_Slider_soll_01 3;
BA_ "GenSigStartValue" SG_ 2527679771 ZR_Slider_soll_01 127;
BA_ "GenSigSwitchedByIgnition" SG_ 2527679771 ZR_Slider_soll_01 0;
BA_ "GenSigSendType" SG_ 2527679771 ZR_Slider_soll_02 3;
BA_ "GenSigStartValue" SG_ 2527679771 ZR_Slider_soll_02 127;
BA_ "GenSigSwitchedByIgnition" SG_ 2527679771 ZR_Slider_soll_02 0;
BA_ "GenSigSendType" SG_ 2527679771 ZR_Slider_soll_03 3;
BA_ "GenSigStartValue" SG_ 2527679771 ZR_Slider_soll_03 127;
BA_ "GenSigSwitchedByIgnition" SG_ 2527679771 ZR_Slider_soll_03 0;
BA_ "GenSigSendType" SG_ 1639 BFS_Fond_Bed_Ack 3;
BA_ "GenSigSwitchedByIgnition" SG_ 1639 BFS_Fond_Bed_Ack 0;
BA_ "GenSigSendType" SG_ 1639 BFS_FSV_ausgeklappt 0;
BA_ "GenSigSwitchedByIgnition" SG_ 1639 BFS_FSV_ausgeklappt 0;
BA_ "GenSigSendType" SG_ 1639 BFS_GHV_aktiv 3;
BA_ "GenSigSwitchedByIgnition" SG_ 1639 BFS_GHV_aktiv 0;
BA_ "GenSigSendType" SG_ 1639 BFS_Gurtbringer_Sperre 0;
BA_ "GenSigSwitchedByIgnition" SG_ 1639 BFS_Gurtbringer_Sperre 0;
BA_ "GenSigSendType" SG_ 1639 BFS_Klapptisch_offen 3;
BA_ "GenSigSwitchedByIgnition" SG_ 1639 BFS_Klapptisch_offen 0;
BA_ "GenSigSendType" SG_ 1639 BFS_Kollisionsbereich_Windschott 3;
BA_ "GenSigSwitchedByIgnition" SG_ 1639 BFS_Kollisionsbereich_Windschott 0;
BA_ "GenSigSendType" SG_ 1639 BFS_Kollisionsgefahr_Windschott 3;
BA_ "GenSigSwitchedByIgnition" SG_ 1639 BFS_Kollisionsgefahr_Windschott 0;
BA_ "GenSigSendType" SG_ 1639 BFS_KSS_Fahrt_aktiv 3;
BA_ "GenSigSwitchedByIgnition" SG_ 1639 BFS_KSS_Fahrt_aktiv 0;
BA_ "GenSigSendType" SG_ 1639 BFS_KSV_aktiv 3;
BA_ "GenSigSwitchedByIgnition" SG_ 1639 BFS_KSV_aktiv 0;
BA_ "GenSigSendType" SG_ 1639 BFS_Lehne_nicht_verriegelt 3;
BA_ "GenSigSwitchedByIgnition" SG_ 1639 BFS_Lehne_nicht_verriegelt 0;
BA_ "GenSigSendType" SG_ 1639 BFS_LHV_aktiv 3;
BA_ "GenSigSwitchedByIgnition" SG_ 1639 BFS_LHV_aktiv 0;
BA_ "GenSigSendType" SG_ 1639 BFS_LKV_aktiv 3;
BA_ "GenSigSwitchedByIgnition" SG_ 1639 BFS_LKV_aktiv 0;
BA_ "GenSigSendType" SG_ 1639 BFS_LNV_aktiv 3;
BA_ "GenSigSwitchedByIgnition" SG_ 1639 BFS_LNV_aktiv 0;
BA_ "GenSigSendType" SG_ 1639 BFS_LWV_aktiv 3;
BA_ "GenSigSwitchedByIgnition" SG_ 1639 BFS_LWV_aktiv 0;
BA_ "GenSigSendType" SG_ 1639 BFS_MMB_glob_stop 3;
BA_ "GenSigSwitchedByIgnition" SG_ 1639 BFS_MMB_glob_stop 0;
BA_ "GenSigSendType" SG_ 1639 BFS_MMB_lokal_Stop 3;
BA_ "GenSigSwitchedByIgnition" SG_ 1639 BFS_MMB_lokal_Stop 0;
BA_ "GenSigSendType" SG_ 1639 BFS_MMB_storage 3;
BA_ "GenSigSwitchedByIgnition" SG_ 1639 BFS_MMB_storage 0;
BA_ "GenSigSendType" SG_ 1639 BFS_MMB_storage_beep 3;
BA_ "GenSigSwitchedByIgnition" SG_ 1639 BFS_MMB_storage_beep 0;
BA_ "GenSigSendType" SG_ 1639 BFS_MMB_store 3;
BA_ "GenSigSwitchedByIgnition" SG_ 1639 BFS_MMB_store 0;
BA_ "GenSigSendType" SG_ 1639 BFS_MMB_store_LED_on 3;
BA_ "GenSigSwitchedByIgnition" SG_ 1639 BFS_MMB_store_LED_on 0;
BA_ "GenSigSendType" SG_ 1639 BFS_MMB_tast 3;
BA_ "GenSigSwitchedByIgnition" SG_ 1639 BFS_MMB_tast 0;
BA_ "GenSigSendType" SG_ 1639 BFS_MMB_tipp 3;
BA_ "GenSigSwitchedByIgnition" SG_ 1639 BFS_MMB_tipp 0;
BA_ "GenSigSendType" SG_ 1639 BFS_NFA_einfahren 3;
BA_ "GenSigSwitchedByIgnition" SG_ 1639 BFS_NFA_einfahren 0;
BA_ "GenSigSendType" SG_ 1639 BFS_Ruhestellung_Status 3;
BA_ "GenSigSwitchedByIgnition" SG_ 1639 BFS_Ruhestellung_Status 0;
BA_ "GenSigSendType" SG_ 1639 BFS_Seat_Locked 0;
BA_ "GenSigSwitchedByIgnition" SG_ 1639 BFS_Seat_Locked 0;
BA_ "GenSigSendType" SG_ 1639 BFS_SHV_aktiv 3;
BA_ "GenSigSwitchedByIgnition" SG_ 1639 BFS_SHV_aktiv 0;
BA_ "GenSigSendType" SG_ 1639 BFS_Sitzfahrt_aktiv 3;
BA_ "GenSigSwitchedByIgnition" SG_ 1639 BFS_Sitzfahrt_aktiv 0;
BA_ "GenSigSendType" SG_ 1639 BFS_Sitzsym_Fahrt_aktiv 3;
BA_ "GenSigSwitchedByIgnition" SG_ 1639 BFS_Sitzsym_Fahrt_aktiv 0;
BA_ "GenSigSendType" SG_ 1639 BFS_SLV_aktiv 3;
BA_ "GenSigSwitchedByIgnition" SG_ 1639 BFS_SLV_aktiv 0;
BA_ "GenSigSendType" SG_ 1639 BFS_SNV_aktiv 3;
BA_ "GenSigSwitchedByIgnition" SG_ 1639 BFS_SNV_aktiv 0;
BA_ "GenSigSendType" SG_ 1639 BFS_STV_aktiv 3;
BA_ "GenSigSwitchedByIgnition" SG_ 1639 BFS_STV_aktiv 0;
BA_REL_ "GenSigTimeoutTime" BU_SG_REL_ BedienDisp_vo SG_ 1719 KBI_Standzeit_02 5000;
BA_REL_ "GenSigTimeoutTime" BU_SG_REL_ BedienDisp_vo SG_ 1719 KBI_QBit_Aussen_Temp_gef 5000;
BA_REL_ "GenSigTimeoutTime" BU_SG_REL_ BedienDisp_vo SG_ 1719 KBI_Aussen_Temp_gef 5000;
BA_REL_ "GenSigTimeoutTime" BU_SG_REL_ BedienDisp_vo SG_ 2527679638 KBI_Status_StoppUhr 5000;
BA_REL_ "GenSigTimeoutTime" BU_SG_REL_ BedienDisp_vo SG_ 2527679638 KBI_GZeit_HSek 5000;
BA_REL_ "GenSigTimeoutTime" BU_SG_REL_ BedienDisp_vo SG_ 2527679638 KBI_GZeit_Min 5000;
BA_REL_ "GenSigTimeoutTime" BU_SG_REL_ BedienDisp_vo SG_ 2527679638 KBI_GZeit_Std 5000;
BA_REL_ "GenSigTimeoutTime" BU_SG_REL_ BedienDisp_vo SG_ 2527679638 KBI_GZeit_Sek 5000;
BA_REL_ "GenSigTimeoutTime" BU_SG_REL_ BedienDisp_vo SG_ 1321 Lift_LED 2000;
BA_REL_ "GenSigTimeoutTime" BU_SG_REL_ BedienDisp_vo SG_ 1153 MMI_Gauges_active 5000;
BA_REL_ "GenSigTimeoutTime" BU_SG_REL_ BedienSG_hi SG_ 1719 KBI_Standzeit_02 5000;
BA_REL_ "GenSigTimeoutTime" BU_SG_REL_ BedienSG_hi SG_ 1719 KBI_QBit_Aussen_Temp_gef 5000;
BA_REL_ "GenSigTimeoutTime" BU_SG_REL_ BedienSG_hi SG_ 1719 KBI_Aussen_Temp_gef 5000;
BA_REL_ "GenSigTimeoutTime" BU_SG_REL_ BedienSG_hi SG_ 1720 KBI_Variante_USA 5000;
BA_REL_ "GenSigTimeoutTime" BU_SG_REL_ BedienSG_hi SG_ 1720 KBI_Variante 5000;
BA_REL_ "GenSigTimeoutTime" BU_SG_REL_ BedienSG_hi SG_ 1720 KBI_Tankfuellstand_Prozent 5000;
BA_REL_ "GenSigTimeoutTime" BU_SG_REL_ BedienSG_hi SG_ 1624 LV_Tagfahrlicht_Anzeige 5000;
BA_REL_ "GenSigTimeoutTime" BU_SG_REL_ BedienSG_hi SG_ 1624 LV_AFL_aktiv_Anzeige 5000;
BA_REL_ "GenSigTimeoutTime" BU_SG_REL_ DDA SG_ 2527679653 MXB_LAPP_Freigabe 5000;
BA_REL_ "GenSigTimeoutTime" BU_SG_REL_ DDA SG_ 2527679653 MXB_LAPP_ZR_Sondermodus_Anf 5000;
BA_REL_ "GenSigTimeoutTime" BU_SG_REL_ DDA SG_ 2527679653 MXB_LAPP_Status_FL 5000;
BA_REL_ "GenSigTimeoutTime" BU_SG_REL_ DDA SG_ 2527679653 MXB_LAPP_Statuscode 5000;
BA_REL_ "GenSigTimeoutTime" BU_SG_REL_ DDA SG_ 1153 ZR_LAPP_Sondermodus_Status 5000;
BA_REL_ "GenSigTimeoutTime" BU_SG_REL_ DDA SG_ 1153 ZR_Parken_Sondermodus 5000;
BA_REL_ "GenSigTimeoutTime" BU_SG_REL_ Gateway SG_ 1153 MMI_Counter_Bedienevent 5000;
BA_REL_ "GenSigTimeoutTime" BU_SG_REL_ Gateway SG_ 1153 MMI_SDS_aktiv 5000;
BA_REL_ "GenSigTimeoutTime" BU_SG_REL_ Gateway SG_ 1153 MMI_Telefon_aktiv 5000;
BA_REL_ "GenSigTimeoutTime" BU_SG_REL_ Gateway SG_ 1153 MU_Update_Time 5000;
BA_REL_ "GenSigTimeoutTime" BU_SG_REL_ Gateway_PAG SG_ 1153 MMI_Counter_Bedienevent 5000;
BA_REL_ "GenSigTimeoutTime" BU_SG_REL_ Gateway_PAG SG_ 1153 MMI_SDS_aktiv 5000;
BA_REL_ "GenSigTimeoutTime" BU_SG_REL_ Gateway_PAG SG_ 1153 MMI_Telefon_aktiv 5000;
BA_REL_ "GenSigTimeoutTime" BU_SG_REL_ Gateway_PAG SG_ 1153 MU_Update_Time 5000;
BA_REL_ "GenSigTimeoutTime" BU_SG_REL_ GurtMikrofon SG_ 1153 MMI_Gurt_Mic_ref 5000;
BA_REL_ "GenSigTimeoutTime" BU_SG_REL_ OTA_FC SG_ 1719 KBI_Oelwechsel_durchgefuehrt 5000;
BA_REL_ "GenSigTimeoutTime" BU_SG_REL_ OTA_FC SG_ 1719 KBI_Aussen_Temp_gef 5000;
BA_REL_ "GenSigTimeoutTime" BU_SG_REL_ OTA_FC SG_ 981 BCM1_Abblendlicht_Anf 1000;
BA_REL_ "GenSigTimeoutTime" BU_SG_REL_ OTA_FC SG_ 982 BCM2_Bremsl_durch_ECD 1000;
BA_REL_ "GenSigTimeoutTime" BU_SG_REL_ OTA_FC SG_ 982 LH_Standlicht_H_aktiv 1000;
BA_REL_ "GenSigTimeoutTime" BU_SG_REL_ OTA_FC SG_ 982 LH_Parklicht_HL_aktiv 1000;
BA_REL_ "GenSigTimeoutTime" BU_SG_REL_ OTA_FC SG_ 982 LH_Parklicht_HR_aktiv 1000;
BA_REL_ "GenSigTimeoutTime" BU_SG_REL_ OTA_FC SG_ 982 LH_Bremslicht_H_aktiv 1000;
BA_REL_ "GenSigTimeoutTime" BU_SG_REL_ OTA_FC SG_ 982 LH_Nebelschluss_aktiv 1000;
BA_REL_ "GenSigTimeoutTime" BU_SG_REL_ OTA_FC SG_ 982 LH_Rueckfahrlicht_aktiv 1000;
BA_REL_ "GenSigTimeoutTime" BU_SG_REL_ OTA_FC SG_ 982 LH_Blinker_HL_akt 1000;
BA_REL_ "GenSigTimeoutTime" BU_SG_REL_ OTA_FC SG_ 982 LH_Blinker_HR_akt 1000;
BA_REL_ "GenSigTimeoutTime" BU_SG_REL_ OTA_FC SG_ 1624 LV_Standlicht_Anzeige 5000;
BA_REL_ "GenSigTimeoutTime" BU_SG_REL_ OTA_FC SG_ 1624 LV_Abblendlicht_Anzeige 5000;
BA_REL_ "GenSigTimeoutTime" BU_SG_REL_ OTA_FC SG_ 1624 LV_Fernlicht_Anzeige 5000;
BA_REL_ "GenSigTimeoutTime" BU_SG_REL_ OTA_FC SG_ 1624 LV_Nebellicht_Anzeige 5000;
BA_REL_ "GenSigTimeoutTime" BU_SG_REL_ OTA_FC SG_ 1624 LV_Nebelschlusslicht_Anzeige 5000;
BA_REL_ "GenSigTimeoutTime" BU_SG_REL_ OTA_FC SG_ 1624 LV_Tagfahrlicht_Anzeige 5000;
BA_REL_ "GenSigTimeoutTime" BU_SG_REL_ OTA_FC SG_ 1624 LV_AFL_aktiv_Anzeige 5000;
BA_REL_ "GenSigTimeoutTime" BU_SG_REL_ OTA_FC SG_ 1624 LV_FLA_aktiv_Anzeige 5000;
BA_REL_ "GenSigTimeoutTime" BU_SG_REL_ OTA_FC SG_ 1624 LV_FLA_Sensor_blockiert 5000;
BA_REL_ "GenSigTimeoutTime" BU_SG_REL_ OTA_FC SG_ 1624 BCM1_Linksverkehr 5000;
BA_REL_ "GenSigTimeoutTime" BU_SG_REL_ OTA_FC SG_ 1624 BCM1_Licht_Dunkelheit_aktiv 5000;
BA_REL_ "GenSigTimeoutTime" BU_SG_REL_ OTA_FC SG_ 1624 LV_Blinker_VL_aktiv 5000;
BA_REL_ "GenSigTimeoutTime" BU_SG_REL_ OTA_FC SG_ 1624 LV_Blinker_VR_aktiv 5000;
BA_REL_ "GenSigTimeoutTime" BU_SG_REL_ OTA_FC SG_ 1321 Lift_Position 2000;
BA_REL_ "GenSigTimeoutTime" BU_SG_REL_ OTA_FC SG_ 134 LWI_Lenkradwinkel 1000;
BA_REL_ "GenSigTimeoutTime" BU_SG_REL_ OTA_FC SG_ 134 LWI_VZ_Lenkradwinkel 1000;
BA_REL_ "GenSigTimeoutTime" BU_SG_REL_ OTA_FC SG_ 134 LWI_Lenkradw_Geschw 1000;
BA_REL_ "GenSigTimeoutTime" BU_SG_REL_ ZR_High SG_ 1719 KBI_Standzeit_02 5000;
BA_REL_ "GenSigTimeoutTime" BU_SG_REL_ ZR_High SG_ 1719 KBI_LVDS_Lock 5000;
BA_REL_ "GenSigTimeoutTime" BU_SG_REL_ ZR_High SG_ 1719 KBI_Reserve_Warnung_Sek 5000;
BA_REL_ "GenSigTimeoutTime" BU_SG_REL_ ZR_High SG_ 1719 KBI_FStatus_Tank 5000;
BA_REL_ "GenSigTimeoutTime" BU_SG_REL_ ZR_High SG_ 1719 KBI_aktive_Laengsfunktion 5000;
BA_REL_ "GenSigTimeoutTime" BU_SG_REL_ ZR_High SG_ 1719 KBI_Oelwechsel_durchgefuehrt 5000;
BA_REL_ "GenSigTimeoutTime" BU_SG_REL_ ZR_High SG_ 1719 KBI_QBit_Aussen_Temp_gef 5000;
BA_REL_ "GenSigTimeoutTime" BU_SG_REL_ ZR_High SG_ 1720 KBI_Reifenumfang 5000;
BA_REL_ "GenSigTimeoutTime" BU_SG_REL_ ZR_High SG_ 1720 KBI_Variante_USA 5000;
BA_REL_ "GenSigTimeoutTime" BU_SG_REL_ ZR_High SG_ 1720 KBI_Tankfuellstand_Prozent 5000;
BA_REL_ "GenSigTimeoutTime" BU_SG_REL_ ZR_High SG_ 1720 KBI_Nachtanken_erkannt 5000;
BA_REL_ "GenSigTimeoutTime" BU_SG_REL_ ZR_High SG_ 1720 KBI_Max_Tankinhalt 5000;
BA_REL_ "GenSigTimeoutTime" BU_SG_REL_ ZR_High SG_ 1724 KBI_Oil_dis_status 5000;
BA_REL_ "GenSigTimeoutTime" BU_SG_REL_ ZR_High SG_ 1724 KBI_Oil_dis_unit 5000;
BA_REL_ "GenSigTimeoutTime" BU_SG_REL_ ZR_High SG_ 1724 KBI_Oil_dis 5000;
BA_REL_ "GenSigTimeoutTime" BU_SG_REL_ ZR_High SG_ 1724 KBI_Oil_time_status 5000;
BA_REL_ "GenSigTimeoutTime" BU_SG_REL_ ZR_High SG_ 1724 KBI_Oil_time 5000;
BA_REL_ "GenSigTimeoutTime" BU_SG_REL_ ZR_High SG_ 1724 KBI_Insp_dis_status 5000;
BA_REL_ "GenSigTimeoutTime" BU_SG_REL_ ZR_High SG_ 1724 KBI_Insp_dis_unit 5000;
BA_REL_ "GenSigTimeoutTime" BU_SG_REL_ ZR_High SG_ 1724 KBI_Insp_dis 5000;
BA_REL_ "GenSigTimeoutTime" BU_SG_REL_ ZR_High SG_ 1724 KBI_Insp_time_status 5000;
BA_REL_ "GenSigTimeoutTime" BU_SG_REL_ ZR_High SG_ 1724 KBI_Insp_time 5000;
BA_REL_ "GenSigTimeoutTime" BU_SG_REL_ ZR_High SG_ 1724 KBI_Warnung_ID 5000;
BA_REL_ "GenSigTimeoutTime" BU_SG_REL_ ZR_High SG_ 2527679638 KBI_RZ_Nr 5000;
BA_REL_ "GenSigTimeoutTime" BU_SG_REL_ ZR_High SG_ 2527679638 KBI_Status_StoppUhr 5000;
BA_REL_ "GenSigTimeoutTime" BU_SG_REL_ ZR_High SG_ 2527679638 KBI_GZeit_HSek 5000;
BA_REL_ "GenSigTimeoutTime" BU_SG_REL_ ZR_High SG_ 2527679638 KBI_GZeit_Min 5000;
BA_REL_ "GenSigTimeoutTime" BU_SG_REL_ ZR_High SG_ 2527679638 KBI_GZeit_Std 5000;
BA_REL_ "GenSigTimeoutTime" BU_SG_REL_ ZR_High SG_ 2527679638 KBI_GZeit_Sek 5000;
BA_REL_ "GenSigTimeoutTime" BU_SG_REL_ ZR_High SG_ 2527679638 KBI_RZeit_HSek 5000;
BA_REL_ "GenSigTimeoutTime" BU_SG_REL_ ZR_High SG_ 2527679638 KBI_RZeit_Min 5000;
BA_REL_ "GenSigTimeoutTime" BU_SG_REL_ ZR_High SG_ 2527679638 KBI_RZeit_Sek 5000;
BA_REL_ "GenSigTimeoutTime" BU_SG_REL_ ZR_High SG_ 2527679638 KBI_RZeit_Std 5000;
BA_REL_ "GenSigTimeoutTime" BU_SG_REL_ ZR_High SG_ 2527679639 KBI_Weg_Zaehler_F 5000;
BA_REL_ "GenSigTimeoutTime" BU_SG_REL_ ZR_High SG_ 2527679639 KBI_Weg_Zaehler 5000;
BA_REL_ "GenSigTimeoutTime" BU_SG_REL_ ZR_High SG_ 2527679656 KBI_StartupAnimation 5000;
BA_REL_ "GenSigTimeoutTime" BU_SG_REL_ ZR_High SG_ 2527679653 MXB_LAPP_ZR_Sondermodus_Anf 5000;
BA_REL_ "GenSigTimeoutTime" BU_SG_REL_ ZR_High SG_ 981 BCM1_Kurvenlicht_links_Anf 1000;
BA_REL_ "GenSigTimeoutTime" BU_SG_REL_ ZR_High SG_ 981 BCM1_Kurvenlicht_rechts_Anf 1000;
BA_REL_ "GenSigTimeoutTime" BU_SG_REL_ ZR_High SG_ 981 BCM1_Standlicht_Anf 1000;
BA_REL_ "GenSigTimeoutTime" BU_SG_REL_ ZR_High SG_ 981 BCM1_Abblendlicht_Anf 1000;
BA_REL_ "GenSigTimeoutTime" BU_SG_REL_ ZR_High SG_ 981 BCM1_Fernlicht_Anf 1000;
BA_REL_ "GenSigTimeoutTime" BU_SG_REL_ ZR_High SG_ 981 BCM1_Nebellicht_Anf 1000;
BA_REL_ "GenSigTimeoutTime" BU_SG_REL_ ZR_High SG_ 981 BCM1_Parklicht_li_Anf 1000;
BA_REL_ "GenSigTimeoutTime" BU_SG_REL_ ZR_High SG_ 981 BCM1_Parklicht_re_Anf 1000;
BA_REL_ "GenSigTimeoutTime" BU_SG_REL_ ZR_High SG_ 981 BCM1_Nebelschluss_Ahg_Anf 1000;
BA_REL_ "GenSigTimeoutTime" BU_SG_REL_ ZR_High SG_ 981 BCM1_Nebelschluss_Fzg_Anf 1000;
BA_REL_ "GenSigTimeoutTime" BU_SG_REL_ ZR_High SG_ 981 BCM1_Schlusslicht_Anf 1000;
BA_REL_ "GenSigTimeoutTime" BU_SG_REL_ ZR_High SG_ 981 BCM_Rueckfahrlicht_Anf 1000;
BA_REL_ "GenSigTimeoutTime" BU_SG_REL_ ZR_High SG_ 981 BCM1_Umfeldleuchten_Anf 1000;
BA_REL_ "GenSigTimeoutTime" BU_SG_REL_ ZR_High SG_ 981 BCM1_Tagfahrlicht_Anf 1000;
BA_REL_ "GenSigTimeoutTime" BU_SG_REL_ ZR_High SG_ 981 BCM1_Regenlicht_Anf 1000;
BA_REL_ "GenSigTimeoutTime" BU_SG_REL_ ZR_High SG_ 981 BCM1_Autobahnlicht_Anf 1000;
BA_REL_ "GenSigTimeoutTime" BU_SG_REL_ ZR_High SG_ 981 BCM1_Touristen_Licht_Anf 1000;
BA_REL_ "GenSigTimeoutTime" BU_SG_REL_ ZR_High SG_ 981 BCM1_CH_aktiv 1000;
BA_REL_ "GenSigTimeoutTime" BU_SG_REL_ ZR_High SG_ 981 BCM1_LH_aktiv 1000;
BA_REL_ "GenSigTimeoutTime" BU_SG_REL_ ZR_High SG_ 981 BCM1_Gleitende_Leuchtw_Anf 1000;
BA_REL_ "GenSigTimeoutTime" BU_SG_REL_ ZR_High SG_ 981 BCM1_GLW_Fernlicht_Anf 1000;
BA_REL_ "GenSigTimeoutTime" BU_SG_REL_ ZR_High SG_ 981 BCM1_Adaptive_Lichtvert_Anf 1000;
BA_REL_ "GenSigTimeoutTime" BU_SG_REL_ ZR_High SG_ 981 BCM1_CH_LH_aktiv 1000;
BA_REL_ "GenSigTimeoutTime" BU_SG_REL_ ZR_High SG_ 981 BCM1_Allwetterlicht_Anf 1000;
BA_REL_ "GenSigTimeoutTime" BU_SG_REL_ ZR_High SG_ 982 BCM2_Bremsl_durch_ECD 1000;
BA_REL_ "GenSigTimeoutTime" BU_SG_REL_ ZR_High SG_ 982 LH_Aussenlicht_def 1000;
BA_REL_ "GenSigTimeoutTime" BU_SG_REL_ ZR_High SG_ 982 LH_Standlicht_H_aktiv 1000;
BA_REL_ "GenSigTimeoutTime" BU_SG_REL_ ZR_High SG_ 982 LH_Parklicht_HL_aktiv 1000;
BA_REL_ "GenSigTimeoutTime" BU_SG_REL_ ZR_High SG_ 982 LH_Parklicht_HR_aktiv 1000;
BA_REL_ "GenSigTimeoutTime" BU_SG_REL_ ZR_High SG_ 982 LH_Bremslicht_H_aktiv 1000;
BA_REL_ "GenSigTimeoutTime" BU_SG_REL_ ZR_High SG_ 982 LH_Nebelschluss_aktiv 1000;
BA_REL_ "GenSigTimeoutTime" BU_SG_REL_ ZR_High SG_ 982 LH_Rueckfahrlicht_aktiv 1000;
BA_REL_ "GenSigTimeoutTime" BU_SG_REL_ ZR_High SG_ 982 LH_Blinker_HL_akt 1000;
BA_REL_ "GenSigTimeoutTime" BU_SG_REL_ ZR_High SG_ 982 LH_Blinker_HR_akt 1000;
BA_REL_ "GenSigTimeoutTime" BU_SG_REL_ ZR_High SG_ 982 LH_Blinker_li_def 1000;
BA_REL_ "GenSigTimeoutTime" BU_SG_REL_ ZR_High SG_ 982 LH_Bremsl_li_def 1000;
BA_REL_ "GenSigTimeoutTime" BU_SG_REL_ ZR_High SG_ 982 LH_Schlusslicht_li_def 1000;
BA_REL_ "GenSigTimeoutTime" BU_SG_REL_ ZR_High SG_ 982 LH_Rueckf_li_def 1000;
BA_REL_ "GenSigTimeoutTime" BU_SG_REL_ ZR_High SG_ 982 LH_Nebel_li_def 1000;
BA_REL_ "GenSigTimeoutTime" BU_SG_REL_ ZR_High SG_ 982 LH_Schluss_Brems_Nebel_li_def 1000;
BA_REL_ "GenSigTimeoutTime" BU_SG_REL_ ZR_High SG_ 982 LH_Schluss_Brems_Nebel_re_def 1000;
BA_REL_ "GenSigTimeoutTime" BU_SG_REL_ ZR_High SG_ 982 LH_Schluss_Brems_li_def 1000;
BA_REL_ "GenSigTimeoutTime" BU_SG_REL_ ZR_High SG_ 982 LH_Schluss_Nebel_li_def 1000;
BA_REL_ "GenSigTimeoutTime" BU_SG_REL_ ZR_High SG_ 982 LH_SL_BRL_BLK_li_def 1000;
BA_REL_ "GenSigTimeoutTime" BU_SG_REL_ ZR_High SG_ 982 LH_Diag_Status_re_def 1000;
BA_REL_ "GenSigTimeoutTime" BU_SG_REL_ ZR_High SG_ 982 LH_Diag_Status_li_def 1000;
BA_REL_ "GenSigTimeoutTime" BU_SG_REL_ ZR_High SG_ 982 LH_Diag_LED_li_def 1000;
BA_REL_ "GenSigTimeoutTime" BU_SG_REL_ ZR_High SG_ 982 LH_Diag_LED_re_def 1000;
BA_REL_ "GenSigTimeoutTime" BU_SG_REL_ ZR_High SG_ 982 LH_Blinker_re_def 1000;
BA_REL_ "GenSigTimeoutTime" BU_SG_REL_ ZR_High SG_ 982 LH_Bremsl_re_def 1000;
BA_REL_ "GenSigTimeoutTime" BU_SG_REL_ ZR_High SG_ 982 LH_Schlusslicht_re_def 1000;
BA_REL_ "GenSigTimeoutTime" BU_SG_REL_ ZR_High SG_ 982 LH_Rueckf_re_def 1000;
BA_REL_ "GenSigTimeoutTime" BU_SG_REL_ ZR_High SG_ 982 LH_Nebel_re_def 1000;
BA_REL_ "GenSigTimeoutTime" BU_SG_REL_ ZR_High SG_ 982 LH_Schluss_Brems_re_def 1000;
BA_REL_ "GenSigTimeoutTime" BU_SG_REL_ ZR_High SG_ 982 LH_Schluss_Nebel_re_def 1000;
BA_REL_ "GenSigTimeoutTime" BU_SG_REL_ ZR_High SG_ 982 LH_SL_BRL_BLK_re_def 1000;
BA_REL_ "GenSigTimeoutTime" BU_SG_REL_ ZR_High SG_ 982 LH_Brems_Blk_re_def 1000;
BA_REL_ "GenSigTimeoutTime" BU_SG_REL_ ZR_High SG_ 982 LH_Kennzl_def 1000;
BA_REL_ "GenSigTimeoutTime" BU_SG_REL_ ZR_High SG_ 982 LH_3_Bremsl_def 1000;
BA_REL_ "GenSigTimeoutTime" BU_SG_REL_ ZR_High SG_ 982 LH_Nebel_mi_def 1000;
BA_REL_ "GenSigTimeoutTime" BU_SG_REL_ ZR_High SG_ 982 LH_Rueckf_mi_def 1000;
BA_REL_ "GenSigTimeoutTime" BU_SG_REL_ ZR_High SG_ 982 LH_Bremsl_li_ges_def 1000;
BA_REL_ "GenSigTimeoutTime" BU_SG_REL_ ZR_High SG_ 982 LH_Bremsl_re_ges_def 1000;
BA_REL_ "GenSigTimeoutTime" BU_SG_REL_ ZR_High SG_ 1624 LV_Standlicht_Anzeige 5000;
BA_REL_ "GenSigTimeoutTime" BU_SG_REL_ ZR_High SG_ 1624 LV_Abblendlicht_Anzeige 5000;
BA_REL_ "GenSigTimeoutTime" BU_SG_REL_ ZR_High SG_ 1624 LV_Fernlicht_Anzeige 5000;
BA_REL_ "GenSigTimeoutTime" BU_SG_REL_ ZR_High SG_ 1624 LV_Nebellicht_Anzeige 5000;
BA_REL_ "GenSigTimeoutTime" BU_SG_REL_ ZR_High SG_ 1624 LV_Nebelschlusslicht_Anzeige 5000;
BA_REL_ "GenSigTimeoutTime" BU_SG_REL_ ZR_High SG_ 1624 LV_Tagfahrlicht_Anzeige 5000;
BA_REL_ "GenSigTimeoutTime" BU_SG_REL_ ZR_High SG_ 1624 LV_AFL_aktiv_Anzeige 5000;
BA_REL_ "GenSigTimeoutTime" BU_SG_REL_ ZR_High SG_ 1624 LV_AFL_defekt 5000;
BA_REL_ "GenSigTimeoutTime" BU_SG_REL_ ZR_High SG_ 1624 LV_Blinker_li_def 5000;
BA_REL_ "GenSigTimeoutTime" BU_SG_REL_ ZR_High SG_ 1624 LV_Standlicht_li_def 5000;
BA_REL_ "GenSigTimeoutTime" BU_SG_REL_ ZR_High SG_ 1624 LV_Abblendlicht_li_def 5000;
BA_REL_ "GenSigTimeoutTime" BU_SG_REL_ ZR_High SG_ 1624 LV_Fernlicht_li_def 5000;
BA_REL_ "GenSigTimeoutTime" BU_SG_REL_ ZR_High SG_ 1624 LV_Nebellicht_li_def 5000;
BA_REL_ "GenSigTimeoutTime" BU_SG_REL_ ZR_High SG_ 1624 LV_Blk_li_Seite_def 5000;
BA_REL_ "GenSigTimeoutTime" BU_SG_REL_ ZR_High SG_ 1624 LV_Tagfahrlicht_li_def 5000;
BA_REL_ "GenSigTimeoutTime" BU_SG_REL_ ZR_High SG_ 1624 LV_FLA_aktiv_Anzeige 5000;
BA_REL_ "GenSigTimeoutTime" BU_SG_REL_ ZR_High SG_ 1624 LV_FLA_defekt 5000;
BA_REL_ "GenSigTimeoutTime" BU_SG_REL_ ZR_High SG_ 1624 LV_FLA_Sensor_blockiert 5000;
BA_REL_ "GenSigTimeoutTime" BU_SG_REL_ ZR_High SG_ 1624 LV_Blinker_re_def 5000;
BA_REL_ "GenSigTimeoutTime" BU_SG_REL_ ZR_High SG_ 1624 LV_Standlicht_re_def 5000;
BA_REL_ "GenSigTimeoutTime" BU_SG_REL_ ZR_High SG_ 1624 LV_Abblendlicht_re_def 5000;
BA_REL_ "GenSigTimeoutTime" BU_SG_REL_ ZR_High SG_ 1624 LV_Fernlicht_re_def 5000;
BA_REL_ "GenSigTimeoutTime" BU_SG_REL_ ZR_High SG_ 1624 LV_Nebellicht_re_def 5000;
BA_REL_ "GenSigTimeoutTime" BU_SG_REL_ ZR_High SG_ 1624 LV_Blk_re_Seite_def 5000;
BA_REL_ "GenSigTimeoutTime" BU_SG_REL_ ZR_High SG_ 1624 LV_Tagfahrlicht_re_def 5000;
BA_REL_ "GenSigTimeoutTime" BU_SG_REL_ ZR_High SG_ 1624 LV_Aussenlicht_def 5000;
BA_REL_ "GenSigTimeoutTime" BU_SG_REL_ ZR_High SG_ 1624 LV_Abblendlicht_TFL_li_def 5000;
BA_REL_ "GenSigTimeoutTime" BU_SG_REL_ ZR_High SG_ 1624 LV_Nebellicht_TFL_li_def 5000;
BA_REL_ "GenSigTimeoutTime" BU_SG_REL_ ZR_High SG_ 1624 LV_Standlicht_TFL_li_def 5000;
BA_REL_ "GenSigTimeoutTime" BU_SG_REL_ ZR_High SG_ 1624 LV_Abblend_Fernlicht_li_def 5000;
BA_REL_ "GenSigTimeoutTime" BU_SG_REL_ ZR_High SG_ 1624 LV_Abblendlicht_TFL_re_def 5000;
BA_REL_ "GenSigTimeoutTime" BU_SG_REL_ ZR_High SG_ 1624 LV_Nebellicht_TFL_re_def 5000;
BA_REL_ "GenSigTimeoutTime" BU_SG_REL_ ZR_High SG_ 1624 LV_Standlicht_TFL_re_def 5000;
BA_REL_ "GenSigTimeoutTime" BU_SG_REL_ ZR_High SG_ 1624 LV_Abblend_Fernlicht_re_def 5000;
BA_REL_ "GenSigTimeoutTime" BU_SG_REL_ ZR_High SG_ 1624 BCM1_Linksverkehr 5000;
BA_REL_ "GenSigTimeoutTime" BU_SG_REL_ ZR_High SG_ 1624 BCM1_Licht_Dunkelheit_aktiv 5000;
BA_REL_ "GenSigTimeoutTime" BU_SG_REL_ ZR_High SG_ 1624 LV_Blinker_VL_aktiv 5000;
BA_REL_ "GenSigTimeoutTime" BU_SG_REL_ ZR_High SG_ 1624 LV_Blinker_VR_aktiv 5000;
BA_REL_ "GenSigTimeoutTime" BU_SG_REL_ ZR_High SG_ 822 LR_HZG_Temp_Sensor 1200;
BA_REL_ "GenSigTimeoutTime" BU_SG_REL_ ZR_High SG_ 822 LR_HZG_Taster_on_off 1200;
BA_REL_ "GenSigTimeoutTime" BU_SG_REL_ ZR_High SG_ 134 LWI_Sensorstatus 1000;
BA_REL_ "GenSigTimeoutTime" BU_SG_REL_ ZR_High SG_ 134 LWI_QBit_Sub_Daten 1000;
BA_REL_ "GenSigTimeoutTime" BU_SG_REL_ ZR_High SG_ 134 LWI_MFL_Abschaltung 1000;
BA_REL_ "GenSigTimeoutTime" BU_SG_REL_ ZR_High SG_ 134 LWI_QBit_Lenkradwinkel 1000;
BA_REL_ "GenSigTimeoutTime" BU_SG_REL_ ZR_High SG_ 134 LWI_Lenkradwinkel 1000;
BA_REL_ "GenSigTimeoutTime" BU_SG_REL_ ZR_High SG_ 134 LWI_VZ_Lenkradwinkel 1000;
BA_REL_ "GenSigTimeoutTime" BU_SG_REL_ ZR_High SG_ 134 LWI_VZ_Lenkradw_Geschw 1000;
BA_REL_ "GenSigTimeoutTime" BU_SG_REL_ ZR_High SG_ 134 LWI_Lenkradw_Geschw 1000;
BA_REL_ "GenSigTimeoutTime" BU_SG_REL_ ZR_High SG_ 917 AFS_Abbiegelicht_li_Anf 1000;
BA_REL_ "GenSigTimeoutTime" BU_SG_REL_ ZR_High SG_ 917 AFS_Abbiegelicht_re_Anf 1000;
BA_REL_ "GenSigTimeoutTime" BU_SG_REL_ ZR_High SG_ 917 AFS_Abbiegelicht_Dimm_Anf 1000;
BA_REL_ "GenSigTimeoutTime" BU_SG_REL_ ZR_High SG_ 917 AFS_Verfuegbarkeit_GLW 1000;
BA_REL_ "GenSigTimeoutTime" BU_SG_REL_ ZR_High SG_ 917 AFS_Status_adaptive_LV 1000;
BA_REL_ "GenSigTimeoutTime" BU_SG_REL_ ZR_High SG_ 917 AFS_Fernlicht_li_defekt 1000;
BA_REL_ "GenSigTimeoutTime" BU_SG_REL_ ZR_High SG_ 917 AFS_Fernlicht_re_defekt 1000;
BA_REL_ "GenSigTimeoutTime" BU_SG_REL_ ZR_High SG_ 917 AFS_Fernlicht_Status 1000;
BA_REL_ "GenSigTimeoutTime" BU_SG_REL_ ZR_High SG_ 917 AFS_Lampe 1000;
BA_REL_ "GenSigTimeoutTime" BU_SG_REL_ ZR_High SG_ 917 LWR_Lampe 1000;
BA_REL_ "GenSigTimeoutTime" BU_SG_REL_ ZR_High SG_ 917 AFS_Fehlertext 1000;
BA_REL_ "GenSigTimeoutTime" BU_SG_REL_ ZR_High SG_ 917 LWR_Touristenmodus_aktiv 1000;
BA_REL_ "GenSigTimeoutTime" BU_SG_REL_ ZR_High SG_ 917 LWR_Sicherheitsposition_re 1000;
BA_REL_ "GenSigTimeoutTime" BU_SG_REL_ ZR_High SG_ 917 AFS_Allwetterlicht 1000;
BA_REL_ "GenSigTimeoutTime" BU_SG_REL_ ZR_High SG_ 917 LWR_Touristenmodus_verbaut 1000;
BA_REL_ "GenSigTimeoutTime" BU_SG_REL_ ZR_High SG_ 917 AFS_adaptive_LV_verbaut 1000;
BA_REL_ "GenSigTimeoutTime" BU_SG_REL_ ZR_High SG_ 917 LWR_Reisemodus_Texte 1000;
BA_REL_ "GenSigTimeoutTime" BU_SG_REL_ ZR_High SG_ 917 GLW_Sensor_blockiert 1000;
BA_REL_ "GenSigTimeoutTime" BU_SG_REL_ ZR_High SG_ 917 LWR_Hoehenwert_VL 1000;
BA_REL_ "GenSigTimeoutTime" BU_SG_REL_ ZR_High SG_ 917 LWR_Hoehenwert_HL 1000;
BA_REL_ "GenSigTimeoutTime" BU_SG_REL_ ZR_High SG_ 917 AFS_Ersatzlicht_Links 1000;
BA_REL_ "GenSigTimeoutTime" BU_SG_REL_ ZR_High SG_ 917 AFS_Ersatzlicht_Rechts 1000;
BA_REL_ "GenSigTimeoutTime" BU_SG_REL_ ZR_High SG_ 917 LWR_AFS_Grundeinstellung 1000;
BA_REL_ "GenSigTimeoutTime" BU_SG_REL_ ZR_High SG_ 917 LWR_AFS_Parametrisierung 1000;
BA_REL_ "GenSigTimeoutTime" BU_SG_REL_ ZR_High SG_ 917 LWR_Initialisierungslauf 1000;
BA_REL_ "GenSigTimeoutTime" BU_SG_REL_ ZR_High SG_ 917 LWR_Sicherheitsposition_li 1000;
BA_REL_ "GenSigTimeoutTime" BU_SG_REL_ ZR_High SG_ 917 LWR_Modus 1000;
BA_REL_ "GenSigTimeoutTime" BU_SG_REL_ ZR_High SG_ 1639 BFS_Fond_Bed_Ack 1000;
BA_REL_ "GenSigTimeoutTime" BU_SG_REL_ ZR_High SG_ 1639 BFS_Klapptisch_offen 1000;
BA_REL_ "GenSigTimeoutTime" BU_SG_REL_ ZR_High SG_ 1639 BFS_Gurtbringer_Sperre 1000;
BA_REL_ "GenSigTimeoutTime" BU_SG_REL_ ZR_High SG_ 1639 BFS_Sitzsym_Fahrt_aktiv 1000;
BA_REL_ "GenSigTimeoutTime" BU_SG_REL_ ZR_High SG_ 1639 BFS_Sitzfahrt_aktiv 1000;
BA_REL_ "GenSigTimeoutTime" BU_SG_REL_ ZR_High SG_ 1639 BFS_SLV_aktiv 1000;
BA_REL_ "GenSigTimeoutTime" BU_SG_REL_ ZR_High SG_ 1639 BFS_SHV_aktiv 1000;
BA_REL_ "GenSigTimeoutTime" BU_SG_REL_ ZR_High SG_ 1639 BFS_LNV_aktiv 1000;
BA_REL_ "GenSigTimeoutTime" BU_SG_REL_ ZR_High SG_ 1639 BFS_SNV_aktiv 1000;
BA_REL_ "GenSigTimeoutTime" BU_SG_REL_ ZR_High SG_ 1639 BFS_KSV_aktiv 1000;
BA_REL_ "GenSigTimeoutTime" BU_SG_REL_ ZR_High SG_ 1639 BFS_LKV_aktiv 1000;
BA_REL_ "GenSigTimeoutTime" BU_SG_REL_ ZR_High SG_ 1639 BFS_STV_aktiv 1000;
BA_REL_ "GenSigTimeoutTime" BU_SG_REL_ ZR_High SG_ 1639 BFS_LHV_aktiv 1000;
BA_REL_ "GenSigTimeoutTime" BU_SG_REL_ ZR_High SG_ 1639 BFS_LWV_aktiv 1000;
BA_REL_ "GenSigTimeoutTime" BU_SG_REL_ ZR_High SG_ 1639 BFS_GHV_aktiv 1000;
BA_REL_ "GenSigTimeoutTime" BU_SG_REL_ ZR_High SG_ 1639 BFS_KSS_Fahrt_aktiv 1000;
BA_REL_ "GenSigTimeoutTime" BU_SG_REL_ ZR_High SG_ 1639 BFS_MMB_lokal_Stop 1000;
BA_REL_ "GenSigTimeoutTime" BU_SG_REL_ ZR_High SG_ 1639 BFS_Ruhestellung_Status 1000;
BA_REL_ "GenSigTimeoutTime" BU_SG_REL_ ZR_High SG_ 1639 BFS_Seat_Locked 1000;
BA_REL_ "GenSigTimeoutTime" BU_SG_REL_ ZR_High SG_ 1639 BFS_MMB_storage 1000;
BA_REL_ "GenSigTimeoutTime" BU_SG_REL_ ZR_High SG_ 1639 BFS_MMB_tipp 1000;
BA_REL_ "GenSigTimeoutTime" BU_SG_REL_ ZR_High SG_ 1639 BFS_MMB_tast 1000;
BA_REL_ "GenSigTimeoutTime" BU_SG_REL_ ZR_High SG_ 1639 BFS_MMB_store_LED_on 1000;
BA_REL_ "GenSigTimeoutTime" BU_SG_REL_ ZR_High SG_ 1639 BFS_MMB_storage_beep 1000;
BA_REL_ "GenSigTimeoutTime" BU_SG_REL_ ZR_High SG_ 1639 BFS_MMB_store 1000;
BA_REL_ "GenSigTimeoutTime" BU_SG_REL_ ZR_High SG_ 1639 BFS_MMB_glob_stop 1000;
BA_REL_ "GenSigTimeoutTime" BU_SG_REL_ ZR_High SG_ 1639 BFS_FSV_ausgeklappt 1000;
BA_REL_ "GenSigTimeoutTime" BU_SG_REL_ ZR_LIMU SG_ 1719 KBI_Reserve_Warnung_Sek 5000;
BA_REL_ "GenSigTimeoutTime" BU_SG_REL_ ZR_LIMU SG_ 1719 KBI_FStatus_Tank 5000;
BA_REL_ "GenSigTimeoutTime" BU_SG_REL_ ZR_LIMU SG_ 2527679638 KBI_RZ_Nr 5000;
BA_REL_ "GenSigTimeoutTime" BU_SG_REL_ ZR_LIMU SG_ 2527679638 KBI_Status_StoppUhr 5000;
BA_REL_ "GenSigTimeoutTime" BU_SG_REL_ ZR_LIMU SG_ 2527679638 KBI_GZeit_HSek 5000;
BA_REL_ "GenSigTimeoutTime" BU_SG_REL_ ZR_LIMU SG_ 2527679638 KBI_GZeit_Min 5000;
BA_REL_ "GenSigTimeoutTime" BU_SG_REL_ ZR_LIMU SG_ 2527679638 KBI_GZeit_Std 5000;
BA_REL_ "GenSigTimeoutTime" BU_SG_REL_ ZR_LIMU SG_ 2527679638 KBI_GZeit_Sek 5000;
BA_REL_ "GenSigTimeoutTime" BU_SG_REL_ ZR_LIMU SG_ 2527679638 KBI_RZeit_HSek 5000;
BA_REL_ "GenSigTimeoutTime" BU_SG_REL_ ZR_LIMU SG_ 2527679638 KBI_RZeit_Min 5000;
BA_REL_ "GenSigTimeoutTime" BU_SG_REL_ ZR_LIMU SG_ 2527679638 KBI_RZeit_Sek 5000;
BA_REL_ "GenSigTimeoutTime" BU_SG_REL_ ZR_LIMU SG_ 2527679638 KBI_RZeit_Std 5000;
BA_REL_ "GenSigTimeoutTime" BU_SG_REL_ ZR_LIMU SG_ 2527679639 KBI_Weg_Zaehler_F 5000;
BA_REL_ "GenSigTimeoutTime" BU_SG_REL_ ZR_LIMU SG_ 2527679639 KBI_Weg_Zaehler 5000;
BA_REL_ "GenSigTimeoutTime" BU_SG_REL_ ZR_LIMU SG_ 2527679639 KBI_Jokerkey 5000;
BA_REL_ "GenSigTimeoutTime" BU_SG_REL_ ZR_LIMU SG_ 701 LAE_BetaSlipAngle_02 500;
BA_REL_ "GenSigTimeoutTime" BU_SG_REL_ ZR_LIMU SG_ 701 LAE_Vx_VZ 500;
BA_REL_ "GenSigTimeoutTime" BU_SG_REL_ ZR_LIMU SG_ 701 LAE_mu_confidence 500;
BA_REL_ "GenSigTimeoutTime" BU_SG_REL_ ZR_LIMU SG_ 701 LAE_mu 500;
BA_REL_ "GenSigTimeoutTime" BU_SG_REL_ ZR_LIMU SG_ 701 LAE_Vy 500;
BA_REL_ "GenSigTimeoutTime" BU_SG_REL_ ZR_LIMU SG_ 701 LAE_Vy_confidence 500;
BA_REL_ "GenSigTimeoutTime" BU_SG_REL_ ZR_LIMU SG_ 701 LAE_BetaSlipAngle 500;
BA_REL_ "GenSigTimeoutTime" BU_SG_REL_ ZR_LIMU SG_ 701 LAE_Beta_VZ 500;
BA_REL_ "GenSigTimeoutTime" BU_SG_REL_ ZR_LIMU SG_ 701 LAE_Beta_confidence 500;
BA_REL_ "GenSigTimeoutTime" BU_SG_REL_ ZR_LIMU SG_ 701 LAE_Vx_confidence 500;
BA_REL_ "GenSigTimeoutTime" BU_SG_REL_ ZR_LIMU SG_ 701 LAE_Vx 500;
BA_REL_ "GenSigTimeoutTime" BU_SG_REL_ ZR_LIMU SG_ 2463978818 BTM_BrakeSystem_Status 3200;
BA_REL_ "GenSigTimeoutTime" BU_SG_REL_ ZR_LIMU SG_ 2463978818 BTM_BrakeSystem_Text 3200;
BA_REL_ "GenSigTimeoutTime" BU_SG_REL_ ZR_LIMU SG_ 2463978818 BTM_BrakeSystem_Warnlampe 3200;
BA_REL_ "GenSigTimeoutTime" BU_SG_REL_ ZR_LIMU SG_ 2463978818 LCV_Lift_Status 3200;
BA_REL_ "GenSigTimeoutTime" BU_SG_REL_ ZR_LIMU SG_ 2463978818 LCV_HD_offen 3200;
BA_REL_ "GenSigTimeoutTime" BU_SG_REL_ ZR_LIMU SG_ 2527679780 LCV_Aero_BarMode_Activation 5000;
BA_REL_ "GenSigTimeoutTime" BU_SG_REL_ ZR_LIMU SG_ 2527679780 LCV_Aero_Button_Default 5000;
BA_REL_ "GenSigTimeoutTime" BU_SG_REL_ ZR_LIMU SG_ 2527679780 LCV_Aero_Button_Range 5000;
BA_REL_ "GenSigTimeoutTime" BU_SG_REL_ ZR_LIMU SG_ 2527679780 LCV_Aero_Button_Select 5000;
BA_REL_ "GenSigTimeoutTime" BU_SG_REL_ ZR_LIMU SG_ 2527679780 LCV_Aero_Button_Tunable 5000;
BA_REL_ "GenSigTimeoutTime" BU_SG_REL_ ZR_LIMU SG_ 2527679780 LCV_DR_Button_Default 5000;
BA_REL_ "GenSigTimeoutTime" BU_SG_REL_ ZR_LIMU SG_ 2527679780 LCV_DR_Button_Range 5000;
BA_REL_ "GenSigTimeoutTime" BU_SG_REL_ ZR_LIMU SG_ 2527679780 LCV_DR_Button_Select 5000;
BA_REL_ "GenSigTimeoutTime" BU_SG_REL_ ZR_LIMU SG_ 2527679780 LCV_DR_Button_Tunable 5000;
BA_REL_ "GenSigTimeoutTime" BU_SG_REL_ ZR_LIMU SG_ 2463978684 BTM_BrakeDiscTemp_01 1000;
BA_REL_ "GenSigTimeoutTime" BU_SG_REL_ ZR_LIMU SG_ 2463978684 BTM_BrakeDiscTemp_02 1000;
BA_REL_ "GenSigTimeoutTime" BU_SG_REL_ ZR_LIMU SG_ 2463978684 BTM_BrakeDiscTemp_03 1000;
BA_REL_ "GenSigTimeoutTime" BU_SG_REL_ ZR_LIMU SG_ 2463978684 BTM_BrakeDiscTemp_04 1000;
BA_REL_ "GenSigTimeoutTime" BU_SG_REL_ ZR_LIMU SG_ 2463978684 BTM_BrakeFluidTemp_01 1000;
BA_REL_ "GenSigTimeoutTime" BU_SG_REL_ ZR_LIMU SG_ 2463978684 BTM_BrakeFluidTemp_02 1000;
BA_REL_ "GenSigTimeoutTime" BU_SG_REL_ ZR_LIMU SG_ 2463978684 BTM_BrakeFluidTemp_03 1000;
BA_REL_ "GenSigTimeoutTime" BU_SG_REL_ ZR_LIMU SG_ 2463978684 BTM_BrakeFluidTemp_04 1000;
BA_REL_ "GenSigTimeoutTime" BU_SG_REL_ ZR_LIMU SG_ 548 LCV_Aero_Front_Ratio 500;
BA_REL_ "GenSigTimeoutTime" BU_SG_REL_ ZR_LIMU SG_ 548 LCV_Aero_Long_Ratio 500;
BA_REL_ "GenSigTimeoutTime" BU_SG_REL_ ZR_LIMU SG_ 2589283974 BTM_BrakeDiscColour_01 5000;
BA_REL_ "GenSigTimeoutTime" BU_SG_REL_ ZR_LIMU SG_ 2589283974 BTM_BrakeDiscColour_02 5000;
BA_REL_ "GenSigTimeoutTime" BU_SG_REL_ ZR_LIMU SG_ 2589283974 BTM_BrakeDiscColour_03 5000;
BA_REL_ "GenSigTimeoutTime" BU_SG_REL_ ZR_LIMU SG_ 2589283974 BTM_BrakeDiscColour_04 5000;
BA_REL_ "GenSigTimeoutTime" BU_SG_REL_ ZR_LIMU SG_ 2589283974 BTM_BrakeFluidColour_01 5000;
BA_REL_ "GenSigTimeoutTime" BU_SG_REL_ ZR_LIMU SG_ 2589283974 BTM_BrakeFluidColour_02 5000;
BA_REL_ "GenSigTimeoutTime" BU_SG_REL_ ZR_LIMU SG_ 2589283974 BTM_BrakeFluidColour_03 5000;
BA_REL_ "GenSigTimeoutTime" BU_SG_REL_ ZR_LIMU SG_ 2589283974 BTM_BrakeFluidColour_04 5000;
BA_REL_ "GenSigTimeoutTime" BU_SG_REL_ ZR_LIMU SG_ 2527679774 LRM_General_Error 5000;
BA_REL_ "GenSigTimeoutTime" BU_SG_REL_ ZR_LIMU SG_ 2527679774 LRM_Auto_Error 5000;
BA_REL_ "GenSigTimeoutTime" BU_SG_REL_ ZR_LIMU SG_ 2527679774 LRM_Manual_Error 5000;
BA_REL_ "GenSigTimeoutTime" BU_SG_REL_ ZR_LIMU SG_ 2527679774 LRM_Glass_OC_Error 5000;
BA_REL_ "GenSigTimeoutTime" BU_SG_REL_ ZR_LIMU SG_ 2527679774 LRM_Glass_SC_Error 5000;
BA_REL_ "GenSigTimeoutTime" BU_SG_REL_ ZR_LIMU SG_ 2527679774 LRM_Glass_Rear_OC_Error 5000;
BA_REL_ "GenSigTimeoutTime" BU_SG_REL_ ZR_LIMU SG_ 2527679774 LRM_Glass_Rear_SC_Error 5000;
BA_REL_ "GenSigTimeoutTime" BU_SG_REL_ ZR_LIMU SG_ 2527679774 LRM_Level 5000;
BA_REL_ "GenSigTimeoutTime" BU_SG_REL_ ZR_LIMU SG_ 2527679774 LRM_Level_Rear 5000;
BA_REL_ "GenSigTimeoutTime" BU_SG_REL_ ZR_LIMU SG_ 2527679774 LRM_Mode 5000;
BA_REL_ "GenSigTimeoutTime" BU_SG_REL_ ZR_LIMU SG_ 134 LWI_Sensorstatus 1000;
BA_REL_ "GenSigTimeoutTime" BU_SG_REL_ ZR_LIMU SG_ 134 LWI_QBit_Lenkradwinkel 1000;
BA_REL_ "GenSigTimeoutTime" BU_SG_REL_ ZR_LIMU SG_ 134 LWI_Lenkradwinkel 1000;
BA_REL_ "GenSigTimeoutTime" BU_SG_REL_ ZR_LIMU SG_ 134 LWI_VZ_Lenkradwinkel 1000;
BA_REL_ "GenSigTimeoutTime" BU_SG_REL_ ZR_MIB_TOP_ab_Gen3 SG_ 1719 KBI_Reserve_Warnung_Sek 5000;
BA_REL_ "GenSigTimeoutTime" BU_SG_REL_ ZR_MIB_TOP_ab_Gen3 SG_ 1719 KBI_FStatus_Tank 5000;
BA_REL_ "GenSigTimeoutTime" BU_SG_REL_ ZR_MIB_TOP_ab_Gen3 SG_ 1720 KBI_Nachtanken_erkannt 5000;
BA_REL_ "GenSigTimeoutTime" BU_SG_REL_ ZR_MIB_TOP_ab_Gen3 SG_ 2527679638 KBI_RZ_Nr 5000;
BA_REL_ "GenSigTimeoutTime" BU_SG_REL_ ZR_MIB_TOP_ab_Gen3 SG_ 2527679638 KBI_Status_StoppUhr 5000;
BA_REL_ "GenSigTimeoutTime" BU_SG_REL_ ZR_MIB_TOP_ab_Gen3 SG_ 2527679638 KBI_GZeit_HSek 5000;
BA_REL_ "GenSigTimeoutTime" BU_SG_REL_ ZR_MIB_TOP_ab_Gen3 SG_ 2527679638 KBI_GZeit_Min 5000;
BA_REL_ "GenSigTimeoutTime" BU_SG_REL_ ZR_MIB_TOP_ab_Gen3 SG_ 2527679638 KBI_GZeit_Std 5000;
BA_REL_ "GenSigTimeoutTime" BU_SG_REL_ ZR_MIB_TOP_ab_Gen3 SG_ 2527679638 KBI_GZeit_Sek 5000;
BA_REL_ "GenSigTimeoutTime" BU_SG_REL_ ZR_MIB_TOP_ab_Gen3 SG_ 2527679638 KBI_RZeit_HSek 5000;
BA_REL_ "GenSigTimeoutTime" BU_SG_REL_ ZR_MIB_TOP_ab_Gen3 SG_ 2527679638 KBI_RZeit_Min 5000;
BA_REL_ "GenSigTimeoutTime" BU_SG_REL_ ZR_MIB_TOP_ab_Gen3 SG_ 2527679638 KBI_RZeit_Sek 5000;
BA_REL_ "GenSigTimeoutTime" BU_SG_REL_ ZR_MIB_TOP_ab_Gen3 SG_ 2527679638 KBI_RZeit_Std 5000;
BA_REL_ "GenSigTimeoutTime" BU_SG_REL_ ZR_MIB_TOP_ab_Gen3 SG_ 2527679639 KBI_Weg_Zaehler_F 5000;
BA_REL_ "GenSigTimeoutTime" BU_SG_REL_ ZR_MIB_TOP_ab_Gen3 SG_ 2527679639 KBI_Weg_Zaehler 5000;
BA_REL_ "GenSigTimeoutTime" BU_SG_REL_ ZR_MIB_TOP_ab_Gen3 SG_ 2527679639 KBI_Jokerkey 5000;
BA_REL_ "GenSigTimeoutTime" BU_SG_REL_ ZR_MIB_TOP_ab_Gen3 SG_ 981 BCM_Rueckfahrlicht_Anf 1000;
BA_REL_ "GenSigTimeoutTime" BU_SG_REL_ ZR_MIB_TOP_ab_Gen3 SG_ 134 LWI_Sensorstatus 1000;
BA_REL_ "GenSigTimeoutTime" BU_SG_REL_ ZR_MIB_TOP_ab_Gen3 SG_ 134 LWI_QBit_Lenkradwinkel 1000;
BA_REL_ "GenSigTimeoutTime" BU_SG_REL_ ZR_MIB_TOP_ab_Gen3 SG_ 134 LWI_Lenkradwinkel 1000;
BA_REL_ "GenSigTimeoutTime" BU_SG_REL_ ZR_MIB_TOP_ab_Gen3 SG_ 134 LWI_VZ_Lenkradwinkel 1000;
BA_REL_ "GenSigTimeoutTime" BU_SG_REL_ ZR_Standard SG_ 1719 KBI_Standzeit_02 5000;
BA_REL_ "GenSigTimeoutTime" BU_SG_REL_ ZR_Standard SG_ 1719 KBI_Reserve_Warnung_Sek 5000;
BA_REL_ "GenSigTimeoutTime" BU_SG_REL_ ZR_Standard SG_ 1719 KBI_FStatus_Tank 5000;
BA_REL_ "GenSigTimeoutTime" BU_SG_REL_ ZR_Standard SG_ 1719 KBI_Aussen_Temp_gef 5000;
BA_REL_ "GenSigTimeoutTime" BU_SG_REL_ ZR_Standard SG_ 1720 KBI_Reifenumfang 5000;
BA_REL_ "GenSigTimeoutTime" BU_SG_REL_ ZR_Standard SG_ 2527679653 MXB_LAPP_ZR_Sondermodus_Anf 5000;
BA_REL_ "GenSigTimeoutTime" BU_SG_REL_ ZR_Standard SG_ 981 BCM_Rueckfahrlicht_Anf 1000;
BA_REL_ "GenSigTimeoutTime" BU_SG_REL_ ZR_Standard SG_ 134 LWI_Sensorstatus 1000;
BA_REL_ "GenSigTimeoutTime" BU_SG_REL_ ZR_Standard SG_ 134 LWI_QBit_Lenkradwinkel 1000;
BA_REL_ "GenSigTimeoutTime" BU_SG_REL_ ZR_Standard SG_ 134 LWI_Lenkradwinkel 1000;
BA_REL_ "GenSigTimeoutTime" BU_SG_REL_ ZR_Standard SG_ 134 LWI_VZ_Lenkradwinkel 1000;
VAL_ 1719 KBI_Kilometerstand 1048574 "Init" 1048575 "Fehler" ;
VAL_ 1719 KBI_Standzeit_02 131069 "nicht_verfuegbar" 131070 "Init" 131071 "Fehler" ;
VAL_ 1719 KBI_LVDS_Lock 0 "Init_LVDS_nicht_gelockt" 1 "LVDS_gelockt" ;
VAL_ 1719 KBI_Reserve_Warnung_Sek 0 "Keine_Warnung" 1 "Sekundaere_Reservewarnung" ;
VAL_ 1719 KBI_RDK_Kalibrier_Anf 0 "keine_Kalibrieranforderung" 1 "Kalibrieranforderung" ;
VAL_ 1719 KBI_Inhalt_Tank 126 "Init" 127 "Fehler" ;
VAL_ 1719 KBI_FStatus_Tank 0 "Tankfüllstand i.O." 1 "Tankfüllstand n.i.O" ;
VAL_ 1719 KBI_aktive_Laengsfunktion 0 "Init" 1 "Speedlimiter" 2 "GRA_oder_ACC" 3 "PACCh" 4 "HDC" 5 "p_GRA" 6 "p_Lim" 7 "Umschaltung_GRA_Limiter" ;
VAL_ 1719 KBI_FoD_PopUP_Quittiert 0 "nicht_quittiert" 1 "Meldung_quittiert" ;
VAL_ 1719 KBI_GRA_im_ACC 0 "GRA_im_ACC_nicht_ausgewaehlt" 1 "GRA_im_ACC_ausgewaehlt" ;
VAL_ 1719 KBI_Oelwechsel_durchgefuehrt 0 "Oelwechsel_nicht_durchgefuehrt" 1 "Oelwechsel_durchgefuehrt" ;
VAL_ 1719 KBI_QBit_Aussen_Temp_gef 0 "gueltiger_Wert" 1 "Ersatz_Init_oder_Fehlerwert" ;
VAL_ 1719 KBI_Aussen_Temp_gef 253 "nicht verbaut" 254 "Init" 255 "Fehler" ;
VAL_ 1720 KBI_Variante_USA 0 "keine USA-Variante" 1 "USA-Variante" ;
VAL_ 1720 KBI_Variante 0 "Zeiger Kombiinstrument" 1 "Volldisplay Kombiinstrument" ;
VAL_ 1720 KBI_GAP_Warn_Zeit_abgelaufen 0 "Zaehler_nicht_abgelaufen" 1 "Zaehler_abgelaufen" ;
VAL_ 1720 KBI_Quittierung_Naesse 0 "nicht_quittiert" 1 "quittiert" ;
VAL_ 1720 KBI_BCmE_aktiv 0 "Anzeige_nicht_aktiv" 1 "Anzeige_aktiv" ;
VAL_ 1720 KBI_Sparhinweis_quittiert 0 "nicht_quittiert" 1 "quittiert" ;
VAL_ 1720 KBI_Tankfuellstand_Prozent 126 "Init" 127 "Fehler" ;
VAL_ 1720 KBI_Nachtanken_erkannt 0 "Geberbetrieb" 1 "Nachtankmodus" ;
VAL_ 1720 KBI_Tankinhalt_hochaufl 16382 "Init" 16383 "Fehler" ;
VAL_ 1720 KBI_Max_Tankinhalt 254 "Init" 255 "Fehler" ;
VAL_ 1720 KBI_Quittierung_cAQP 0 "nicht_quittiert" 1 "quittiert" ;
VAL_ 1724 KBI_Oil_dis_status 0 "Funktion nicht verfügbar" 1 "kein Wert berechnet" 2 "Service in ..." 3 "Service seit ... " ;
VAL_ 1724 KBI_Oil_dis_unit 0 "km" 1 "Meilen" ;
VAL_ 1724 KBI_Oil_time_status 0 "Funktion nicht verfügbar" 1 "kein Wert berechnet" 2 "Service in ..." 3 "Service seit ... " ;
VAL_ 1724 KBI_Insp_dis_status 0 "Funktion nicht verfügbar" 1 "kein Wert berechnet" 2 "Service in ..." 3 "Service seit ... " ;
VAL_ 1724 KBI_Insp_dis_unit 0 "km" 1 "Meilen" ;
VAL_ 1724 KBI_Insp_time_status 0 "Funktion nicht verfügbar" 1 "kein Wert berechnet" 2 "Service in ..." 3 "Service seit ... " ;
VAL_ 2527679638 KBI_Status_StoppUhr 0 "init" 1 "not_running_reset" 2 "not_running_no_reset" 3 "running" ;
VAL_ 2527679639 KBI_Weg_Zaehler_F 0 "kein Fehler" 1 "Fehler" ;
VAL_ 2527679639 KBI_Jokerkey 0 "nicht_betaetigt" 1 "betaetigt" ;
VAL_ 2527679639 KBI_RS_Druck_uebernehmen 0 " Druck für Rundstreckenmodue nicht uebernehmen" 1 " Druck für Rundstreckenmodus uebernehmen" ;
VAL_ 2527679639 KBI_RS_Druckauswahl_Aktiv 0 "inaktiv" 1 "aktiv" ;
VAL_ 2527679639 KBI_RS_Mode_fortsetzen 0 "Rundstreckenmodus_nicht_fortsetzen" 1 "Rundstreckenmodus_fortsetzen" ;
VAL_ 2527679639 KBI_Rundstreckenmodus 0 "nicht_angefordert" 1 "angefordert" ;
VAL_ 2527679656 KBI_StartupAnimation 0 "Init" 1 "StartMeasureDelay" 2 "RequestStartAnimation" 3 "RequestCancelAnimation" 4 "CIAnimationStarted" 5 "CIAnimationStopped" ;
VAL_ 701 LAE_BetaSlipAngle_02 32766 "Init" 32767 "Fehler" ;
VAL_ 701 LAE_Vx_VZ 0 "Positive" 1 "Negative" ;
VAL_ 701 LAE_mu_confidence 0 "Factor_0" 1 "Factor_1" 2 "Factor_2" 3 "Factor_3" 4 "Factor_4" 5 "Factor_5" 6 "Factor_6" 7 "Factor_7" ;
VAL_ 701 LAE_mu 62 "Init" 63 "Fehler" ;
VAL_ 701 LAE_Vy 62 "Init" 63 "Fehler" ;
VAL_ 701 LAE_Vy_confidence 0 "Factor_0" 1 "Factor_1" 2 "Factor_2" 3 "Factor_3" 4 "Factor_4" 5 "Factor_5" 6 "Factor_6" 7 "Factor_7" ;
VAL_ 701 LAE_BetaSlipAngle 254 "Init" 255 "Fehler" ;
VAL_ 701 LAE_Beta_VZ 0 "positive_links_von_der_nullst" 1 "negativ" ;
VAL_ 701 LAE_Beta_confidence 0 "Factor_0" 1 "Factor_1" 2 "Factor_2" 3 "Factor_3" 4 "Factor_4" 5 "Factor_5" 6 "Factor_6" 7 "Factor_7" ;
VAL_ 701 LAE_Vx_confidence 0 "Factor_0" 1 "Factor_1" 2 "Factor_2" 3 "Factor_3" 4 "Factor_4" 5 "Factor_5" 6 "Factor_6" 7 "Factor_7" ;
VAL_ 701 LAE_Vx 510 "Init" 511 "Fehler" ;
VAL_ 2527679653 MXB_LAPP_Freigabe 0 "keine_Freigabe" 1 "Freigabe" ;
VAL_ 2527679653 MXB_LAPP_ZR_Sondermodus_Anf 0 "nicht_angefordert" 1 "angefordert" ;
VAL_ 2527679653 MXB_LAPP_Status_FL 0 "MXB_aus" 1 "MXB_regelt" 2 "MXB_volles_Fernlicht" 3 "MXB_und_Laser_aktiv" ;
VAL_ 2463978818 LCV_ESP_Zuschaltung 0 "keine_ESP_Beeinflussung" 1 "ESP_Zwangszuschaltung_gefordert" ;
VAL_ 2463978818 LCV_BrakeGongTemp 0 "Not_Active" 1 "Active" ;
VAL_ 2463978818 BTM_BrakeSystem_Status 0 "Status_1" 1 "Status_2" 2 "Status_3" 3 "Status_4" 4 "Status_5" 5 "Status_6" 6 "Status_7" 7 "Fehler" ;
VAL_ 2463978818 BTM_BrakeSystem_Text 0 "No_text" 1 "Text_1" 2 "Text_2" 3 "Text_3" 4 "Text_4" 5 "Text_5" 6 "Text_6" 7 "Text_7" ;
VAL_ 2463978818 BTM_BrakeSystem_Warnlampe 0 "Lamp_Off" 1 "Lamp_On" ;
VAL_ 2463978818 LCV_Aero_EngineBay_Cooling 0 "Strategy_OFF" 1 "Strategy_ON" ;
VAL_ 2463978818 LCV_Aero_Front_System_Status 0 "Closed" 1 "Position_1" 2 "Position_2" 3 "Opening" 4 "Closing" 5 "Bar_Mode" 6 "Special_Position" 7 "Failure" ;
VAL_ 2463978818 LCV_Aero_Rear_System_Status 0 "Closed" 1 "Position_1" 2 "Position_2" 3 "Opening" 4 "Closing" 5 "Bar_Mode" 6 "Special_Position" 7 "Failure" ;
VAL_ 2463978818 LCV_DR_Systemstatus 0 "Init" 1 "Normal_Operation" 2 "Tune_1" 3 "Tune_2" 4 "Tune_3" 5 "Tune_4" 6 "Function_restriction_active" 7 "Failure" ;
VAL_ 2463978818 LCV_DR_Text 0 "No_Text" 1 "Text_1" 2 "Text_2" 3 "Text_3" 4 "Text_4" 5 "Text_5" 6 "Text_6" 7 "Text_7" ;
VAL_ 2463978818 LCV_DR_Warnlampe 0 "Lamp_Off" 1 "Lamp_On_1" 2 "Lamp_On_2" 3 "Failure_Lamp" ;
VAL_ 2463978818 LCV_Lift_Status 0 "Lowered" 1 "Lifted_front" 2 "Lifting_front" 3 "Lowering_front" 4 "Temporary_unavailable" 5 "Warning" 6 "TBD" 7 "Fehler" 8 "Lifted_four_corner" 9 "Lifting_four_corner" 10 "Lowering_four_corner" ;
VAL_ 2463978818 LCV_Lift_Text 0 "No_Text" 1 "Text_1" 2 "Text_2" 3 "Text_3" 4 "Text_4" 5 "Text_5" 6 "Text_6" 7 "Text_7" ;
VAL_ 2463978818 LCV_Lift_Warnlampe_Status 0 "Lamp_Off" 1 "Lamp_On_Static" 2 "Lamp_On_Blinking" 3 "Failure_Lamp" ;
VAL_ 2463978818 LCV_Aero_Perf_Limit_Speed 254 "init" 255 "Fehler" ;
VAL_ 2463978818 LCV_Aero_Perf_Limit 0 "Strategy_OFF" 1 "Strategy_ON" ;
VAL_ 2463978818 LCV_HD_offen 1 "Heckdeckel_auf" ;
VAL_ 2527679780 LCV_Aero_BarMode_Activation 0 "Not_Active" 1 "Active" ;
VAL_ 2527679780 LCV_BarMode_Allowed 0 "Not_Active" 1 "Active" ;
VAL_ 2527679780 LCV_Aero_Button_Default 0 "None" 1 "Button_1" 2 "Button_2" 3 "Button_3" ;
VAL_ 2527679780 LCV_Aero_Button_Range 0 "none" 1 "first_two" 2 "last_two" 3 "all_three" ;
VAL_ 2527679780 LCV_Aero_Button_Select 0 "None" 1 "Button_1" 2 "Button_2" 3 "Button_3" ;
VAL_ 2527679780 LCV_Aero_Button_Tunable 0 "Not_tunable" 1 "Tunable" ;
VAL_ 2527679780 LCV_DR_Button_Default 0 "None" 1 "Button_1" 2 "Button_2" 3 "Button_3" ;
VAL_ 2527679780 LCV_DR_Button_Range 0 "none" 1 "first_two" 2 "last_two" 3 "all_three" ;
VAL_ 2527679780 LCV_DR_Button_Select 0 "Init" 1 "Button_1" 2 "Button_2" 3 "Button_3" 4 "None" ;
VAL_ 2527679780 LCV_DR_Button_Tunable 0 "Not_tunable" 1 "Tunable" ;
VAL_ 2463978684 BTM_BrakeDiscTemp_01 254 "Init" 255 "Fehler" ;
VAL_ 2463978684 BTM_BrakeDiscTemp_02 254 "Init" 255 "Fehler" ;
VAL_ 2463978684 BTM_BrakeDiscTemp_03 254 "Init" 255 "Fehler" ;
VAL_ 2463978684 BTM_BrakeDiscTemp_04 254 "Init" 255 "Fehler" ;
VAL_ 2463978684 BTM_BrakeFluidTemp_01 254 "Init" 255 "Fehler" ;
VAL_ 2463978684 BTM_BrakeFluidTemp_02 254 "Init" 255 "Fehler" ;
VAL_ 2463978684 BTM_BrakeFluidTemp_03 254 "Init" 255 "Fehler" ;
VAL_ 2463978684 BTM_BrakeFluidTemp_04 254 "Init" 255 "Fehler" ;
VAL_ 548 LCV_Aero_Front_Ratio 126 "init" 127 "Fehler" ;
VAL_ 548 LCV_Aero_Long_Ratio 126 "init" 127 "Fehler" ;
VAL_ 2589283974 BTM_BrakeDiscColour_01 0 "Colour_0" 1 "Colour_1" 2 "Colour_2" 3 "Colour_3" 4 "Colour_4" 5 "Colour_5" 6 "Colour_6" 7 "Fehler" ;
VAL_ 2589283974 BTM_BrakeDiscColour_02 0 "Colour_0" 1 "Colour_1" 2 "Colour_2" 3 "Colour_3" 4 "Colour_4" 5 "Colour_5" 6 "Colour_6" 7 "Fehler" ;
VAL_ 2589283974 BTM_BrakeDiscColour_03 0 "Colour_0" 1 "Colour_1" 2 "Colour_2" 3 "Colour_3" 4 "Colour_4" 5 "Colour_5" 6 "Colour_6" 7 "Fehler" ;
VAL_ 2589283974 BTM_BrakeDiscColour_04 0 "Colour_0" 1 "Colour_1" 2 "Colour_2" 3 "Colour_3" 4 "Colour_4" 5 "Colour_5" 6 "Colour_6" 7 "Fehler" ;
VAL_ 2589283974 BTM_BrakeFluidColour_01 0 "Colour_0" 1 "Colour_1" 2 "Colour_2" 3 "Colour_3" 4 "Colour_4" 5 "Colour_5" 6 "Colour_6" 7 "Fehler" ;
VAL_ 2589283974 BTM_BrakeFluidColour_02 0 "Colour_0" 1 "Colour_1" 2 "Colour_2" 3 "Colour_3" 4 "Colour_4" 5 "Colour_5" 6 "Colour_6" 7 "Fehler" ;
VAL_ 2589283974 BTM_BrakeFluidColour_03 0 "Colour_0" 1 "Colour_1" 2 "Colour_2" 3 "Colour_3" 4 "Colour_4" 5 "Colour_5" 6 "Colour_6" 7 "Fehler" ;
VAL_ 2589283974 BTM_BrakeFluidColour_04 0 "Colour_0" 1 "Colour_1" 2 "Colour_2" 3 "Colour_3" 4 "Colour_4" 5 "Colour_5" 6 "Colour_6" 7 "Fehler" ;
VAL_ 981 BCM1_Kurvenlicht_links_Anf 0 "linkes_Kurvenlicht/Abbiegelicht_durch_BCM1_nicht_angesteuert" 1 "linkes_Kurven/Abbiegelicht_durch_BCM1_angesteuert" ;
VAL_ 981 BCM1_Kurvenlicht_rechts_Anf 0 "rechtes_Kurvenlicht/Abbiegelicht_durch_BCM1_nicht_angesteuert" 1 "rechtes_Kurvenlicht/Abbiegelicht_durch_BCM1_angesteuert" ;
VAL_ 981 BCM1_Standlicht_Anf 0 "Licht_nicht_angefordert" 1 "Licht ist einzuschalten" ;
VAL_ 981 BCM1_Abblendlicht_Anf 0 "Licht_nicht_angefordert" 1 "Licht ist einzuschalten" ;
VAL_ 981 BCM1_Fernlicht_Anf 0 "Licht_nicht_angefordert" 1 "Licht ist einzuschalten" ;
VAL_ 981 BCM1_Nebellicht_Anf 0 "Licht_nicht_angefordert" 1 "Licht ist einzuschalten" ;
VAL_ 981 BCM1_Parklicht_li_Anf 0 "Licht_nicht_angefordert" 1 "Licht ist einzuschalten" ;
VAL_ 981 BCM1_Parklicht_re_Anf 0 "Licht_nicht_angefordert" 1 "Licht ist einzuschalten" ;
VAL_ 981 BCM1_Nebelschluss_Ahg_Anf 0 "Licht_nicht_angefordert" 1 "Licht ist einzuschalten" ;
VAL_ 981 BCM1_Nebelschluss_Fzg_Anf 0 "Licht_nicht_angefordert" 1 "Licht ist einzuschalten" ;
VAL_ 981 BCM1_Schlusslicht_Anf 0 "Licht_nicht_angefordert" 1 "Licht ist einzuschalten" ;
VAL_ 981 BCM_Rueckfahrlicht_Anf 0 "Licht_nicht_angefordert" 1 "Licht_angefordert" ;
VAL_ 981 BCM1_Signaturlicht_Anf 0 "Licht_nicht_angefordert" 1 "Licht_ist_einzuschalten" ;
VAL_ 981 BCM1_Umfeldleuchten_Anf 0 "Licht_nicht_angefordert" 1 "Licht_ist_einzuschalten" ;
VAL_ 981 BCM1_Tagfahrlicht_Anf 0 "Licht_nicht_angefordert" 1 "Licht ist einzuschalten" ;
VAL_ 981 BCM1_Regenlicht_Anf 0 "Licht_nicht_angefordert" 1 "Licht ist einzuschalten" ;
VAL_ 981 BCM1_Autobahnlicht_Anf 0 "Licht_nicht_angefordert" 1 "Licht ist einzuschalten" ;
VAL_ 981 BCM1_Touristen_Licht_Anf 0 "Licht_nicht_angefordert" 1 "Anforderung von Touristenlicht" ;
VAL_ 981 BCM1_CH_aktiv 0 "Inaktiv" 1 "Aktiv" ;
VAL_ 981 BCM1_LH_aktiv 0 "Inaktiv" 1 "Aktiv" ;
VAL_ 981 BCM1_Gleitende_Leuchtw_Anf 0 "Aus" 1 "Ein" ;
VAL_ 981 BCM1_GLW_Fernlicht_Anf 0 "Aus" 1 "Ein" ;
VAL_ 981 BCM1_Adaptive_Lichtvert_Anf 0 "Aus" 1 "Ein" ;
VAL_ 981 BCM1_FoD_Sperrung_WiBli 0 "Freigabe_WiBli" 1 "Sperrung_WiBli" 2 "Init" ;
VAL_ 981 BCM1_FOD_Sperrung_Animationen_HL 0 "Freigabe_Animationen" 1 "Sperrung_Animationen" 2 "Init" ;
VAL_ 981 BCM1_Animationssperrung 0 "keine_Sperrung" 1 "Sperrung" ;
VAL_ 981 BCM1_CH_LH_aktiv 0 "Comming_Home_Bzw._Leaving_Home_nicht_aktiv" 1 "Comming Home bzw. Leaving Home aktiv" ;
VAL_ 981 BCM1_Allwetterlicht_Anf 0 "Licht_nicht_angefordert" 1 "Licht_ist_einzuschalten" ;
VAL_ 981 BCM1_Schlusslicht_Signatur 0 "keine_Signatur" 1 "Signatur_1" 2 "Signatur_2" 3 "Signatur_3" 4 "Signatur_4" 5 "Signatur_5" 6 "Signatur_6" 7 "Signatur_7" 8 "Signatur_8" 9 "Signatur_9" 10 "Signatur_10" 11 "Signatur_11" 12 "Signatur_12" 13 "Signatur_13" 14 "Signatur_14" 15 "Signatur_15" ;
VAL_ 982 BCM2_Bremsl_durch_ECD 0 "Bremslicht_ist_aus" 1 "Bremslicht_durch_ECD_aktiv" ;
VAL_ 982 LH_Aussenlicht_def 0 "OK" 1 "defekt" ;
VAL_ 982 LH_Standlicht_H_aktiv 1 "Standlicht hinten aktiv" ;
VAL_ 982 LH_Parklicht_HL_aktiv 0 "nicht aktiv" 1 "Parklicht hinten links aktiv" ;
VAL_ 982 LH_Parklicht_HR_aktiv 0 "nicht aktiv" 1 "Parklicht hinten rechts aktiv" ;
VAL_ 982 LH_Bremslicht_H_aktiv 1 "Bremslicht hinten aktiv" ;
VAL_ 982 LH_Nebelschluss_aktiv 0 "nicht aktiv" 1 "aktiv" ;
VAL_ 982 LH_Rueckfahrlicht_aktiv 0 "nicht aktiv" 1 "aktiv" ;
VAL_ 982 LH_Blinker_HL_akt 1 "Blinker hinten links aktiv" ;
VAL_ 982 LH_Blinker_HR_akt 1 "Blinker hinten rechts aktiv" ;
VAL_ 982 LH_Blinker_li_def 0 "OK" 1 "Blinker hinten links defekt" ;
VAL_ 982 LH_Bremsl_li_def 0 "OK" 1 "mindestens ein Bremslicht hinten links defekt" ;
VAL_ 982 LH_Schlusslicht_li_def 0 "OK" 1 "mindestens ein Schlusslicht hinten links defekt" ;
VAL_ 982 LH_Rueckf_li_def 0 "OK" 1 "Rückfahrlicht hinten links defekt" ;
VAL_ 982 LH_Nebel_li_def 0 "OK" 1 " Nebelschlusslicht hinten links defekt" ;
VAL_ 982 LH_Schluss_Brems_Nebel_li_def 0 "iO" 1 "defekt" ;
VAL_ 982 LH_Schluss_Brems_Nebel_re_def 0 "iO" 1 "defekt" ;
VAL_ 982 LH_Zusatzschlussl_def 0 "OK" 1 "mindestens_ein_Zusatzschlusslicht_defekt" ;
VAL_ 982 LH_Schluss_Brems_li_def 0 "OK" 1 "defekt" ;
VAL_ 982 LH_Schluss_Nebel_li_def 0 "OK" 1 "defekt" ;
VAL_ 982 LH_SL_BRL_BLK_li_def 0 "OK" 1 "defekt" ;
VAL_ 982 LH_Brems_Blk_li_def 0 "OK" 1 "defekt" ;
VAL_ 982 LH_Diag_Status_re_def 0 "OK" 1 "Aussenlict_Diagnose_Systemstoerung_rechts" ;
VAL_ 982 LH_Diag_Status_li_def 0 "OK" 1 "Aussenlicht_Diagnose_Systemstoerung_links" ;
VAL_ 982 LH_Diag_LED_li_def 0 "OK" 1 "Heckleuchte_links_defekt" ;
VAL_ 982 LH_Diag_LED_re_def 0 "OK" 1 "Heckleuchte_rechts_defekt" ;
VAL_ 982 LH_Blinker_re_def 0 "OK" 1 "Blinker hinten rechts defekt" ;
VAL_ 982 LH_Bremsl_re_def 0 "OK" 1 "mindestens ein Bremslicht hinten rechts defekt" ;
VAL_ 982 LH_Schlusslicht_re_def 0 "OK" 1 "mindestens ein Schlusslicht hinten rechts defekt" ;
VAL_ 982 LH_Rueckf_re_def 0 "OK" 1 "Rückfahrlicht hinten rechts defekt" ;
VAL_ 982 LH_Nebel_re_def 0 "OK" 1 "Nebelschlusslicht hinten rechts defekt" ;
VAL_ 982 LH_Schluss_Brems_mi_def 0 "OK" 1 "Defekt" ;
VAL_ 982 LH_Schluss_Brems_re_def 0 "OK" 1 "defekt" ;
VAL_ 982 LH_Schluss_Nebel_re_def 0 "OK" 1 "defekt" ;
VAL_ 982 LH_SL_BRL_BLK_re_def 0 "OK" 1 "defekt" ;
VAL_ 982 LH_Brems_Blk_re_def 0 "OK" 1 "defekt" ;
VAL_ 982 LH_Kennzl_def 0 "OK" 1 "Kennzeichenbeleuchtung hinten defekt" ;
VAL_ 982 LH_3_Bremsl_def 0 "OK" 1 "hochgesetzte  Bremsleuchte defekt" ;
VAL_ 982 LH_Nebel_mi_def 0 "OK" 1 " Nebelschlusslicht hinten Mitte defekt" ;
VAL_ 982 LH_Rueckf_mi_def 0 "OK" 1 "Rückfahllicht Mitte defekt" ;
VAL_ 982 LH_Schlusslicht_mi_def 0 "OK" 1 "defekt" ;
VAL_ 982 LH_Bremsl_mi_def 0 "OK" 1 "defekt" ;
VAL_ 982 LH_Bremsl_li_ges_def 0 "OK" 1 "Alle Bremslichter hinten links defekt" ;
VAL_ 982 LH_Bremsl_re_ges_def 0 "OK" 1 "Alle Bremslichter hinten rechts defekt" ;
VAL_ 1624 LV_Standlicht_Anzeige 0 "nicht aktiv" 1 "aktiv" ;
VAL_ 1624 LV_Abblendlicht_Anzeige 0 "inaktiv" 1 "aktiv" ;
VAL_ 1624 LV_Fernlicht_Anzeige 0 "nicht aktiv" 1 "aktiv" ;
VAL_ 1624 LV_Nebellicht_Anzeige 0 "nicht aktiv" 1 "aktiv" ;
VAL_ 1624 LV_Nebelschlusslicht_Anzeige 0 "nicht aktiv" 1 "aktiv" ;
VAL_ 1624 LV_Tagfahrlicht_Anzeige 0 "nicht aktiv" 1 "aktiv" ;
VAL_ 1624 LV_AFL_aktiv_Anzeige 0 "nicht aktiv" 1 "aktiv" ;
VAL_ 1624 LV_AFL_defekt 0 "OK" 1 "defekt" ;
VAL_ 1624 LV_Blinker_li_def 0 "OK" 1 "defekt" ;
VAL_ 1624 LV_Standlicht_li_def 0 "OK" 1 "defekt" ;
VAL_ 1624 LV_Abblendlicht_li_def 0 "OK" 1 "defekt" ;
VAL_ 1624 LV_Fernlicht_li_def 0 "OK" 1 "defekt" ;
VAL_ 1624 LV_Nebellicht_li_def 0 "OK" 1 "defekt" ;
VAL_ 1624 LV_Blk_li_Seite_def 0 "OK" 1 "defekt" ;
VAL_ 1624 LV_Tagfahrlicht_li_def 0 "OK" 1 "defekt" ;
VAL_ 1624 LV_FLA_aktiv_Anzeige 0 "aus" 1 "ein" ;
VAL_ 1624 LV_FLA_defekt 0 "i.O." 1 "FLA defekt" ;
VAL_ 1624 LV_FLA_Sensor_blockiert 0 "i.O." 1 "FLA-Sensor blockiert" ;
VAL_ 1624 LV_Blinker_re_def 0 "OK" 1 "defekt" ;
VAL_ 1624 LV_Standlicht_re_def 0 "OK" 1 "defekt" ;
VAL_ 1624 LV_Abblendlicht_re_def 0 "OK" 1 "defekt" ;
VAL_ 1624 LV_Fernlicht_re_def 0 "OK" 1 "defekt" ;
VAL_ 1624 LV_Nebellicht_re_def 0 "OK" 1 "defekt" ;
VAL_ 1624 LV_Blk_re_Seite_def 0 "OK" 1 "defekt" ;
VAL_ 1624 LV_Tagfahrlicht_re_def 0 "OK" 1 "defekt" ;
VAL_ 1624 LV_Aussenlicht_def 0 "OK" 1 "defekt" ;
VAL_ 1624 LV_Abblendlicht_TFL_li_def 0 "OK" 1 "defekt" ;
VAL_ 1624 LV_Nebellicht_TFL_li_def 0 "OK" 1 "defekt" ;
VAL_ 1624 LV_Standlicht_TFL_li_def 0 "OK" 1 "defekt" ;
VAL_ 1624 LV_Abblend_Fernlicht_li_def 0 "OK" 1 "defekt" ;
VAL_ 1624 LV_Abblendlicht_TFL_re_def 0 "OK" 1 "defekt" ;
VAL_ 1624 LV_Nebellicht_TFL_re_def 0 "OK" 1 "defekt" ;
VAL_ 1624 LV_Standlicht_TFL_re_def 0 "OK" 1 "defekt" ;
VAL_ 1624 LV_Abblend_Fernlicht_re_def 0 "OK" 1 "defekt" ;
VAL_ 1624 LV_Abbiegelicht_li_def 0 "OK" 1 "defekt" ;
VAL_ 1624 LV_Abbiegelicht_re_def 0 "OK" 1 "defekt" ;
VAL_ 1624 BCM1_Linksverkehr 0 "Rechtsverkehr" 1 "Linksverkehr" ;
VAL_ 1624 BCM1_Licht_Dunkelheit_aktiv 0 "inaktiv" 1 "aktiv" ;
VAL_ 1624 LV_LED_Scheinwerfer_li_def 0 "OK" 1 "defekt" ;
VAL_ 1624 LV_LED_Scheinwerfer_re_def 0 "OK" 1 "defekt" ;
VAL_ 1624 LV_Blinker_VL_aktiv 0 "inaktiv" 1 "aktiv" ;
VAL_ 1624 LV_Blinker_VR_aktiv 0 "inaktiv" 1 "aktiv" ;
VAL_ 1624 LV_MXB_Status_Anzeige 0 "MXB_aus" 1 "MXB_regelt" 2 "MXB_volles_Fernlicht" 3 "MXB_und_Laser_aktiv" ;
VAL_ 1321 Lift_Charisma_FahrPr 0 "nicht_belegt" 1 "Programm_1" 2 "Programm_2" 3 "Programm_3" 4 "Programm_4" 5 "Programm_5" 6 "Programm_6" 7 "Programm_7" ;
VAL_ 1321 Lift_Charisma_Status 0 "Init" 1 "verfuegbar" 2 "nicht_verfuegbar" 3 "asynchron_durch_Fahrerwunsch" ;
VAL_ 1321 Lift_Charisma_Umschaltung 0 "Idle" 1 "Erkennung_Umschaltaufforderung" 2 "Steuerbotschaft_nicht_definiert" 3 "Umschaltung_verzoegert" ;
VAL_ 1321 Lift_Anforderung_EFP 0 "Init" 1 "Anforderung_Tiefniveau" 2 "Anforderung_Hochniveau" ;
VAL_ 1321 Lift_ESP_Zuschaltung 0 "keine_ESP_Beeinflussung" 1 "ESP_Zwangszuschaltung_gefordert" ;
VAL_ 1321 Lift_Meldung_12 0 "inaktiv" 1 "aktiv" ;
VAL_ 1321 Lift_Meldung_13 0 "inaktiv" 1 "aktiv" ;
VAL_ 1321 Lift_Meldung_14 0 "inaktiv" 1 "aktiv" ;
VAL_ 1321 Lift_LED 0 "LED_aus" 1 "LED_ein" 2 "LED_blinken" 3 "Fehler" ;
VAL_ 1321 Lift_Position 0 "Init" 1 "Lift_in_Endlage_unten" 2 "Lift_in_Endlage_oben" 3 "Ausfuehrung_Hebevorgang" 4 "Ausfuehrung_Senkvorgang" 5 "Lift_in_zwischenstellung" ;
VAL_ 1321 Lift_Meldung_01 0 "inaktiv" 1 "aktiv" ;
VAL_ 1321 Lift_Meldung_02 0 "Init" 1 "Meldung_aktiv" ;
VAL_ 1321 Lift_Meldung_03 0 "inaktiv" 1 "aktiv" ;
VAL_ 1321 Lift_Meldung_04 0 "inaktiv" 1 "aktiv" ;
VAL_ 1321 Lift_Meldung_05 0 "inaktiv" 1 "aktiv" ;
VAL_ 1321 Lift_Meldung_06 0 "inaktiv" 1 "aktiv" ;
VAL_ 1321 Lift_Meldung_07 0 "inaktiv" 1 "aktiv" ;
VAL_ 1321 Lift_Meldung_08 0 "inaktiv" 1 "aktiv" ;
VAL_ 1321 Lift_Meldung_09 0 "inaktiv" 1 "aktiv" ;
VAL_ 1321 Lift_Meldung_10 0 "inaktiv" 1 "aktiv" ;
VAL_ 1321 Lift_Meldung_11 0 "inaktiv" 1 "aktiv" ;
VAL_ 1321 Lift_SpannungsAnf 0 "Keine_Anforderung" 1 "Anforderung_Stufe1" 2 "Anforderung_Stufe2" 3 "Anforderung_Stufe3" ;
VAL_ 1321 Lift_StartStopp_Info 0 "Motorlauf_nicht_notwendig_(Stoppfreigabe)" 1 "Motoranlauf_nicht_zwingend_notwendig_(Stoppverbot,keine_Startanforderung)" 2 "Motoranlauf_zwingend_notwendig_(Startanforderung)" 3 "Systemfehler" ;
VAL_ 822 LR_HZG_Temp_Sensor 253 "KS_Plus__Unterbrechung" 254 "Init" 255 "Tempsensor_fehlerhaft__KS_GND" ;
VAL_ 822 LR_HZG_Taster_on_off 0 "nicht_betaetigt" 1 "betaetigt" ;
VAL_ 2527679774 LRM_General_Error 0 "No_fault" 1 "Fault_present" ;
VAL_ 2527679774 LRM_Auto_Error 0 "No_fault" 1 "Auto_not_available" ;
VAL_ 2527679774 LRM_Manual_Error 0 "No_fault" 1 "Manual_not_available" ;
VAL_ 2527679774 LRM_Glass_OC_Error 0 "No_fault" 1 "Fault_present" ;
VAL_ 2527679774 LRM_Glass_SC_Error 0 "No_fault" 1 "Fault_present" ;
VAL_ 2527679774 LRM_Glass_Rear_OC_Error 0 "No_fault" 1 "Fault_present" ;
VAL_ 2527679774 LRM_Glass_Rear_SC_Error 0 "No_fault" 1 "Fault_present" ;
VAL_ 2527679774 LRM_Level 0 "Changing_level" 1 "Off" 2 "Level_1" 3 "Level_2" 4 "Clear" 6 "Init" 7 "Fehler" ;
VAL_ 2527679774 LRM_Level_Rear 0 "Changing_level" 1 "Off" 2 "Level_1" 3 "Level_2" 4 "Clear" 6 "Init" 7 "Fehler" ;
VAL_ 2527679774 LRM_Mode 0 "Changing_mode" 1 "Auto" 2 "Manual" 6 "Init" 7 "Fehler" ;
VAL_ 134 LWI_Sensorstatus 0 "iO" 1 "nicht kalibriert" ;
VAL_ 134 LWI_QBit_Sub_Daten 0 "LWS-Subinfo real (Lenkradwinkelinformation ADS-tauglich) " 1 "LWS-Subinfo simuliert (Lenkradwinkelinformation nicht ADS-tauglich )" ;
VAL_ 134 LWI_MFL_Abschaltung 0 "inaktiv" 1 "aktiv" ;
VAL_ 134 LWI_QBit_Lenkradwinkel 0 "gültiger Wert" 1 "ausserhalb der Spezifikation" ;
VAL_ 134 LWI_Lenkradwinkel 8190 "Init" 8191 "Fehler" ;
VAL_ 134 LWI_VZ_Lenkradwinkel 0 "positiv_links_von_der_Nullstellung" 1 "negativ" ;
VAL_ 134 LWI_VZ_Lenkradw_Geschw 0 "positiv_links_von_der_Nullstellung" 1 "negativ" ;
VAL_ 134 LWI_Lenkradw_Geschw 510 "Init" 511 "Fehler" ;
VAL_ 917 AFS_Abbiegelicht_li_Anf 0 "Abbiegelicht_aus" 1 "Abbiegelicht_ein" ;
VAL_ 917 AFS_Abbiegelicht_re_Anf 0 "Abbiegelicht_aus" 1 "Abbiegelicht_ein" ;
VAL_ 917 AFS_Abbiegelicht_Dimm_Anf 0 "Dimmung_angefordert" 1 "keine_Dimmung" ;
VAL_ 917 AFS_Verfuegbarkeit_GLW 0 "GLW_nicht_verfuegbar" 1 "GLW_verfuegbar" ;
VAL_ 917 AFS_Status_adaptive_LV 0 "adaptive_Lichtverteilung_aus" 1 "adaptive_Lichtverteilung_an" ;
VAL_ 917 AFS_Fernlicht_li_defekt 0 "Fernlicht_in_Ordnung" 1 "Fernlicht_defekt" ;
VAL_ 917 AFS_Fernlicht_re_defekt 0 "Fernlicht_in_Ordnung" 1 "Fernlicht_defekt" ;
VAL_ 917 AFS_Fernlicht_Status 0 "Fernlicht_aus" 1 "Fernlicht_ein" ;
VAL_ 917 AFS_Lampe 0 "Aus" 1 "Ein" ;
VAL_ 917 LWR_Lampe 0 "LWR Fehlerlampe aus" 1 "LWR Fehlerlampe ein" ;
VAL_ 917 AFS_Fehlertext 0 "kein Text" 1 "AFS ohne Funktion" ;
VAL_ 917 AFS_LED_Blinkmode 0 "kein Blinkmode angefordert" 1 "Blinkmode angefordert" ;
VAL_ 917 LWR_Touristenmodus_aktiv 0 "Touristenmodus inaktiv" 1 "Touristenmodus aktiv" ;
VAL_ 917 AFS_Charisma_FahrPr 0 "keine_Funktion" 1 "Programm_1" 2 "Programm_2" 3 "Programm_3" 4 "Programm_4" 5 "Programm_5" 6 "Programm_6" 7 "Programm_7" 8 "Programm_8" 9 "Programm_9" 10 "Programm_10" 11 "Programm_11" 12 "Programm_12" 13 "Programm_13" 14 "Programm_14" 15 "Programm_15" ;
VAL_ 917 AFS_Charisma_Status 0 "Init" 1 "verfuegbar" 2 "nicht_verfuegbar" 3 "asynchron_durch_Fahrerwunsch" ;
VAL_ 917 LWR_Sicherheitsposition_re 0 "inaktiv" 1 "aktiv" ;
VAL_ 917 AFS_Allwetterlicht 0 "Allwetterlicht_nicht_aktiv" 1 "Allwetterlicht_aktiv" ;
VAL_ 917 LWR_Touristenmodus_verbaut 0 "Touristenmodus_nicht_verbaut" 1 "Touristenmodus_verbaut" ;
VAL_ 917 AFS_adaptive_LV_verbaut 0 "adaptive_Lichtverteilung_nicht_verbaut" 1 "adaptive_Lichtverteilung_verbaut" ;
VAL_ 917 LWR_Reisemodus_Texte 0 "keine_Anzeige" 1 "Umschaltung_auf_Linksverkehr_aktiv" 2 "Umschaltung_auf_Rechtsverkehr_aktiv" ;
VAL_ 917 GLW_Sensor_blockiert 0 "Kamera_Sensor_nicht_blockiert" 1 "Kamera_Sensor_blockiert" ;
VAL_ 917 AFS_Charisma_Umschaltung 0 "Idle" 1 "Erkennung_Umschaltaufforderung" 2 "Steuerbotschaft_nicht_definiert" 3 "Umschaltung_verzoegert" ;
VAL_ 917 LWR_Pos_Schrittmotor 254 "Init" 255 "Fehler" ;
VAL_ 917 LWR_Hoehenwert_VL 254 "nicht_initialisiert" 255 "Fehler" ;
VAL_ 917 LWR_Hoehenwert_HL 254 "nicht_initialisiert" 255 "Fehler" ;
VAL_ 917 AFS_Ersatzlicht_Links 0 "keine Ersatzlichtfunktion links" 1 "Ersatzlichtfunktion links" ;
VAL_ 917 AFS_Ersatzlicht_Rechts 0 "keine Ersatzlichtfunktion rechts" 1 "Ersatzlichtfunktion rechts" ;
VAL_ 917 LWR_AFS_Grundeinstellung 0 "Grundeinstellung nicht erfolgt" 1 "Grundeinstellung erfolgt" ;
VAL_ 917 LWR_AFS_Parametrisierung 0 "Parametrisierung nicht erfolgt" 1 "Parametrisierung erfolgt" ;
VAL_ 917 LWR_Initialisierungslauf 0 "Initialisierungslauf nicht erfolgt" 1 "Initialisierungslauf erfolgt" ;
VAL_ 917 LWR_Sicherheitsposition_li 0 "inaktiv" 1 "aktiv" ;
VAL_ 917 LWR_Modus 0 "LWR statisch" 1 "LWR dynamisch" ;
VAL_ 1153 ZR_LoGeWa_Event_Kombiwarnung 0 "Init" 1 "Unfall" 2 "Traktionsverlust" 3 "Panne" 4 "Sichtbehinderung" 5 "Aquaplaning" 6 "EEBL" 7 "SEF_stat" 8 "SEF_dyn_allgemein" 9 "SEF_dyn_vorne" 10 "SEF_dyn_hinten" 11 "SEF_dyn_links" 12 "SEF_dyn_rechts" 13 "Stauende" ;
VAL_ 1153 Nav_FoD_Status 0 "Init" 1 "Nav_permanently_available" 2 "FoD_Nav_not_activated" 3 "FoD_Nav_activated" 4 "R4N_Nav_not_activated" ;
VAL_ 1153 MIB_Tongenerator_PH_verfuegbar 0 "Tongenerator_nicht_verfuegbar" 1 "Tongenerator_vorne_verfuegbar" 2 "Tongenerator_hinten_verfuegbar" 3 "Tongenerator_gesamt_verfuegbar" 4 "Tongenerator_im_AMP" ;
VAL_ 1153 DSSS_Warning 0 "No_Warning" 1 "Red_traffic_light_guidance" 2 "Stop_sign_warning" 3 "Rear_end_collision_avoidance_warning" 4 "Intersection_collision_avoidance_warning_right" 5 "Intersection_collision_avoidance_warning_left" 6 "turn_right_collision_avoidance" 7 "turn_left_collision_avoidance" 8 "pedestrian_crossing_right" 9 "pedestrian_crossing_left" 10 "bicycle_collision_right" 11 "bicycle_collision_left" ;
VAL_ 1153 ZR_Kindersicherung_RSE 0 "inaktiv" 1 "aktiv" ;
VAL_ 1153 ZR_RSE_aktivieren 0 "inaktiv" 1 "aktiv" ;
VAL_ 1153 MMI_SDS_aktiv 0 "inaktiv" 1 "aktiv" ;
VAL_ 1153 MU_SecondDisplay 0 "Init" 1 "gueltige_Karte" 2 "ungueltiges_Signal" 3 "Nicht_Verbaut" ;
VAL_ 1153 MMI_Telefon_aktiv 0 "Telefongespraech_nicht_aktiv" 1 "Telefongespraech_aktiv" ;
VAL_ 1153 MMI_Gurt_Mic_ref 0 "Downlink_inaktiv" 1 "Downlink_aktiv" ;
VAL_ 1153 ZR_Sta_Inszenierung 0 "Init" 1 "Inszenierung_deaktiviert" 2 "Inszenierung_Start" 3 "Inszenierung_Stop" ;
VAL_ 1153 MMI_Gauges_active 0 "gauges_inactive" 1 "gauges_active" ;
VAL_ 1153 ZR_MXB_Manoever_Ansage 0 "keine_Ansage" 1 "Ansage_ohne_Richtung" 2 "Ansage_rechte_Richtung" 3 "Ansage_linke_Richtung" ;
VAL_ 1153 ZR_LAPP_Sondermodus_Status 0 "keine_Anforderung" 1 "Sondermodus_aktiv" 2 "Aktivierung_nicht_moeglich" ;
VAL_ 1153 MMI_StartStopp_Info 0 "Stoppfreigabe" 1 "Stoppverbot" 2 "Startanforderung" 3 "Fehler" ;
VAL_ 1153 ZR_Parken_Sondermodus 0 "Init" 1 "Sondermodus_aktiv" 2 "Sondermodus_nicht_verfuegbar" 3 "WLAN_aus" 4 "WLAN_auscodiert" 15 "keine_WLAN_HW" ;
VAL_ 1153 ZR_Rundenbewertung 0 "Bewertung_nicht_aktiv" 1 "langsamer" 2 "gleich_schnell" 3 "schneller" 4 "reserviert" 5 "reserviert" 6 "reserviert" 7 "reserviert" 8 "reserviert" 9 "reserviert" 10 "reserviert" 11 "reserviert" 12 "reserviert" 13 "reserviert" 14 "Init" 15 "Funktion_nicht_verbaut" ;
VAL_ 1153 ZR_Rundenfortschritt 254 "Init" 255 "Funktion_nicht_verbaut" ;
VAL_ 2527679771 ZR_ECR_SwitchMode_HMI_Anf 0 "No_change" 1 "Auto" 2 "Manual" 3 "Init" 7 "Fehler" ;
VAL_ 2527679771 ZR_ECR_LevelMode_HMI_Anf 0 "No_change" 1 "Off" 2 "Level_1" 3 "Level_2" 4 "Clear" 7 "Fehler" ;
VAL_ 2527679771 ZR_Slider_soll_01 127 "Init" ;
VAL_ 2527679771 ZR_Slider_soll_02 127 "Init" ;
VAL_ 2527679771 ZR_Slider_soll_03 127 "Init" ;
VAL_ 2527679771 LIMU_Aero_Selec_HMI_Anf 0 "Init" 1 "Button_1" 2 "Button_2" 3 "Button_3" ;
VAL_ 2527679771 LIMU_BAR_Mode_Switch_HMI_Anf 0 "Not_pressed" 1 "Pressed" ;
VAL_ 2527679771 LIMU_Confirmation_HMI_Anf 0 "Not_pressed" 1 "Pressed" ;
VAL_ 2527679771 LIMU_DR_Select_HMI_Anf 0 "Init" 1 "Button_1" 2 "Button_2" 3 "Button_3" ;
VAL_ 2527679771 LIMU_Reset_switch_HMI_Anf 0 "Not_pressed" 1 "Pressed" ;
VAL_ 1639 BFS_Fond_Bed_Ack 0 "nicht aktiviert" 1 "aktiviert" ;
VAL_ 1639 BFS_Lehne_nicht_verriegelt 0 "keine Anzeige" 1 "Lehne_nicht_verriegelt" ;
VAL_ 1639 BFS_Klapptisch_offen 0 "inaktiv" 1 "aktiv" ;
VAL_ 1639 BFS_Gurtbringer_Sperre 0 "Gurtzubringer_freigegeben" 1 "Gurtzubringer_gesperrt" ;
VAL_ 1639 BFS_Sitzsym_Fahrt_aktiv 0 "inaktiv" 1 "aktiv" ;
VAL_ 1639 BFS_Sitzfahrt_aktiv 0 "Init" 1 "Sitz in Bewegung" ;
VAL_ 1639 BFS_SLV_aktiv 0 "nicht_aktiv" 1 "Sitzlaengsverstellung aktiv" ;
VAL_ 1639 BFS_SHV_aktiv 0 "nicht_aktiv" 1 "Sitzhoehenverstellung aktiv" ;
VAL_ 1639 BFS_LNV_aktiv 0 "inaktiv" 1 "aktiv" ;
VAL_ 1639 BFS_SNV_aktiv 0 "nicht_aktiv" 1 "Sitzneigungsverstellung aktiv" ;
VAL_ 1639 BFS_KSV_aktiv 0 "nicht_aktiv" 1 "Kopfstuetzenverstellung aktiv" ;
VAL_ 1639 BFS_LKV_aktiv 0 "nicht_aktiv" 1 "aktiv" ;
VAL_ 1639 BFS_STV_aktiv 0 "inaktiv" 1 "Sitztiefeverstellung aktiv" ;
VAL_ 1639 BFS_LHV_aktiv 0 "inaktiv" 1 "aktiv" ;
VAL_ 1639 BFS_LWV_aktiv 0 "nicht_aktiv" 1 "aktiv" ;
VAL_ 1639 BFS_GHV_aktiv 0 "nicht_aktiv" 1 "Gurthoehe Verstellung aktiv" ;
VAL_ 1639 BFS_KSS_Fahrt_aktiv 0 "nicht_aktiv" 1 "Komfortseitensichtfahrt aktiv" ;
VAL_ 1639 BFS_MMB_lokal_Stop 0 "kein_Abbruch" 1 "lokaler_Abbruch" ;
VAL_ 1639 BFS_Ruhestellung_Status 0 "inakiv" 1 "Ruhestellung_aktiv" ;
VAL_ 1639 BFS_Seat_Locked 0 "nicht_gesperrt" 1 "gesperrt" ;
VAL_ 1639 BFS_MMB_storage 0 "keine Zuweisung" 1 "P1/FP1 Pos Zuweisung" 2 "P2/FP2 Pos Zuweisung" 3 "P3/FP3 Pos Zuweisung" 4 "P4/FP4 Pos Zuweisung an den im System aktiven Funkschlüssel/FPI ID über MMI" 5 "FS1" 6 "FS2" 7 "FS3" 8 "FS4" ;
VAL_ 1639 BFS_MMB_tipp 0 "kein_Tippbetrieb" 1 "Tippbetrieb" ;
VAL_ 1639 BFS_MMB_tast 0 "kein_Tastbetrieb" 1 "Tastbetrieb" ;
VAL_ 1639 BFS_MMB_store_LED_on 0 "LED_aus" 1 "LED_ein" ;
VAL_ 1639 BFS_MMB_storage_beep 0 "beep_aus" 1 "beep ein" ;
VAL_ 1639 BFS_MMB_store 0 "nicht speichern" 1 "speichern" ;
VAL_ 1639 BFS_MMB_glob_stop 0 "kein globaler Abbruch" 1 "globaler Abbruch" ;
VAL_ 1639 BFS_FSV_ausgeklappt 0 "FSV_nicht_ausgeklappt" 1 "FSV_ausgeklappt" ;
VAL_ 1639 BFS_NFA_einfahren 0 "uneingeschraenkt" 1 "NFA_einfahren" ;
VAL_ 1639 BFS_Kollisionsbereich_Windschott 0 "Ausserhalb_Kollisionsbereich" 1 "Innerhalb_Kollisionsbereich" ;
VAL_ 1639 BFS_Kollisionsgefahr_Windschott 0 "keine_Kombimeldung_anzeigen" 1 "Kombimeldung_anzeigen" ;
